VERSION "created by canmatrix"

NS_ :

BS_:

BU_: RR LR ADCU

BO_ 521 LR_Object_16_17: 64 LR
 SG_ AabsX_Obj_16 : 16|9@0+ (0.125,-31.875) [-31.875|32] "m/s^2"  ADCU
 SG_ AabsX_Obj_17 : 248|9@0+ (0.125,-31.875) [-31.875|32] "m/s^2"  ADCU
 SG_ AabsXStd_Obj_16 : 89|7@0+ (0.25,0) [0|31.75] "m/s^2"  ADCU
 SG_ AabsXStd_Obj_17 : 321|7@0+ (0.25,0) [0|31.75] "m/s^2"  ADCU
 SG_ AabsY_Obj_16 : 48|9@0+ (0.125,-31.875) [-31.875|32] "m/s^2"  ADCU
 SG_ AabsY_Obj_17 : 280|9@0+ (0.125,-31.875) [-31.875|32] "m/s^2"  ADCU
 SG_ AabsYStd_Obj_16 : 111|8@0+ (0.25,0) [0|63.75] "m/s^2"  ADCU
 SG_ AabsYStd_Obj_17 : 343|8@0+ (0.25,0) [0|63.75] "m/s^2"  ADCU
 SG_ ClassConf_Obj_16 : 119|7@0+ (1,0) [0|127] "%"  ADCU
 SG_ ClassConf_Obj_17 : 351|7@0+ (1,0) [0|127] "%"  ADCU
 SG_ Classification_Obj_16 : 98|3@0+ (1,0) [0|7] ""  ADCU
 SG_ Classification_Obj_17 : 330|3@0+ (1,0) [0|7] ""  ADCU
 SG_ CRC16_Checksum_Obj_16_17 : 503|16@0+ (1,0) [0|65535] ""  ADCU
 SG_ DistX_Obj_16 : 7|12@0+ (0.1,-200) [-200|209.5] "m"  ADCU
 SG_ DistX_Obj_17 : 239|12@0+ (0.1,-200) [-200|209.5] "m"  ADCU
 SG_ DistXStd_Obj_16 : 71|8@0+ (0.05,0) [0|12.75] "m"  ADCU
 SG_ DistXStd_Obj_17 : 303|8@0+ (0.05,0) [0|12.75] "m"  ADCU
 SG_ DistY_Obj_16 : 39|12@0+ (0.1,-200) [-200|209.5] "m"  ADCU
 SG_ DistY_Obj_17 : 271|12@0+ (0.1,-200) [-200|209.5] "m"  ADCU
 SG_ DistYStd_Obj_16 : 79|8@0+ (0.1,0) [0|25.5] "m"  ADCU
 SG_ DistYStd_Obj_17 : 311|8@0+ (0.1,0) [0|25.5] "m"  ADCU
 SG_ DynConf_Obj_16 : 121|7@0+ (1,0) [0|127] "%"  ADCU
 SG_ DynConf_Obj_17 : 353|7@0+ (1,0) [0|127] "%"  ADCU
 SG_ DynProp_Obj_16 : 130|3@0+ (1,0) [0|7] ""  ADCU
 SG_ DynProp_Obj_17 : 362|3@0+ (1,0) [0|7] ""  ADCU
 SG_ ID_Obj_16 : 209|8@0+ (1,0) [0|255] ""  ADCU
 SG_ ID_Obj_17 : 441|8@0+ (1,0) [0|255] ""  ADCU
 SG_ Length_Obj_16 : 136|7@0+ (0.2,0) [0|25.4] "m"  ADCU
 SG_ Length_Obj_17 : 368|7@0+ (0.2,0) [0|25.4] "m"  ADCU
 SG_ LifeCycle_Obj_16 : 193|16@0+ (1,0) [0|65535] ""  ADCU
 SG_ LifeCycle_Obj_17 : 425|16@0+ (1,0) [0|65535] ""  ADCU
 SG_ MaintenanceState_Obj_16 : 145|2@0+ (1,0) [0|3] ""  ADCU
 SG_ MaintenanceState_Obj_17 : 377|2@0+ (1,0) [0|3] ""  ADCU
 SG_ MicroDopplerFlag_16 : 472|1@0+ (1,0) [0|1] ""  ADCU
 SG_ MicroDopplerFlag_17 : 480|1@0+ (1,0) [0|1] ""  ADCU
 SG_ MirrorProb_Obj_16 : 143|7@0+ (1,0) [0|127] "%"  ADCU
 SG_ MirrorProb_Obj_17 : 375|7@0+ (1,0) [0|127] "%"  ADCU
 SG_ MsgCounter_Obj_16_17 : 495|8@0+ (1,0) [0|255] ""  ADCU
 SG_ ObstacleProb_Obj_16 : 479|7@0+ (1,0) [0|127] "%"  ADCU
 SG_ ObstacleProb_Obj_17 : 487|7@0+ (1,0) [0|127] "%"  ADCU
 SG_ Orientation_Obj_16 : 175|10@0+ (0.01,-5.11) [-5.11|5.12] "rad"  ADCU
 SG_ Orientation_Obj_17 : 407|10@0+ (0.01,-5.11) [-5.11|5.12] "rad"  ADCU
 SG_ OrientationStd_Obj_16 : 471|4@0+ (0.002,0) [0|0.03] "rad"  ADCU
 SG_ OrientationStd_Obj_17 : 467|4@0+ (0.002,0) [0|0.03] "rad"  ADCU
 SG_ ProbOfExist_Obj_16 : 112|7@0+ (1,0) [0|127] "%"  ADCU
 SG_ ProbOfExist_Obj_17 : 344|7@0+ (1,0) [0|127] "%"  ADCU
 SG_ RCS_Obj_16 : 152|9@0+ (0.2,-51.1) [-51.1|51.1] "dBsm"  ADCU
 SG_ RCS_Obj_17 : 384|9@0+ (0.2,-51.1) [-51.1|51.1] "dBsm"  ADCU
 SG_ RefPoint_Obj_16 : 217|4@0+ (1,0) [0|15] ""  ADCU
 SG_ RefPoint_Obj_17 : 449|4@0+ (1,0) [0|15] ""  ADCU
 SG_ VabsX_Obj_16 : 11|11@0+ (0.125,-128) [-128|127.875] "m/s"  ADCU
 SG_ VabsX_Obj_17 : 243|11@0+ (0.125,-128) [-128|127.875] "m/s"  ADCU
 SG_ VabsXStd_Obj_16 : 87|7@0+ (0.1,0) [0|12.7] "m/s"  ADCU
 SG_ VabsXStd_Obj_17 : 319|7@0+ (0.1,0) [0|12.7] "m/s"  ADCU
 SG_ VabsY_Obj_16 : 43|11@0+ (0.125,-128) [-128|127.875] "m/s"  ADCU
 SG_ VabsY_Obj_17 : 275|11@0+ (0.125,-128) [-128|127.875] "m/s"  ADCU
 SG_ VabsYStd_Obj_16 : 80|7@0+ (0.2,0) [0|25.4] "m/s"  ADCU
 SG_ VabsYStd_Obj_17 : 312|7@0+ (0.2,0) [0|25.4] "m/s"  ADCU
 SG_ Valid_Obj_16 : 229|1@0+ (1,0) [0|1] ""  ADCU
 SG_ Valid_Obj_17 : 461|1@0+ (1,0) [0|1] ""  ADCU
 SG_ Width_Obj_16 : 159|7@0+ (0.2,0) [0|25.4] "m"  ADCU
 SG_ Width_Obj_17 : 391|7@0+ (0.2,0) [0|25.4] "m"  ADCU
 SG_ YawRateAbs_Obj_16 : 181|10@0+ (0.001,-0.511) [-0.511|0.512] "rad/s"  ADCU
 SG_ YawRateAbs_Obj_17 : 413|10@0+ (0.001,-0.511) [-0.511|0.512] "rad/s"  ADCU
 SG_ YawRateAbsStd_Obj_16 : 187|10@0+ (0.0001,0) [0|0.1023] "rad/s"  ADCU
 SG_ YawRateAbsStd_Obj_17 : 419|10@0+ (0.0001,0) [0|0.1023] "rad/s"  ADCU

BO_ 522 LR_Object_18_19: 64 LR
 SG_ AabsX_Obj_18 : 16|9@0+ (0.125,-31.875) [-31.875|32] "m/s^2"  ADCU
 SG_ AabsX_Obj_19 : 248|9@0+ (0.125,-31.875) [-31.875|32] "m/s^2"  ADCU
 SG_ AabsXStd_Obj_18 : 89|7@0+ (0.25,0) [0|31.75] "m/s^2"  ADCU
 SG_ AabsXStd_Obj_19 : 321|7@0+ (0.25,0) [0|31.75] "m/s^2"  ADCU
 SG_ AabsY_Obj_18 : 48|9@0+ (0.125,-31.875) [-31.875|32] "m/s^2"  ADCU
 SG_ AabsY_Obj_19 : 280|9@0+ (0.125,-31.875) [-31.875|32] "m/s^2"  ADCU
 SG_ AabsYStd_Obj_18 : 111|8@0+ (0.25,0) [0|63.75] "m/s^2"  ADCU
 SG_ AabsYStd_Obj_19 : 343|8@0+ (0.25,0) [0|63.75] "m/s^2"  ADCU
 SG_ ClassConf_Obj_18 : 119|7@0+ (1,0) [0|127] "%"  ADCU
 SG_ ClassConf_Obj_19 : 351|7@0+ (1,0) [0|127] "%"  ADCU
 SG_ Classification_Obj_18 : 98|3@0+ (1,0) [0|7] ""  ADCU
 SG_ Classification_Obj_19 : 330|3@0+ (1,0) [0|7] ""  ADCU
 SG_ CRC16_Checksum_Obj_18_19 : 503|16@0+ (1,0) [0|65535] ""  ADCU
 SG_ DistX_Obj_18 : 7|12@0+ (0.1,-200) [-200|209.5] "m"  ADCU
 SG_ DistX_Obj_19 : 239|12@0+ (0.1,-200) [-200|209.5] "m"  ADCU
 SG_ DistXStd_Obj_18 : 71|8@0+ (0.05,0) [0|12.75] "m"  ADCU
 SG_ DistXStd_Obj_19 : 303|8@0+ (0.05,0) [0|12.75] "m"  ADCU
 SG_ DistY_Obj_18 : 39|12@0+ (0.1,-200) [-200|209.5] "m"  ADCU
 SG_ DistY_Obj_19 : 271|12@0+ (0.1,-200) [-200|209.5] "m"  ADCU
 SG_ DistYStd_Obj_18 : 79|8@0+ (0.1,0) [0|25.5] "m"  ADCU
 SG_ DistYStd_Obj_19 : 311|8@0+ (0.1,0) [0|25.5] "m"  ADCU
 SG_ DynConf_Obj_18 : 121|7@0+ (1,0) [0|127] "%"  ADCU
 SG_ DynConf_Obj_19 : 353|7@0+ (1,0) [0|127] "%"  ADCU
 SG_ DynProp_Obj_18 : 130|3@0+ (1,0) [0|7] ""  ADCU
 SG_ DynProp_Obj_19 : 362|3@0+ (1,0) [0|7] ""  ADCU
 SG_ ID_Obj_18 : 209|8@0+ (1,0) [0|255] ""  ADCU
 SG_ ID_Obj_19 : 441|8@0+ (1,0) [0|255] ""  ADCU
 SG_ Length_Obj_18 : 136|7@0+ (0.2,0) [0|25.4] "m"  ADCU
 SG_ Length_Obj_19 : 368|7@0+ (0.2,0) [0|25.4] "m"  ADCU
 SG_ LifeCycle_Obj_18 : 193|16@0+ (1,0) [0|65535] ""  ADCU
 SG_ LifeCycle_Obj_19 : 425|16@0+ (1,0) [0|65535] ""  ADCU
 SG_ MaintenanceState_Obj_18 : 145|2@0+ (1,0) [0|3] ""  ADCU
 SG_ MaintenanceState_Obj_19 : 377|2@0+ (1,0) [0|3] ""  ADCU
 SG_ MicroDopplerFlag_18 : 472|1@0+ (1,0) [0|1] ""  ADCU
 SG_ MicroDopplerFlag_19 : 480|1@0+ (1,0) [0|1] ""  ADCU
 SG_ MirrorProb_Obj_18 : 143|7@0+ (1,0) [0|127] "%"  ADCU
 SG_ MirrorProb_Obj_19 : 375|7@0+ (1,0) [0|127] "%"  ADCU
 SG_ MsgCounter_Obj_18_19 : 495|8@0+ (1,0) [0|255] ""  ADCU
 SG_ ObstacleProb_Obj_18 : 479|7@0+ (1,0) [0|127] "%"  ADCU
 SG_ ObstacleProb_Obj_19 : 487|7@0+ (1,0) [0|127] "%"  ADCU
 SG_ Orientation_Obj_18 : 175|10@0+ (0.01,-5.11) [-5.11|5.12] "rad"  ADCU
 SG_ Orientation_Obj_19 : 407|10@0+ (0.01,-5.11) [-5.11|5.12] "rad"  ADCU
 SG_ OrientationStd_Obj_18 : 471|4@0+ (0.002,0) [0|0.03] "rad"  ADCU
 SG_ OrientationStd_Obj_19 : 467|4@0+ (0.002,0) [0|0.03] "rad"  ADCU
 SG_ ProbOfExist_Obj_18 : 112|7@0+ (1,0) [0|127] "%"  ADCU
 SG_ ProbOfExist_Obj_19 : 344|7@0+ (1,0) [0|127] "%"  ADCU
 SG_ RCS_Obj_18 : 152|9@0+ (0.2,-51.1) [-51.1|51.1] "dBsm"  ADCU
 SG_ RCS_Obj_19 : 384|9@0+ (0.2,-51.1) [-51.1|51.1] "dBsm"  ADCU
 SG_ RefPoint_Obj_18 : 217|4@0+ (1,0) [0|15] ""  ADCU
 SG_ RefPoint_Obj_19 : 449|4@0+ (1,0) [0|15] ""  ADCU
 SG_ VabsX_Obj_18 : 11|11@0+ (0.125,-128) [-128|127.875] "m/s"  ADCU
 SG_ VabsX_Obj_19 : 243|11@0+ (0.125,-128) [-128|127.875] "m/s"  ADCU
 SG_ VabsXStd_Obj_18 : 87|7@0+ (0.1,0) [0|12.7] "m/s"  ADCU
 SG_ VabsXStd_Obj_19 : 319|7@0+ (0.1,0) [0|12.7] "m/s"  ADCU
 SG_ VabsY_Obj_18 : 43|11@0+ (0.125,-128) [-128|127.875] "m/s"  ADCU
 SG_ VabsY_Obj_19 : 275|11@0+ (0.125,-128) [-128|127.875] "m/s"  ADCU
 SG_ VabsYStd_Obj_18 : 80|7@0+ (0.2,0) [0|25.4] "m/s"  ADCU
 SG_ VabsYStd_Obj_19 : 312|7@0+ (0.2,0) [0|25.4] "m/s"  ADCU
 SG_ Valid_Obj_18 : 229|1@0+ (1,0) [0|1] ""  ADCU
 SG_ Valid_Obj_19 : 461|1@0+ (1,0) [0|1] ""  ADCU
 SG_ Width_Obj_18 : 159|7@0+ (0.2,0) [0|25.4] "m"  ADCU
 SG_ Width_Obj_19 : 391|7@0+ (0.2,0) [0|25.4] "m"  ADCU
 SG_ YawRateAbs_Obj_18 : 181|10@0+ (0.001,-0.511) [-0.511|0.512] "rad/s"  ADCU
 SG_ YawRateAbs_Obj_19 : 413|10@0+ (0.001,-0.511) [-0.511|0.512] "rad/s"  ADCU
 SG_ YawRateAbsStd_Obj_18 : 187|10@0+ (0.0001,0) [0|0.1023] "rad/s"  ADCU
 SG_ YawRateAbsStd_Obj_19 : 419|10@0+ (0.0001,0) [0|0.1023] "rad/s"  ADCU

BO_ 523 LR_Object_20_21: 64 LR
 SG_ AabsX_Obj_20 : 16|9@0+ (0.125,-31.875) [-31.875|32] "m/s^2"  ADCU
 SG_ AabsX_Obj_21 : 248|9@0+ (0.125,-31.875) [-31.875|32] "m/s^2"  ADCU
 SG_ AabsXStd_Obj_20 : 89|7@0+ (0.25,0) [0|31.75] "m/s^2"  ADCU
 SG_ AabsXStd_Obj_21 : 321|7@0+ (0.25,0) [0|31.75] "m/s^2"  ADCU
 SG_ AabsY_Obj_20 : 48|9@0+ (0.125,-31.875) [-31.875|32] "m/s^2"  ADCU
 SG_ AabsY_Obj_21 : 280|9@0+ (0.125,-31.875) [-31.875|32] "m/s^2"  ADCU
 SG_ AabsYStd_Obj_20 : 111|8@0+ (0.25,0) [0|63.75] "m/s^2"  ADCU
 SG_ AabsYStd_Obj_21 : 343|8@0+ (0.25,0) [0|63.75] "m/s^2"  ADCU
 SG_ ClassConf_Obj_20 : 119|7@0+ (1,0) [0|127] "%"  ADCU
 SG_ ClassConf_Obj_21 : 351|7@0+ (1,0) [0|127] "%"  ADCU
 SG_ Classification_Obj_20 : 98|3@0+ (1,0) [0|7] ""  ADCU
 SG_ Classification_Obj_21 : 330|3@0+ (1,0) [0|7] ""  ADCU
 SG_ CRC16_Checksum_Obj_20_21 : 503|16@0+ (1,0) [0|65535] ""  ADCU
 SG_ DistX_Obj_20 : 7|12@0+ (0.1,-200) [-200|209.5] "m"  ADCU
 SG_ DistX_Obj_21 : 239|12@0+ (0.1,-200) [-200|209.5] "m"  ADCU
 SG_ DistXStd_Obj_20 : 71|8@0+ (0.05,0) [0|12.75] "m"  ADCU
 SG_ DistXStd_Obj_21 : 303|8@0+ (0.05,0) [0|12.75] "m"  ADCU
 SG_ DistY_Obj_20 : 39|12@0+ (0.1,-200) [-200|209.5] "m"  ADCU
 SG_ DistY_Obj_21 : 271|12@0+ (0.1,-200) [-200|209.5] "m"  ADCU
 SG_ DistYStd_Obj_20 : 79|8@0+ (0.1,0) [0|25.5] "m"  ADCU
 SG_ DistYStd_Obj_21 : 311|8@0+ (0.1,0) [0|25.5] "m"  ADCU
 SG_ DynConf_Obj_20 : 121|7@0+ (1,0) [0|127] "%"  ADCU
 SG_ DynConf_Obj_21 : 353|7@0+ (1,0) [0|127] "%"  ADCU
 SG_ DynProp_Obj_20 : 130|3@0+ (1,0) [0|7] ""  ADCU
 SG_ DynProp_Obj_21 : 362|3@0+ (1,0) [0|7] ""  ADCU
 SG_ ID_Obj_20 : 209|8@0+ (1,0) [0|255] ""  ADCU
 SG_ ID_Obj_21 : 441|8@0+ (1,0) [0|255] ""  ADCU
 SG_ Length_Obj_20 : 136|7@0+ (0.2,0) [0|25.4] "m"  ADCU
 SG_ Length_Obj_21 : 368|7@0+ (0.2,0) [0|25.4] "m"  ADCU
 SG_ LifeCycle_Obj_20 : 193|16@0+ (1,0) [0|65535] ""  ADCU
 SG_ LifeCycle_Obj_21 : 425|16@0+ (1,0) [0|65535] ""  ADCU
 SG_ MaintenanceState_Obj_20 : 145|2@0+ (1,0) [0|3] ""  ADCU
 SG_ MaintenanceState_Obj_21 : 377|2@0+ (1,0) [0|3] ""  ADCU
 SG_ MicroDopplerFlag_20 : 472|1@0+ (1,0) [0|1] ""  ADCU
 SG_ MicroDopplerFlag_21 : 480|1@0+ (1,0) [0|1] ""  ADCU
 SG_ MirrorProb_Obj_20 : 143|7@0+ (1,0) [0|127] "%"  ADCU
 SG_ MirrorProb_Obj_21 : 375|7@0+ (1,0) [0|127] "%"  ADCU
 SG_ MsgCounter_Obj_20_21 : 495|8@0+ (1,0) [0|255] ""  ADCU
 SG_ ObstacleProb_Obj_20 : 479|7@0+ (1,0) [0|127] "%"  ADCU
 SG_ ObstacleProb_Obj_21 : 487|7@0+ (1,0) [0|127] "%"  ADCU
 SG_ Orientation_Obj_20 : 175|10@0+ (0.01,-5.11) [-5.11|5.12] "rad"  ADCU
 SG_ Orientation_Obj_21 : 407|10@0+ (0.01,-5.11) [-5.11|5.12] "rad"  ADCU
 SG_ OrientationStd_Obj_20 : 471|4@0+ (0.002,0) [0|0.03] "rad"  ADCU
 SG_ OrientationStd_Obj_21 : 467|4@0+ (0.002,0) [0|0.03] "rad"  ADCU
 SG_ ProbOfExist_Obj_20 : 112|7@0+ (1,0) [0|127] "%"  ADCU
 SG_ ProbOfExist_Obj_21 : 344|7@0+ (1,0) [0|127] "%"  ADCU
 SG_ RCS_Obj_20 : 152|9@0+ (0.2,-51.1) [-51.1|51.1] "dBsm"  ADCU
 SG_ RCS_Obj_21 : 384|9@0+ (0.2,-51.1) [-51.1|51.1] "dBsm"  ADCU
 SG_ RefPoint_Obj_20 : 217|4@0+ (1,0) [0|15] ""  ADCU
 SG_ RefPoint_Obj_21 : 449|4@0+ (1,0) [0|15] ""  ADCU
 SG_ VabsX_Obj_20 : 11|11@0+ (0.125,-128) [-128|127.875] "m/s"  ADCU
 SG_ VabsX_Obj_21 : 243|11@0+ (0.125,-128) [-128|127.875] "m/s"  ADCU
 SG_ VabsXStd_Obj_20 : 87|7@0+ (0.1,0) [0|12.7] "m/s"  ADCU
 SG_ VabsXStd_Obj_21 : 319|7@0+ (0.1,0) [0|12.7] "m/s"  ADCU
 SG_ VabsY_Obj_20 : 43|11@0+ (0.125,-128) [-128|127.875] "m/s"  ADCU
 SG_ VabsY_Obj_21 : 275|11@0+ (0.125,-128) [-128|127.875] "m/s"  ADCU
 SG_ VabsYStd_Obj_20 : 80|7@0+ (0.2,0) [0|25.4] "m/s"  ADCU
 SG_ VabsYStd_Obj_21 : 312|7@0+ (0.2,0) [0|25.4] "m/s"  ADCU
 SG_ Valid_Obj_20 : 229|1@0+ (1,0) [0|1] ""  ADCU
 SG_ Valid_Obj_21 : 461|1@0+ (1,0) [0|1] ""  ADCU
 SG_ Width_Obj_20 : 159|7@0+ (0.2,0) [0|25.4] "m"  ADCU
 SG_ Width_Obj_21 : 391|7@0+ (0.2,0) [0|25.4] "m"  ADCU
 SG_ YawRateAbs_Obj_20 : 181|10@0+ (0.001,-0.511) [-0.511|0.512] "rad/s"  ADCU
 SG_ YawRateAbs_Obj_21 : 413|10@0+ (0.001,-0.511) [-0.511|0.512] "rad/s"  ADCU
 SG_ YawRateAbsStd_Obj_20 : 187|10@0+ (0.0001,0) [0|0.1023] "rad/s"  ADCU
 SG_ YawRateAbsStd_Obj_21 : 419|10@0+ (0.0001,0) [0|0.1023] "rad/s"  ADCU

BO_ 524 LR_Object_22_23: 64 LR
 SG_ AabsX_Obj_22 : 16|9@0+ (0.125,-31.875) [-31.875|32] "m/s^2"  ADCU
 SG_ AabsX_Obj_23 : 248|9@0+ (0.125,-31.875) [-31.875|32] "m/s^2"  ADCU
 SG_ AabsXStd_Obj_22 : 89|7@0+ (0.25,0) [0|31.75] "m/s^2"  ADCU
 SG_ AabsXStd_Obj_23 : 321|7@0+ (0.25,0) [0|31.75] "m/s^2"  ADCU
 SG_ AabsY_Obj_22 : 48|9@0+ (0.125,-31.875) [-31.875|32] "m/s^2"  ADCU
 SG_ AabsY_Obj_23 : 280|9@0+ (0.125,-31.875) [-31.875|32] "m/s^2"  ADCU
 SG_ AabsYStd_Obj_22 : 111|8@0+ (0.25,0) [0|63.75] "m/s^2"  ADCU
 SG_ AabsYStd_Obj_23 : 343|8@0+ (0.25,0) [0|63.75] "m/s^2"  ADCU
 SG_ ClassConf_Obj_22 : 119|7@0+ (1,0) [0|127] "%"  ADCU
 SG_ ClassConf_Obj_23 : 351|7@0+ (1,0) [0|127] "%"  ADCU
 SG_ Classification_Obj_22 : 98|3@0+ (1,0) [0|7] ""  ADCU
 SG_ Classification_Obj_23 : 330|3@0+ (1,0) [0|7] ""  ADCU
 SG_ CRC16_Checksum_Obj_22_23 : 503|16@0+ (1,0) [0|65535] ""  ADCU
 SG_ DistX_Obj_22 : 7|12@0+ (0.1,-200) [-200|209.5] "m"  ADCU
 SG_ DistX_Obj_23 : 239|12@0+ (0.1,-200) [-200|209.5] "m"  ADCU
 SG_ DistXStd_Obj_22 : 71|8@0+ (0.05,0) [0|12.75] "m"  ADCU
 SG_ DistXStd_Obj_23 : 303|8@0+ (0.05,0) [0|12.75] "m"  ADCU
 SG_ DistY_Obj_22 : 39|12@0+ (0.1,-200) [-200|209.5] "m"  ADCU
 SG_ DistY_Obj_23 : 271|12@0+ (0.1,-200) [-200|209.5] "m"  ADCU
 SG_ DistYStd_Obj_22 : 79|8@0+ (0.1,0) [0|25.5] "m"  ADCU
 SG_ DistYStd_Obj_23 : 311|8@0+ (0.1,0) [0|25.5] "m"  ADCU
 SG_ DynConf_Obj_22 : 121|7@0+ (1,0) [0|127] "%"  ADCU
 SG_ DynConf_Obj_23 : 353|7@0+ (1,0) [0|127] "%"  ADCU
 SG_ DynProp_Obj_22 : 130|3@0+ (1,0) [0|7] ""  ADCU
 SG_ DynProp_Obj_23 : 362|3@0+ (1,0) [0|7] ""  ADCU
 SG_ ID_Obj_22 : 209|8@0+ (1,0) [0|255] ""  ADCU
 SG_ ID_Obj_23 : 441|8@0+ (1,0) [0|255] ""  ADCU
 SG_ Length_Obj_22 : 136|7@0+ (0.2,0) [0|25.4] "m"  ADCU
 SG_ Length_Obj_23 : 368|7@0+ (0.2,0) [0|25.4] "m"  ADCU
 SG_ LifeCycle_Obj_22 : 193|16@0+ (1,0) [0|65535] ""  ADCU
 SG_ LifeCycle_Obj_23 : 425|16@0+ (1,0) [0|65535] ""  ADCU
 SG_ MaintenanceState_Obj_22 : 145|2@0+ (1,0) [0|3] ""  ADCU
 SG_ MaintenanceState_Obj_23 : 377|2@0+ (1,0) [0|3] ""  ADCU
 SG_ MicroDopplerFlag_22 : 472|1@0+ (1,0) [0|1] ""  ADCU
 SG_ MicroDopplerFlag_23 : 480|1@0+ (1,0) [0|1] ""  ADCU
 SG_ MirrorProb_Obj_22 : 143|7@0+ (1,0) [0|127] "%"  ADCU
 SG_ MirrorProb_Obj_23 : 375|7@0+ (1,0) [0|127] "%"  ADCU
 SG_ MsgCounter_Obj_00_23 : 495|8@0+ (1,0) [0|255] ""  ADCU
 SG_ ObstacleProb_Obj_22 : 479|7@0+ (1,0) [0|127] "%"  ADCU
 SG_ ObstacleProb_Obj_23 : 487|7@0+ (1,0) [0|127] "%"  ADCU
 SG_ Orientation_Obj_22 : 175|10@0+ (0.01,-5.11) [-5.11|5.12] "rad"  ADCU
 SG_ Orientation_Obj_23 : 407|10@0+ (0.01,-5.11) [-5.11|5.12] "rad"  ADCU
 SG_ OrientationStd_Obj_22 : 471|4@0+ (0.002,0) [0|0.03] "rad"  ADCU
 SG_ OrientationStd_Obj_23 : 467|4@0+ (0.002,0) [0|0.03] "rad"  ADCU
 SG_ ProbOfExist_Obj_22 : 112|7@0+ (1,0) [0|127] "%"  ADCU
 SG_ ProbOfExist_Obj_23 : 344|7@0+ (1,0) [0|127] "%"  ADCU
 SG_ RCS_Obj_22 : 152|9@0+ (0.2,-51.1) [-51.1|51.1] "dBsm"  ADCU
 SG_ RCS_Obj_23 : 384|9@0+ (0.2,-51.1) [-51.1|51.1] "dBsm"  ADCU
 SG_ RefPoint_Obj_22 : 217|4@0+ (1,0) [0|15] ""  ADCU
 SG_ RefPoint_Obj_23 : 449|4@0+ (1,0) [0|15] ""  ADCU
 SG_ VabsX_Obj_22 : 11|11@0+ (0.125,-128) [-128|127.875] "m/s"  ADCU
 SG_ VabsX_Obj_23 : 243|11@0+ (0.125,-128) [-128|127.875] "m/s"  ADCU
 SG_ VabsXStd_Obj_22 : 87|7@0+ (0.1,0) [0|12.7] "m/s"  ADCU
 SG_ VabsXStd_Obj_23 : 319|7@0+ (0.1,0) [0|12.7] "m/s"  ADCU
 SG_ VabsY_Obj_22 : 43|11@0+ (0.125,-128) [-128|127.875] "m/s"  ADCU
 SG_ VabsY_Obj_23 : 275|11@0+ (0.125,-128) [-128|127.875] "m/s"  ADCU
 SG_ VabsYStd_Obj_22 : 80|7@0+ (0.2,0) [0|25.4] "m/s"  ADCU
 SG_ VabsYStd_Obj_23 : 312|7@0+ (0.2,0) [0|25.4] "m/s"  ADCU
 SG_ Valid_Obj_22 : 229|1@0+ (1,0) [0|1] ""  ADCU
 SG_ Valid_Obj_23 : 461|1@0+ (1,0) [0|1] ""  ADCU
 SG_ Width_Obj_22 : 159|7@0+ (0.2,0) [0|25.4] "m"  ADCU
 SG_ Width_Obj_23 : 391|7@0+ (0.2,0) [0|25.4] "m"  ADCU
 SG_ YawRateAbs_Obj_22 : 181|10@0+ (0.001,-0.511) [-0.511|0.512] "rad/s"  ADCU
 SG_ YawRateAbs_Obj_23 : 413|10@0+ (0.001,-0.511) [-0.511|0.512] "rad/s"  ADCU
 SG_ YawRateAbsStd_Obj_22 : 187|10@0+ (0.0001,0) [0|0.1023] "rad/s"  ADCU
 SG_ YawRateAbsStd_Obj_23 : 419|10@0+ (0.0001,0) [0|0.1023] "rad/s"  ADCU

BO_ 525 LR_Object_24_25: 64 LR
 SG_ AabsX_Obj_24 : 16|9@0+ (0.125,-31.875) [-31.875|32] "m/s^2"  ADCU
 SG_ AabsX_Obj_25 : 248|9@0+ (0.125,-31.875) [-31.875|32] "m/s^2"  ADCU
 SG_ AabsXStd_Obj_24 : 89|7@0+ (0.25,0) [0|31.75] "m/s^2"  ADCU
 SG_ AabsXStd_Obj_25 : 321|7@0+ (0.25,0) [0|31.75] "m/s^2"  ADCU
 SG_ AabsY_Obj_24 : 48|9@0+ (0.125,-31.875) [-31.875|32] "m/s^2"  ADCU
 SG_ AabsY_Obj_25 : 280|9@0+ (0.125,-31.875) [-31.875|32] "m/s^2"  ADCU
 SG_ AabsYStd_Obj_24 : 111|8@0+ (0.25,0) [0|63.75] "m/s^2"  ADCU
 SG_ AabsYStd_Obj_25 : 343|8@0+ (0.25,0) [0|63.75] "m/s^2"  ADCU
 SG_ ClassConf_Obj_24 : 119|7@0+ (1,0) [0|127] "%"  ADCU
 SG_ ClassConf_Obj_25 : 351|7@0+ (1,0) [0|127] "%"  ADCU
 SG_ Classification_Obj_24 : 98|3@0+ (1,0) [0|7] ""  ADCU
 SG_ Classification_Obj_25 : 330|3@0+ (1,0) [0|7] ""  ADCU
 SG_ CRC16_Checksum_Obj_24_25 : 503|16@0+ (1,0) [0|65535] ""  ADCU
 SG_ DistX_Obj_24 : 7|12@0+ (0.1,-200) [-200|209.5] "m"  ADCU
 SG_ DistX_Obj_25 : 239|12@0+ (0.1,-200) [-200|209.5] "m"  ADCU
 SG_ DistXStd_Obj_24 : 71|8@0+ (0.05,0) [0|12.75] "m"  ADCU
 SG_ DistXStd_Obj_25 : 303|8@0+ (0.05,0) [0|12.75] "m"  ADCU
 SG_ DistY_Obj_24 : 39|12@0+ (0.1,-200) [-200|209.5] "m"  ADCU
 SG_ DistY_Obj_25 : 271|12@0+ (0.1,-200) [-200|209.5] "m"  ADCU
 SG_ DistYStd_Obj_24 : 79|8@0+ (0.1,0) [0|25.5] "m"  ADCU
 SG_ DistYStd_Obj_25 : 311|8@0+ (0.1,0) [0|25.5] "m"  ADCU
 SG_ DynConf_Obj_24 : 121|7@0+ (1,0) [0|127] "%"  ADCU
 SG_ DynConf_Obj_25 : 353|7@0+ (1,0) [0|127] "%"  ADCU
 SG_ DynProp_Obj_24 : 130|3@0+ (1,0) [0|7] ""  ADCU
 SG_ DynProp_Obj_25 : 362|3@0+ (1,0) [0|7] ""  ADCU
 SG_ ID_Obj_24 : 209|8@0+ (1,0) [0|255] ""  ADCU
 SG_ ID_Obj_25 : 441|8@0+ (1,0) [0|255] ""  ADCU
 SG_ Length_Obj_24 : 136|7@0+ (0.2,0) [0|25.4] "m"  ADCU
 SG_ Length_Obj_25 : 368|7@0+ (0.2,0) [0|25.4] "m"  ADCU
 SG_ LifeCycle_Obj_24 : 193|16@0+ (1,0) [0|65535] ""  ADCU
 SG_ LifeCycle_Obj_25 : 425|16@0+ (1,0) [0|65535] ""  ADCU
 SG_ MaintenanceState_Obj_24 : 145|2@0+ (1,0) [0|3] ""  ADCU
 SG_ MaintenanceState_Obj_25 : 377|2@0+ (1,0) [0|3] ""  ADCU
 SG_ MicroDopplerFlag_24 : 472|1@0+ (1,0) [0|1] ""  ADCU
 SG_ MicroDopplerFlag_25 : 480|1@0+ (1,0) [0|1] ""  ADCU
 SG_ MirrorProb_Obj_24 : 143|7@0+ (1,0) [0|127] "%"  ADCU
 SG_ MirrorProb_Obj_25 : 375|7@0+ (1,0) [0|127] "%"  ADCU
 SG_ MsgCounter_Obj_24_25 : 495|8@0+ (1,0) [0|255] ""  ADCU
 SG_ ObstacleProb_Obj_24 : 479|7@0+ (1,0) [0|127] "%"  ADCU
 SG_ ObstacleProb_Obj_25 : 487|7@0+ (1,0) [0|127] "%"  ADCU
 SG_ Orientation_Obj_24 : 175|10@0+ (0.01,-5.11) [-5.11|5.12] "rad"  ADCU
 SG_ Orientation_Obj_25 : 407|10@0+ (0.01,-5.11) [-5.11|5.12] "rad"  ADCU
 SG_ OrientationStd_Obj_24 : 471|4@0+ (0.002,0) [0|0.03] "rad"  ADCU
 SG_ OrientationStd_Obj_25 : 467|4@0+ (0.002,0) [0|0.03] "rad"  ADCU
 SG_ ProbOfExist_Obj_24 : 112|7@0+ (1,0) [0|127] "%"  ADCU
 SG_ ProbOfExist_Obj_25 : 344|7@0+ (1,0) [0|127] "%"  ADCU
 SG_ RCS_Obj_24 : 152|9@0+ (0.2,-51.1) [-51.1|51.1] "dBsm"  ADCU
 SG_ RCS_Obj_25 : 384|9@0+ (0.2,-51.1) [-51.1|51.1] "dBsm"  ADCU
 SG_ RefPoint_Obj_24 : 217|4@0+ (1,0) [0|15] ""  ADCU
 SG_ RefPoint_Obj_25 : 449|4@0+ (1,0) [0|15] ""  ADCU
 SG_ VabsX_Obj_24 : 11|11@0+ (0.125,-128) [-128|127.875] "m/s"  ADCU
 SG_ VabsX_Obj_25 : 243|11@0+ (0.125,-128) [-128|127.875] "m/s"  ADCU
 SG_ VabsXStd_Obj_24 : 87|7@0+ (0.1,0) [0|12.7] "m/s"  ADCU
 SG_ VabsXStd_Obj_25 : 319|7@0+ (0.1,0) [0|12.7] "m/s"  ADCU
 SG_ VabsY_Obj_24 : 43|11@0+ (0.125,-128) [-128|127.875] "m/s"  ADCU
 SG_ VabsY_Obj_25 : 275|11@0+ (0.125,-128) [-128|127.875] "m/s"  ADCU
 SG_ VabsYStd_Obj_24 : 80|7@0+ (0.2,0) [0|25.4] "m/s"  ADCU
 SG_ VabsYStd_Obj_25 : 312|7@0+ (0.2,0) [0|25.4] "m/s"  ADCU
 SG_ Valid_Obj_24 : 229|1@0+ (1,0) [0|1] ""  ADCU
 SG_ Valid_Obj_25 : 461|1@0+ (1,0) [0|1] ""  ADCU
 SG_ Width_Obj_24 : 159|7@0+ (0.2,0) [0|25.4] "m"  ADCU
 SG_ Width_Obj_25 : 391|7@0+ (0.2,0) [0|25.4] "m"  ADCU
 SG_ YawRateAbs_Obj_24 : 181|10@0+ (0.001,-0.511) [-0.511|0.512] "rad/s"  ADCU
 SG_ YawRateAbs_Obj_25 : 413|10@0+ (0.001,-0.511) [-0.511|0.512] "rad/s"  ADCU
 SG_ YawRateAbsStd_Obj_24 : 187|10@0+ (0.0001,0) [0|0.1023] "rad/s"  ADCU
 SG_ YawRateAbsStd_Obj_25 : 419|10@0+ (0.0001,0) [0|0.1023] "rad/s"  ADCU

BO_ 526 LR_Object_26_27: 64 LR
 SG_ AabsX_Obj_26 : 16|9@0+ (0.125,-31.875) [-31.875|32] "m/s^2"  ADCU
 SG_ AabsX_Obj_27 : 248|9@0+ (0.125,-31.875) [-31.875|32] "m/s^2"  ADCU
 SG_ AabsXStd_Obj_26 : 89|7@0+ (0.25,0) [0|31.75] "m/s^2"  ADCU
 SG_ AabsXStd_Obj_27 : 321|7@0+ (0.25,0) [0|31.75] "m/s^2"  ADCU
 SG_ AabsY_Obj_26 : 48|9@0+ (0.125,-31.875) [-31.875|32] "m/s^2"  ADCU
 SG_ AabsY_Obj_27 : 280|9@0+ (0.125,-31.875) [-31.875|32] "m/s^2"  ADCU
 SG_ AabsYStd_Obj_26 : 111|8@0+ (0.25,0) [0|63.75] "m/s^2"  ADCU
 SG_ AabsYStd_Obj_27 : 343|8@0+ (0.25,0) [0|63.75] "m/s^2"  ADCU
 SG_ ClassConf_Obj_26 : 119|7@0+ (1,0) [0|127] "%"  ADCU
 SG_ ClassConf_Obj_27 : 351|7@0+ (1,0) [0|127] "%"  ADCU
 SG_ Classification_Obj_26 : 98|3@0+ (1,0) [0|7] ""  ADCU
 SG_ Classification_Obj_27 : 330|3@0+ (1,0) [0|7] ""  ADCU
 SG_ CRC16_Checksum_Obj_26_27 : 503|16@0+ (1,0) [0|65535] ""  ADCU
 SG_ DistX_Obj_26 : 7|12@0+ (0.1,-200) [-200|209.5] "m"  ADCU
 SG_ DistX_Obj_27 : 239|12@0+ (0.1,-200) [-200|209.5] "m"  ADCU
 SG_ DistXStd_Obj_26 : 71|8@0+ (0.05,0) [0|12.75] "m"  ADCU
 SG_ DistXStd_Obj_27 : 303|8@0+ (0.05,0) [0|12.75] "m"  ADCU
 SG_ DistY_Obj_26 : 39|12@0+ (0.1,-200) [-200|209.5] "m"  ADCU
 SG_ DistY_Obj_27 : 271|12@0+ (0.1,-200) [-200|209.5] "m"  ADCU
 SG_ DistYStd_Obj_26 : 79|8@0+ (0.1,0) [0|25.5] "m"  ADCU
 SG_ DistYStd_Obj_27 : 311|8@0+ (0.1,0) [0|25.5] "m"  ADCU
 SG_ DynConf_Obj_26 : 121|7@0+ (1,0) [0|127] "%"  ADCU
 SG_ DynConf_Obj_27 : 353|7@0+ (1,0) [0|127] "%"  ADCU
 SG_ DynProp_Obj_26 : 130|3@0+ (1,0) [0|7] ""  ADCU
 SG_ DynProp_Obj_27 : 362|3@0+ (1,0) [0|7] ""  ADCU
 SG_ ID_Obj_26 : 209|8@0+ (1,0) [0|255] ""  ADCU
 SG_ ID_Obj_27 : 441|8@0+ (1,0) [0|255] ""  ADCU
 SG_ Length_Obj_26 : 136|7@0+ (0.2,0) [0|25.4] "m"  ADCU
 SG_ Length_Obj_27 : 368|7@0+ (0.2,0) [0|25.4] "m"  ADCU
 SG_ LifeCycle_Obj_26 : 193|16@0+ (1,0) [0|65535] ""  ADCU
 SG_ LifeCycle_Obj_27 : 425|16@0+ (1,0) [0|65535] ""  ADCU
 SG_ MaintenanceState_Obj_26 : 145|2@0+ (1,0) [0|3] ""  ADCU
 SG_ MaintenanceState_Obj_27 : 377|2@0+ (1,0) [0|3] ""  ADCU
 SG_ MicroDopplerFlag_26 : 472|1@0+ (1,0) [0|1] ""  ADCU
 SG_ MicroDopplerFlag_27 : 480|1@0+ (1,0) [0|1] ""  ADCU
 SG_ MirrorProb_Obj_26 : 143|7@0+ (1,0) [0|127] "%"  ADCU
 SG_ MirrorProb_Obj_27 : 375|7@0+ (1,0) [0|127] "%"  ADCU
 SG_ MsgCounter_Obj_26_27 : 495|8@0+ (1,0) [0|255] ""  ADCU
 SG_ ObstacleProb_Obj_26 : 479|7@0+ (1,0) [0|127] "%"  ADCU
 SG_ ObstacleProb_Obj_27 : 487|7@0+ (1,0) [0|127] "%"  ADCU
 SG_ Orientation_Obj_26 : 175|10@0+ (0.01,-5.11) [-5.11|5.12] "rad"  ADCU
 SG_ Orientation_Obj_27 : 407|10@0+ (0.01,-5.11) [-5.11|5.12] "rad"  ADCU
 SG_ OrientationStd_Obj_26 : 471|4@0+ (0.002,0) [0|0.03] "rad"  ADCU
 SG_ OrientationStd_Obj_27 : 467|4@0+ (0.002,0) [0|0.03] "rad"  ADCU
 SG_ ProbOfExist_Obj_26 : 112|7@0+ (1,0) [0|127] "%"  ADCU
 SG_ ProbOfExist_Obj_27 : 344|7@0+ (1,0) [0|127] "%"  ADCU
 SG_ RCS_Obj_26 : 152|9@0+ (0.2,-51.1) [-51.1|51.1] "dBsm"  ADCU
 SG_ RCS_Obj_27 : 384|9@0+ (0.2,-51.1) [-51.1|51.1] "dBsm"  ADCU
 SG_ RefPoint_Obj_26 : 217|4@0+ (1,0) [0|15] ""  ADCU
 SG_ RefPoint_Obj_27 : 449|4@0+ (1,0) [0|15] ""  ADCU
 SG_ VabsX_Obj_26 : 11|11@0+ (0.125,-128) [-128|127.875] "m/s"  ADCU
 SG_ VabsX_Obj_27 : 243|11@0+ (0.125,-128) [-128|127.875] "m/s"  ADCU
 SG_ VabsXStd_Obj_26 : 87|7@0+ (0.1,0) [0|12.7] "m/s"  ADCU
 SG_ VabsXStd_Obj_27 : 319|7@0+ (0.1,0) [0|12.7] "m/s"  ADCU
 SG_ VabsY_Obj_26 : 43|11@0+ (0.125,-128) [-128|127.875] "m/s"  ADCU
 SG_ VabsY_Obj_27 : 275|11@0+ (0.125,-128) [-128|127.875] "m/s"  ADCU
 SG_ VabsYStd_Obj_26 : 80|7@0+ (0.2,0) [0|25.4] "m/s"  ADCU
 SG_ VabsYStd_Obj_27 : 312|7@0+ (0.2,0) [0|25.4] "m/s"  ADCU
 SG_ Valid_Obj_26 : 229|1@0+ (1,0) [0|1] ""  ADCU
 SG_ Valid_Obj_27 : 461|1@0+ (1,0) [0|1] ""  ADCU
 SG_ Width_Obj_26 : 159|7@0+ (0.2,0) [0|25.4] "m"  ADCU
 SG_ Width_Obj_27 : 391|7@0+ (0.2,0) [0|25.4] "m"  ADCU
 SG_ YawRateAbs_Obj_26 : 181|10@0+ (0.001,-0.511) [-0.511|0.512] "rad/s"  ADCU
 SG_ YawRateAbs_Obj_27 : 413|10@0+ (0.001,-0.511) [-0.511|0.512] "rad/s"  ADCU
 SG_ YawRateAbsStd_Obj_26 : 187|10@0+ (0.0001,0) [0|0.1023] "rad/s"  ADCU
 SG_ YawRateAbsStd_Obj_27 : 419|10@0+ (0.0001,0) [0|0.1023] "rad/s"  ADCU

BO_ 527 LR_Object_28_29: 64 LR
 SG_ AabsX_Obj_28 : 16|9@0+ (0.125,-31.875) [-31.875|32] "m/s^2"  ADCU
 SG_ AabsX_Obj_29 : 248|9@0+ (0.125,-31.875) [-31.875|32] "m/s^2"  ADCU
 SG_ AabsXStd_Obj_28 : 89|7@0+ (0.25,0) [0|31.75] "m/s^2"  ADCU
 SG_ AabsXStd_Obj_29 : 321|7@0+ (0.25,0) [0|31.75] "m/s^2"  ADCU
 SG_ AabsY_Obj_28 : 48|9@0+ (0.125,-31.875) [-31.875|32] "m/s^2"  ADCU
 SG_ AabsY_Obj_29 : 280|9@0+ (0.125,-31.875) [-31.875|32] "m/s^2"  ADCU
 SG_ AabsYStd_Obj_28 : 111|8@0+ (0.25,0) [0|63.75] "m/s^2"  ADCU
 SG_ AabsYStd_Obj_29 : 343|8@0+ (0.25,0) [0|63.75] "m/s^2"  ADCU
 SG_ ClassConf_Obj_28 : 119|7@0+ (1,0) [0|127] "%"  ADCU
 SG_ ClassConf_Obj_29 : 351|7@0+ (1,0) [0|127] "%"  ADCU
 SG_ Classification_Obj_28 : 98|3@0+ (1,0) [0|7] ""  ADCU
 SG_ Classification_Obj_29 : 330|3@0+ (1,0) [0|7] ""  ADCU
 SG_ CRC16_Checksum_Obj_28_29 : 503|16@0+ (1,0) [0|65535] ""  ADCU
 SG_ DistX_Obj_28 : 7|12@0+ (0.1,-200) [-200|209.5] "m"  ADCU
 SG_ DistX_Obj_29 : 239|12@0+ (0.1,-200) [-200|209.5] "m"  ADCU
 SG_ DistXStd_Obj_28 : 71|8@0+ (0.05,0) [0|12.75] "m"  ADCU
 SG_ DistXStd_Obj_29 : 303|8@0+ (0.05,0) [0|12.75] "m"  ADCU
 SG_ DistY_Obj_28 : 39|12@0+ (0.1,-200) [-200|209.5] "m"  ADCU
 SG_ DistY_Obj_29 : 271|12@0+ (0.1,-200) [-200|209.5] "m"  ADCU
 SG_ DistYStd_Obj_28 : 79|8@0+ (0.1,0) [0|25.5] "m"  ADCU
 SG_ DistYStd_Obj_29 : 311|8@0+ (0.1,0) [0|25.5] "m"  ADCU
 SG_ DynConf_Obj_28 : 121|7@0+ (1,0) [0|127] "%"  ADCU
 SG_ DynConf_Obj_29 : 353|7@0+ (1,0) [0|127] "%"  ADCU
 SG_ DynProp_Obj_28 : 130|3@0+ (1,0) [0|7] ""  ADCU
 SG_ DynProp_Obj_29 : 362|3@0+ (1,0) [0|7] ""  ADCU
 SG_ ID_Obj_28 : 209|8@0+ (1,0) [0|255] ""  ADCU
 SG_ ID_Obj_29 : 441|8@0+ (1,0) [0|255] ""  ADCU
 SG_ Length_Obj_28 : 136|7@0+ (0.2,0) [0|25.4] "m"  ADCU
 SG_ Length_Obj_29 : 368|7@0+ (0.2,0) [0|25.4] "m"  ADCU
 SG_ LifeCycle_Obj_28 : 193|16@0+ (1,0) [0|65535] ""  ADCU
 SG_ LifeCycle_Obj_29 : 425|16@0+ (1,0) [0|65535] ""  ADCU
 SG_ MaintenanceState_Obj_28 : 145|2@0+ (1,0) [0|3] ""  ADCU
 SG_ MaintenanceState_Obj_29 : 377|2@0+ (1,0) [0|3] ""  ADCU
 SG_ MicroDopplerFlag_28 : 472|1@0+ (1,0) [0|1] ""  ADCU
 SG_ MicroDopplerFlag_29 : 480|1@0+ (1,0) [0|1] ""  ADCU
 SG_ MirrorProb_Obj_28 : 143|7@0+ (1,0) [0|127] "%"  ADCU
 SG_ MirrorProb_Obj_29 : 375|7@0+ (1,0) [0|127] "%"  ADCU
 SG_ MsgCounter_Obj_28_29 : 495|8@0+ (1,0) [0|255] ""  ADCU
 SG_ ObstacleProb_Obj_28 : 479|7@0+ (1,0) [0|127] "%"  ADCU
 SG_ ObstacleProb_Obj_29 : 487|7@0+ (1,0) [0|127] "%"  ADCU
 SG_ Orientation_Obj_28 : 175|10@0+ (0.01,-5.11) [-5.11|5.12] "rad"  ADCU
 SG_ Orientation_Obj_29 : 407|10@0+ (0.01,-5.11) [-5.11|5.12] "rad"  ADCU
 SG_ OrientationStd_Obj_28 : 471|4@0+ (0.002,0) [0|0.03] "rad"  ADCU
 SG_ OrientationStd_Obj_29 : 467|4@0+ (0.002,0) [0|0.03] "rad"  ADCU
 SG_ ProbOfExist_Obj_28 : 112|7@0+ (1,0) [0|127] "%"  ADCU
 SG_ ProbOfExist_Obj_29 : 344|7@0+ (1,0) [0|127] "%"  ADCU
 SG_ RCS_Obj_28 : 152|9@0+ (0.2,-51.1) [-51.1|51.1] "dBsm"  ADCU
 SG_ RCS_Obj_29 : 384|9@0+ (0.2,-51.1) [-51.1|51.1] "dBsm"  ADCU
 SG_ RefPoint_Obj_28 : 217|4@0+ (1,0) [0|15] ""  ADCU
 SG_ RefPoint_Obj_29 : 449|4@0+ (1,0) [0|15] ""  ADCU
 SG_ VabsX_Obj_28 : 11|11@0+ (0.125,-128) [-128|127.875] "m/s"  ADCU
 SG_ VabsX_Obj_29 : 243|11@0+ (0.125,-128) [-128|127.875] "m/s"  ADCU
 SG_ VabsXStd_Obj_28 : 87|7@0+ (0.1,0) [0|12.7] "m/s"  ADCU
 SG_ VabsXStd_Obj_29 : 319|7@0+ (0.1,0) [0|12.7] "m/s"  ADCU
 SG_ VabsY_Obj_28 : 43|11@0+ (0.125,-128) [-128|127.875] "m/s"  ADCU
 SG_ VabsY_Obj_29 : 275|11@0+ (0.125,-128) [-128|127.875] "m/s"  ADCU
 SG_ VabsYStd_Obj_28 : 80|7@0+ (0.2,0) [0|25.4] "m/s"  ADCU
 SG_ VabsYStd_Obj_29 : 312|7@0+ (0.2,0) [0|25.4] "m/s"  ADCU
 SG_ Valid_Obj_28 : 229|1@0+ (1,0) [0|1] ""  ADCU
 SG_ Valid_Obj_29 : 461|1@0+ (1,0) [0|1] ""  ADCU
 SG_ Width_Obj_28 : 159|7@0+ (0.2,0) [0|25.4] "m"  ADCU
 SG_ Width_Obj_29 : 391|7@0+ (0.2,0) [0|25.4] "m"  ADCU
 SG_ YawRateAbs_Obj_28 : 181|10@0+ (0.001,-0.511) [-0.511|0.512] "rad/s"  ADCU
 SG_ YawRateAbs_Obj_29 : 413|10@0+ (0.001,-0.511) [-0.511|0.512] "rad/s"  ADCU
 SG_ YawRateAbsStd_Obj_28 : 187|10@0+ (0.0001,0) [0|0.1023] "rad/s"  ADCU
 SG_ YawRateAbsStd_Obj_29 : 419|10@0+ (0.0001,0) [0|0.1023] "rad/s"  ADCU

BO_ 528 LR_Object_30_31: 64 LR
 SG_ AabsX_Obj_30 : 16|9@0+ (0.125,-31.875) [-31.875|32] "m/s^2"  ADCU
 SG_ AabsX_Obj_31 : 248|9@0+ (0.125,-31.875) [-31.875|32] "m/s^2"  ADCU
 SG_ AabsXStd_Obj_30 : 89|7@0+ (0.25,0) [0|31.75] "m/s^2"  ADCU
 SG_ AabsXStd_Obj_31 : 321|7@0+ (0.25,0) [0|31.75] "m/s^2"  ADCU
 SG_ AabsY_Obj_30 : 48|9@0+ (0.125,-31.875) [-31.875|32] "m/s^2"  ADCU
 SG_ AabsY_Obj_31 : 280|9@0+ (0.125,-31.875) [-31.875|32] "m/s^2"  ADCU
 SG_ AabsYStd_Obj_30 : 111|8@0+ (0.25,0) [0|63.75] "m/s^2"  ADCU
 SG_ AabsYStd_Obj_31 : 343|8@0+ (0.25,0) [0|63.75] "m/s^2"  ADCU
 SG_ ClassConf_Obj_30 : 119|7@0+ (1,0) [0|127] "%"  ADCU
 SG_ ClassConf_Obj_31 : 351|7@0+ (1,0) [0|127] "%"  ADCU
 SG_ Classification_Obj_30 : 98|3@0+ (1,0) [0|7] ""  ADCU
 SG_ Classification_Obj_31 : 330|3@0+ (1,0) [0|7] ""  ADCU
 SG_ CRC16_Checksum_Obj_30_31 : 503|16@0+ (1,0) [0|65535] ""  ADCU
 SG_ DistX_Obj_30 : 7|12@0+ (0.1,-200) [-200|209.5] "m"  ADCU
 SG_ DistX_Obj_31 : 239|12@0+ (0.1,-200) [-200|209.5] "m"  ADCU
 SG_ DistXStd_Obj_30 : 71|8@0+ (0.05,0) [0|12.75] "m"  ADCU
 SG_ DistXStd_Obj_31 : 303|8@0+ (0.05,0) [0|12.75] "m"  ADCU
 SG_ DistY_Obj_30 : 39|12@0+ (0.1,-200) [-200|209.5] "m"  ADCU
 SG_ DistY_Obj_31 : 271|12@0+ (0.1,-200) [-200|209.5] "m"  ADCU
 SG_ DistYStd_Obj_30 : 79|8@0+ (0.1,0) [0|25.5] "m"  ADCU
 SG_ DistYStd_Obj_31 : 311|8@0+ (0.1,0) [0|25.5] "m"  ADCU
 SG_ DynConf_Obj_30 : 121|7@0+ (1,0) [0|127] "%"  ADCU
 SG_ DynConf_Obj_31 : 353|7@0+ (1,0) [0|127] "%"  ADCU
 SG_ DynProp_Obj_30 : 130|3@0+ (1,0) [0|7] ""  ADCU
 SG_ DynProp_Obj_31 : 362|3@0+ (1,0) [0|7] ""  ADCU
 SG_ ID_Obj_30 : 209|8@0+ (1,0) [0|255] ""  ADCU
 SG_ ID_Obj_31 : 441|8@0+ (1,0) [0|255] ""  ADCU
 SG_ Length_Obj_30 : 136|7@0+ (0.2,0) [0|25.4] "m"  ADCU
 SG_ Length_Obj_31 : 368|7@0+ (0.2,0) [0|25.4] "m"  ADCU
 SG_ LifeCycle_Obj_30 : 193|16@0+ (1,0) [0|65535] ""  ADCU
 SG_ LifeCycle_Obj_31 : 425|16@0+ (1,0) [0|65535] ""  ADCU
 SG_ MaintenanceState_Obj_30 : 145|2@0+ (1,0) [0|3] ""  ADCU
 SG_ MaintenanceState_Obj_31 : 377|2@0+ (1,0) [0|3] ""  ADCU
 SG_ MicroDopplerFlag_30 : 472|1@0+ (1,0) [0|1] ""  ADCU
 SG_ MicroDopplerFlag_31 : 480|1@0+ (1,0) [0|1] ""  ADCU
 SG_ MirrorProb_Obj_30 : 143|7@0+ (1,0) [0|127] "%"  ADCU
 SG_ MirrorProb_Obj_31 : 375|7@0+ (1,0) [0|127] "%"  ADCU
 SG_ MsgCounter_Obj_30_31 : 495|8@0+ (1,0) [0|255] ""  ADCU
 SG_ ObstacleProb_Obj_30 : 479|7@0+ (1,0) [0|127] "%"  ADCU
 SG_ ObstacleProb_Obj_31 : 487|7@0+ (1,0) [0|127] "%"  ADCU
 SG_ Orientation_Obj_30 : 175|10@0+ (0.01,-5.11) [-5.11|5.12] "rad"  ADCU
 SG_ Orientation_Obj_31 : 407|10@0+ (0.01,-5.11) [-5.11|5.12] "rad"  ADCU
 SG_ OrientationStd_Obj_30 : 471|4@0+ (0.002,0) [0|0.03] "rad"  ADCU
 SG_ OrientationStd_Obj_31 : 467|4@0+ (0.002,0) [0|0.03] "rad"  ADCU
 SG_ ProbOfExist_Obj_30 : 112|7@0+ (1,0) [0|127] "%"  ADCU
 SG_ ProbOfExist_Obj_31 : 344|7@0+ (1,0) [0|127] "%"  ADCU
 SG_ RCS_Obj_30 : 152|9@0+ (0.2,-51.1) [-51.1|51.1] "dBsm"  ADCU
 SG_ RCS_Obj_31 : 384|9@0+ (0.2,-51.1) [-51.1|51.1] "dBsm"  ADCU
 SG_ RefPoint_Obj_30 : 217|4@0+ (1,0) [0|15] ""  ADCU
 SG_ RefPoint_Obj_31 : 449|4@0+ (1,0) [0|15] ""  ADCU
 SG_ VabsX_Obj_30 : 11|11@0+ (0.125,-128) [-128|127.875] "m/s"  ADCU
 SG_ VabsX_Obj_31 : 243|11@0+ (0.125,-128) [-128|127.875] "m/s"  ADCU
 SG_ VabsXStd_Obj_30 : 87|7@0+ (0.1,0) [0|12.7] "m/s"  ADCU
 SG_ VabsXStd_Obj_31 : 319|7@0+ (0.1,0) [0|12.7] "m/s"  ADCU
 SG_ VabsY_Obj_30 : 43|11@0+ (0.125,-128) [-128|127.875] "m/s"  ADCU
 SG_ VabsY_Obj_31 : 275|11@0+ (0.125,-128) [-128|127.875] "m/s"  ADCU
 SG_ VabsYStd_Obj_30 : 80|7@0+ (0.2,0) [0|25.4] "m/s"  ADCU
 SG_ VabsYStd_Obj_31 : 312|7@0+ (0.2,0) [0|25.4] "m/s"  ADCU
 SG_ Valid_Obj_30 : 229|1@0+ (1,0) [0|1] ""  ADCU
 SG_ Valid_Obj_31 : 461|1@0+ (1,0) [0|1] ""  ADCU
 SG_ Width_Obj_30 : 159|7@0+ (0.2,0) [0|25.4] "m"  ADCU
 SG_ Width_Obj_31 : 391|7@0+ (0.2,0) [0|25.4] "m"  ADCU
 SG_ YawRateAbs_Obj_30 : 181|10@0+ (0.001,-0.511) [-0.511|0.512] "rad/s"  ADCU
 SG_ YawRateAbs_Obj_31 : 413|10@0+ (0.001,-0.511) [-0.511|0.512] "rad/s"  ADCU
 SG_ YawRateAbsStd_Obj_30 : 187|10@0+ (0.0001,0) [0|0.1023] "rad/s"  ADCU
 SG_ YawRateAbsStd_Obj_31 : 419|10@0+ (0.0001,0) [0|0.1023] "rad/s"  ADCU

BO_ 544 RR_Object_Header: 32 LR
 SG_ CRC16_Checksum_Header : 247|16@0+ (1,0) [0|65535] ""  ADCU
 SG_ CycleCounter : 119|16@0+ (1,0) [0|65535] ""  ADCU
 SG_ EgoAcceleration : 168|9@0+ (0.125,-31.875) [-31.875|32] "m/s^2"  ADCU
 SG_ EgoCurvature : 191|8@0+ (0.001,0) [0|0.255] "1/m"  ADCU
 SG_ EgoVelocity : 148|11@0+ (0.125,-128) [-128|127.875] "m/s"  ADCU
 SG_ EgoVelocityStd : 175|7@0+ (0.1,0) [0|12.7] "m/s"  ADCU
 SG_ EgoYawRate : 153|10@0+ (0.001,-0.511) [-0.511|0.512] "rad/s"  ADCU
 SG_ ExtendedCycleFlag : 128|1@0+ (1,0) [0|1] ""  ADCU
 SG_ Latency : 143|11@0+ (0.1,80) [0|284.7] "ms"  ADCU
 SG_ MeasCounter : 103|16@0+ (1,0) [0|65535] ""  ADCU
 SG_ MsgCounter_Header : 239|8@0+ (1,0) [0|255] ""  ADCU
 SG_ NumOfObjects : 135|6@0+ (1,0) [0|63] ""  ADCU
 SG_ TaskValidFlag : 129|1@0+ (1,0) [0|1] ""  ADCU
 SG_ TimeStampGlobNanoSec : 39|32@0+ (1,0) [0|4294967295] "ns"  ADCU
 SG_ TimeStampGlobSec : 7|32@0+ (1,0) [0|4294967295] "s"  ADCU
 SG_ TimeStampLocal : 71|32@0+ (1,0) [0|4294967295] "ns"  ADCU

BO_ 545 RR_Object_00_01: 64 LR
 SG_ AabsX_Obj_00 : 16|9@0+ (0.125,-31.875) [-31.875|32] "m/s^2"  ADCU
 SG_ AabsX_Obj_01 : 248|9@0+ (0.125,-31.875) [-31.875|32] "m/s^2"  ADCU
 SG_ AabsXStd_Obj_00 : 89|7@0+ (0.25,0) [0|31.75] "m/s^2"  ADCU
 SG_ AabsXStd_Obj_01 : 321|7@0+ (0.25,0) [0|31.75] "m/s^2"  ADCU
 SG_ AabsY_Obj_00 : 48|9@0+ (0.125,-31.875) [-31.875|32] "m/s^2"  ADCU
 SG_ AabsY_Obj_01 : 280|9@0+ (0.125,-31.875) [-31.875|32] "m/s^2"  ADCU
 SG_ AabsYStd_Obj_00 : 111|8@0+ (0.25,0) [0|63.75] "m/s^2"  ADCU
 SG_ AabsYStd_Obj_01 : 343|8@0+ (0.25,0) [0|63.75] "m/s^2"  ADCU
 SG_ ClassConf_Obj_00 : 119|7@0+ (1,0) [0|127] "%"  ADCU
 SG_ ClassConf_Obj_01 : 351|7@0+ (1,0) [0|127] "%"  ADCU
 SG_ Classification_Obj_00 : 98|3@0+ (1,0) [0|7] ""  ADCU
 SG_ Classification_Obj_01 : 330|3@0+ (1,0) [0|7] ""  ADCU
 SG_ CRC16_Checksum_Obj_00_01 : 503|16@0+ (1,0) [0|65535] ""  ADCU
 SG_ DistX_Obj_00 : 7|12@0+ (0.1,-200) [-200|209.5] "m"  ADCU
 SG_ DistX_Obj_01 : 239|12@0+ (0.1,-200) [-200|209.5] "m"  ADCU
 SG_ DistXStd_Obj_00 : 71|8@0+ (0.05,0) [0|12.75] "m"  ADCU
 SG_ DistXStd_Obj_01 : 303|8@0+ (0.05,0) [0|12.75] "m"  ADCU
 SG_ DistY_Obj_00 : 39|12@0+ (0.1,-200) [-200|209.5] "m"  ADCU
 SG_ DistY_Obj_01 : 271|12@0+ (0.1,-200) [-200|209.5] "m"  ADCU
 SG_ DistYStd_Obj_00 : 79|8@0+ (0.1,0) [0|25.5] "m"  ADCU
 SG_ DistYStd_Obj_01 : 311|8@0+ (0.1,0) [0|25.5] "m"  ADCU
 SG_ DynConf_Obj_00 : 121|7@0+ (1,0) [0|127] "%"  ADCU
 SG_ DynConf_Obj_01 : 353|7@0+ (1,0) [0|127] "%"  ADCU
 SG_ DynProp_Obj_00 : 130|3@0+ (1,0) [0|7] ""  ADCU
 SG_ DynProp_Obj_01 : 362|3@0+ (1,0) [0|7] ""  ADCU
 SG_ ID_Obj_00 : 209|8@0+ (1,0) [0|255] ""  ADCU
 SG_ ID_Obj_01 : 441|8@0+ (1,0) [0|255] ""  ADCU
 SG_ Length_Obj_00 : 136|7@0+ (0.2,0) [0|25.4] "m"  ADCU
 SG_ Length_Obj_01 : 368|7@0+ (0.2,0) [0|25.4] "m"  ADCU
 SG_ LifeCycle_Obj_00 : 193|16@0+ (1,0) [0|65535] ""  ADCU
 SG_ LifeCycle_Obj_01 : 425|16@0+ (1,0) [0|65535] ""  ADCU
 SG_ MaintenanceState_Obj_00 : 145|2@0+ (1,0) [0|3] ""  ADCU
 SG_ MaintenanceState_Obj_01 : 377|2@0+ (1,0) [0|3] ""  ADCU
 SG_ MicroDopplerFlag_00 : 472|1@0+ (1,0) [0|1] ""  ADCU
 SG_ MicroDopplerFlag_01 : 480|1@0+ (1,0) [0|1] ""  ADCU
 SG_ MirrorProb_Obj_00 : 143|7@0+ (1,0) [0|127] "%"  ADCU
 SG_ MirrorProb_Obj_01 : 375|7@0+ (1,0) [0|127] "%"  ADCU
 SG_ MsgCounter_Obj_00_01 : 495|8@0+ (1,0) [0|255] ""  ADCU
 SG_ ObstacleProb_Obj_00 : 479|7@0+ (1,0) [0|127] "%"  ADCU
 SG_ ObstacleProb_Obj_01 : 487|7@0+ (1,0) [0|127] "%"  ADCU
 SG_ Orientation_Obj_00 : 175|10@0+ (0.01,-5.11) [-5.11|5.12] "rad"  ADCU
 SG_ Orientation_Obj_01 : 407|10@0+ (0.01,-5.11) [-5.11|5.12] "rad"  ADCU
 SG_ OrientationStd_Obj_00 : 471|4@0+ (0.002,0) [0|0.03] "rad"  ADCU
 SG_ OrientationStd_Obj_01 : 467|4@0+ (0.002,0) [0|0.03] "rad"  ADCU
 SG_ ProbOfExist_Obj_00 : 112|7@0+ (1,0) [0|127] "%"  ADCU
 SG_ ProbOfExist_Obj_01 : 344|7@0+ (1,0) [0|127] "%"  ADCU
 SG_ RCS_Obj_00 : 152|9@0+ (0.2,-51.1) [-51.1|51.1] "dBsm"  ADCU
 SG_ RCS_Obj_01 : 384|9@0+ (0.2,-51.1) [-51.1|51.1] "dBsm"  ADCU
 SG_ RefPoint_Obj_00 : 217|4@0+ (1,0) [0|15] ""  ADCU
 SG_ RefPoint_Obj_01 : 449|4@0+ (1,0) [0|15] ""  ADCU
 SG_ VabsX_Obj_00 : 11|11@0+ (0.125,-128) [-128|127.875] "m/s"  ADCU
 SG_ VabsX_Obj_01 : 243|11@0+ (0.125,-128) [-128|127.875] "m/s"  ADCU
 SG_ VabsXStd_Obj_00 : 87|7@0+ (0.1,0) [0|12.7] "m/s"  ADCU
 SG_ VabsXStd_Obj_01 : 319|7@0+ (0.1,0) [0|12.7] "m/s"  ADCU
 SG_ VabsY_Obj_00 : 43|11@0+ (0.125,-128) [-128|127.875] "m/s"  ADCU
 SG_ VabsY_Obj_01 : 275|11@0+ (0.125,-128) [-128|127.875] "m/s"  ADCU
 SG_ VabsYStd_Obj_00 : 80|7@0+ (0.2,0) [0|25.4] "m/s"  ADCU
 SG_ VabsYStd_Obj_01 : 312|7@0+ (0.2,0) [0|25.4] "m/s"  ADCU
 SG_ Valid_Obj_00 : 229|1@0+ (1,0) [0|1] ""  ADCU
 SG_ Valid_Obj_01 : 461|1@0+ (1,0) [0|1] ""  ADCU
 SG_ Width_Obj_00 : 159|7@0+ (0.2,0) [0|25.4] "m"  ADCU
 SG_ Width_Obj_01 : 391|7@0+ (0.2,0) [0|25.4] "m"  ADCU
 SG_ YawRateAbs_Obj_00 : 181|10@0+ (0.001,-0.511) [-0.511|0.512] "rad/s"  ADCU
 SG_ YawRateAbs_Obj_01 : 413|10@0+ (0.001,-0.511) [-0.511|0.512] "rad/s"  ADCU
 SG_ YawRateAbsStd_Obj_00 : 187|10@0+ (0.0001,0) [0|0.1023] "rad/s"  ADCU
 SG_ YawRateAbsStd_Obj_01 : 419|10@0+ (0.0001,0) [0|0.1023] "rad/s"  ADCU

BO_ 546 RR_Object_02_03: 64 LR
 SG_ AabsX_Obj_02 : 16|9@0+ (0.125,-31.875) [-31.875|32] "m/s^2"  ADCU
 SG_ AabsX_Obj_03 : 248|9@0+ (0.125,-31.875) [-31.875|32] "m/s^2"  ADCU
 SG_ AabsXStd_Obj_02 : 89|7@0+ (0.25,0) [0|31.75] "m/s^2"  ADCU
 SG_ AabsXStd_Obj_03 : 321|7@0+ (0.25,0) [0|31.75] "m/s^2"  ADCU
 SG_ AabsY_Obj_02 : 48|9@0+ (0.125,-31.875) [-31.875|32] "m/s^2"  ADCU
 SG_ AabsY_Obj_03 : 280|9@0+ (0.125,-31.875) [-31.875|32] "m/s^2"  ADCU
 SG_ AabsYStd_Obj_02 : 111|8@0+ (0.25,0) [0|63.75] "m/s^2"  ADCU
 SG_ AabsYStd_Obj_03 : 343|8@0+ (0.25,0) [0|63.75] "m/s^2"  ADCU
 SG_ ClassConf_Obj_02 : 119|7@0+ (1,0) [0|127] "%"  ADCU
 SG_ ClassConf_Obj_03 : 351|7@0+ (1,0) [0|127] "%"  ADCU
 SG_ Classification_Obj_02 : 98|3@0+ (1,0) [0|7] ""  ADCU
 SG_ Classification_Obj_03 : 330|3@0+ (1,0) [0|7] ""  ADCU
 SG_ CRC16_Checksum_Obj_02_03 : 503|16@0+ (1,0) [0|65535] ""  ADCU
 SG_ DistX_Obj_02 : 7|12@0+ (0.1,-200) [-200|209.5] "m"  ADCU
 SG_ DistX_Obj_03 : 239|12@0+ (0.1,-200) [-200|209.5] "m"  ADCU
 SG_ DistXStd_Obj_02 : 71|8@0+ (0.05,0) [0|12.75] "m"  ADCU
 SG_ DistXStd_Obj_03 : 303|8@0+ (0.05,0) [0|12.75] "m"  ADCU
 SG_ DistY_Obj_02 : 39|12@0+ (0.1,-200) [-200|209.5] "m"  ADCU
 SG_ DistY_Obj_03 : 271|12@0+ (0.1,-200) [-200|209.5] "m"  ADCU
 SG_ DistYStd_Obj_02 : 79|8@0+ (0.1,0) [0|25.5] "m"  ADCU
 SG_ DistYStd_Obj_03 : 311|8@0+ (0.1,0) [0|25.5] "m"  ADCU
 SG_ DynConf_Obj_02 : 121|7@0+ (1,0) [0|127] "%"  ADCU
 SG_ DynConf_Obj_03 : 353|7@0+ (1,0) [0|127] "%"  ADCU
 SG_ DynProp_Obj_02 : 130|3@0+ (1,0) [0|7] ""  ADCU
 SG_ DynProp_Obj_03 : 362|3@0+ (1,0) [0|7] ""  ADCU
 SG_ ID_Obj_02 : 209|8@0+ (1,0) [0|255] ""  ADCU
 SG_ ID_Obj_03 : 441|8@0+ (1,0) [0|255] ""  ADCU
 SG_ Length_Obj_02 : 136|7@0+ (0.2,0) [0|25.4] "m"  ADCU
 SG_ Length_Obj_03 : 368|7@0+ (0.2,0) [0|25.4] "m"  ADCU
 SG_ LifeCycle_Obj_02 : 193|16@0+ (1,0) [0|65535] ""  ADCU
 SG_ LifeCycle_Obj_03 : 425|16@0+ (1,0) [0|65535] ""  ADCU
 SG_ MaintenanceState_Obj_02 : 145|2@0+ (1,0) [0|3] ""  ADCU
 SG_ MaintenanceState_Obj_03 : 377|2@0+ (1,0) [0|3] ""  ADCU
 SG_ MicroDopplerFlag_02 : 472|1@0+ (1,0) [0|1] ""  ADCU
 SG_ MicroDopplerFlag_03 : 480|1@0+ (1,0) [0|1] ""  ADCU
 SG_ MirrorProb_Obj_02 : 143|7@0+ (1,0) [0|127] "%"  ADCU
 SG_ MirrorProb_Obj_03 : 375|7@0+ (1,0) [0|127] "%"  ADCU
 SG_ MsgCounter_Obj_00_03 : 495|8@0+ (1,0) [0|255] ""  ADCU
 SG_ ObstacleProb_Obj_02 : 479|7@0+ (1,0) [0|127] "%"  ADCU
 SG_ ObstacleProb_Obj_03 : 487|7@0+ (1,0) [0|127] "%"  ADCU
 SG_ Orientation_Obj_02 : 175|10@0+ (0.01,-5.11) [-5.11|5.12] "rad"  ADCU
 SG_ Orientation_Obj_03 : 407|10@0+ (0.01,-5.11) [-5.11|5.12] "rad"  ADCU
 SG_ OrientationStd_Obj_02 : 471|4@0+ (0.002,0) [0|0.03] "rad"  ADCU
 SG_ OrientationStd_Obj_03 : 467|4@0+ (0.002,0) [0|0.03] "rad"  ADCU
 SG_ ProbOfExist_Obj_02 : 112|7@0+ (1,0) [0|127] "%"  ADCU
 SG_ ProbOfExist_Obj_03 : 344|7@0+ (1,0) [0|127] "%"  ADCU
 SG_ RCS_Obj_02 : 152|9@0+ (0.2,-51.1) [-51.1|51.1] "dBsm"  ADCU
 SG_ RCS_Obj_03 : 384|9@0+ (0.2,-51.1) [-51.1|51.1] "dBsm"  ADCU
 SG_ RefPoint_Obj_02 : 217|4@0+ (1,0) [0|15] ""  ADCU
 SG_ RefPoint_Obj_03 : 449|4@0+ (1,0) [0|15] ""  ADCU
 SG_ VabsX_Obj_02 : 11|11@0+ (0.125,-128) [-128|127.875] "m/s"  ADCU
 SG_ VabsX_Obj_03 : 243|11@0+ (0.125,-128) [-128|127.875] "m/s"  ADCU
 SG_ VabsXStd_Obj_02 : 87|7@0+ (0.1,0) [0|12.7] "m/s"  ADCU
 SG_ VabsXStd_Obj_03 : 319|7@0+ (0.1,0) [0|12.7] "m/s"  ADCU
 SG_ VabsY_Obj_02 : 43|11@0+ (0.125,-128) [-128|127.875] "m/s"  ADCU
 SG_ VabsY_Obj_03 : 275|11@0+ (0.125,-128) [-128|127.875] "m/s"  ADCU
 SG_ VabsYStd_Obj_02 : 80|7@0+ (0.2,0) [0|25.4] "m/s"  ADCU
 SG_ VabsYStd_Obj_03 : 312|7@0+ (0.2,0) [0|25.4] "m/s"  ADCU
 SG_ Valid_Obj_02 : 229|1@0+ (1,0) [0|1] ""  ADCU
 SG_ Valid_Obj_03 : 461|1@0+ (1,0) [0|1] ""  ADCU
 SG_ Width_Obj_02 : 159|7@0+ (0.2,0) [0|25.4] "m"  ADCU
 SG_ Width_Obj_03 : 391|7@0+ (0.2,0) [0|25.4] "m"  ADCU
 SG_ YawRateAbs_Obj_02 : 181|10@0+ (0.001,-0.511) [-0.511|0.512] "rad/s"  ADCU
 SG_ YawRateAbs_Obj_03 : 413|10@0+ (0.001,-0.511) [-0.511|0.512] "rad/s"  ADCU
 SG_ YawRateAbsStd_Obj_02 : 187|10@0+ (0.0001,0) [0|0.1023] "rad/s"  ADCU
 SG_ YawRateAbsStd_Obj_03 : 419|10@0+ (0.0001,0) [0|0.1023] "rad/s"  ADCU

BO_ 547 RR_Object_04_05: 64 LR
 SG_ AabsX_Obj_04 : 16|9@0+ (0.125,-31.875) [-31.875|32] "m/s^2"  ADCU
 SG_ AabsX_Obj_05 : 248|9@0+ (0.125,-31.875) [-31.875|32] "m/s^2"  ADCU
 SG_ AabsXStd_Obj_04 : 89|7@0+ (0.25,0) [0|31.75] "m/s^2"  ADCU
 SG_ AabsXStd_Obj_05 : 321|7@0+ (0.25,0) [0|31.75] "m/s^2"  ADCU
 SG_ AabsY_Obj_04 : 48|9@0+ (0.125,-31.875) [-31.875|32] "m/s^2"  ADCU
 SG_ AabsY_Obj_05 : 280|9@0+ (0.125,-31.875) [-31.875|32] "m/s^2"  ADCU
 SG_ AabsYStd_Obj_04 : 111|8@0+ (0.25,0) [0|63.75] "m/s^2"  ADCU
 SG_ AabsYStd_Obj_05 : 343|8@0+ (0.25,0) [0|63.75] "m/s^2"  ADCU
 SG_ ClassConf_Obj_04 : 119|7@0+ (1,0) [0|127] "%"  ADCU
 SG_ ClassConf_Obj_05 : 351|7@0+ (1,0) [0|127] "%"  ADCU
 SG_ Classification_Obj_04 : 98|3@0+ (1,0) [0|7] ""  ADCU
 SG_ Classification_Obj_05 : 330|3@0+ (1,0) [0|7] ""  ADCU
 SG_ CRC16_Checksum_Obj_04_05 : 503|16@0+ (1,0) [0|65535] ""  ADCU
 SG_ DistX_Obj_04 : 7|12@0+ (0.1,-200) [-200|209.5] "m"  ADCU
 SG_ DistX_Obj_05 : 239|12@0+ (0.1,-200) [-200|209.5] "m"  ADCU
 SG_ DistXStd_Obj_04 : 71|8@0+ (0.05,0) [0|12.75] "m"  ADCU
 SG_ DistXStd_Obj_05 : 303|8@0+ (0.05,0) [0|12.75] "m"  ADCU
 SG_ DistY_Obj_04 : 39|12@0+ (0.1,-200) [-200|209.5] "m"  ADCU
 SG_ DistY_Obj_05 : 271|12@0+ (0.1,-200) [-200|209.5] "m"  ADCU
 SG_ DistYStd_Obj_04 : 79|8@0+ (0.1,0) [0|25.5] "m"  ADCU
 SG_ DistYStd_Obj_05 : 311|8@0+ (0.1,0) [0|25.5] "m"  ADCU
 SG_ DynConf_Obj_04 : 121|7@0+ (1,0) [0|127] "%"  ADCU
 SG_ DynConf_Obj_05 : 353|7@0+ (1,0) [0|127] "%"  ADCU
 SG_ DynProp_Obj_04 : 130|3@0+ (1,0) [0|7] ""  ADCU
 SG_ DynProp_Obj_05 : 362|3@0+ (1,0) [0|7] ""  ADCU
 SG_ ID_Obj_04 : 209|8@0+ (1,0) [0|255] ""  ADCU
 SG_ ID_Obj_05 : 441|8@0+ (1,0) [0|255] ""  ADCU
 SG_ Length_Obj_04 : 136|7@0+ (0.2,0) [0|25.4] "m"  ADCU
 SG_ Length_Obj_05 : 368|7@0+ (0.2,0) [0|25.4] "m"  ADCU
 SG_ LifeCycle_Obj_04 : 193|16@0+ (1,0) [0|65535] ""  ADCU
 SG_ LifeCycle_Obj_05 : 425|16@0+ (1,0) [0|65535] ""  ADCU
 SG_ MaintenanceState_Obj_04 : 145|2@0+ (1,0) [0|3] ""  ADCU
 SG_ MaintenanceState_Obj_05 : 377|2@0+ (1,0) [0|3] ""  ADCU
 SG_ MicroDopplerFlag_04 : 472|1@0+ (1,0) [0|1] ""  ADCU
 SG_ MicroDopplerFlag_05 : 480|1@0+ (1,0) [0|1] ""  ADCU
 SG_ MirrorProb_Obj_04 : 143|7@0+ (1,0) [0|127] "%"  ADCU
 SG_ MirrorProb_Obj_05 : 375|7@0+ (1,0) [0|127] "%"  ADCU
 SG_ MsgCounter_Obj_04_05 : 495|8@0+ (1,0) [0|255] ""  ADCU
 SG_ ObstacleProb_Obj_04 : 479|7@0+ (1,0) [0|127] "%"  ADCU
 SG_ ObstacleProb_Obj_05 : 487|7@0+ (1,0) [0|127] "%"  ADCU
 SG_ Orientation_Obj_04 : 175|10@0+ (0.01,-5.11) [-5.11|5.12] "rad"  ADCU
 SG_ Orientation_Obj_05 : 407|10@0+ (0.01,-5.11) [-5.11|5.12] "rad"  ADCU
 SG_ OrientationStd_Obj_04 : 471|4@0+ (0.002,0) [0|0.03] "rad"  ADCU
 SG_ OrientationStd_Obj_05 : 467|4@0+ (0.002,0) [0|0.03] "rad"  ADCU
 SG_ ProbOfExist_Obj_04 : 112|7@0+ (1,0) [0|127] "%"  ADCU
 SG_ ProbOfExist_Obj_05 : 344|7@0+ (1,0) [0|127] "%"  ADCU
 SG_ RCS_Obj_04 : 152|9@0+ (0.2,-51.1) [-51.1|51.1] "dBsm"  ADCU
 SG_ RCS_Obj_05 : 384|9@0+ (0.2,-51.1) [-51.1|51.1] "dBsm"  ADCU
 SG_ RefPoint_Obj_04 : 217|4@0+ (1,0) [0|15] ""  ADCU
 SG_ RefPoint_Obj_05 : 449|4@0+ (1,0) [0|15] ""  ADCU
 SG_ VabsX_Obj_04 : 11|11@0+ (0.125,-128) [-128|127.875] "m/s"  ADCU
 SG_ VabsX_Obj_05 : 243|11@0+ (0.125,-128) [-128|127.875] "m/s"  ADCU
 SG_ VabsXStd_Obj_04 : 87|7@0+ (0.1,0) [0|12.7] "m/s"  ADCU
 SG_ VabsXStd_Obj_05 : 319|7@0+ (0.1,0) [0|12.7] "m/s"  ADCU
 SG_ VabsY_Obj_04 : 43|11@0+ (0.125,-128) [-128|127.875] "m/s"  ADCU
 SG_ VabsY_Obj_05 : 275|11@0+ (0.125,-128) [-128|127.875] "m/s"  ADCU
 SG_ VabsYStd_Obj_04 : 80|7@0+ (0.2,0) [0|25.4] "m/s"  ADCU
 SG_ VabsYStd_Obj_05 : 312|7@0+ (0.2,0) [0|25.4] "m/s"  ADCU
 SG_ Valid_Obj_04 : 229|1@0+ (1,0) [0|1] ""  ADCU
 SG_ Valid_Obj_05 : 461|1@0+ (1,0) [0|1] ""  ADCU
 SG_ Width_Obj_04 : 159|7@0+ (0.2,0) [0|25.4] "m"  ADCU
 SG_ Width_Obj_05 : 391|7@0+ (0.2,0) [0|25.4] "m"  ADCU
 SG_ YawRateAbs_Obj_04 : 181|10@0+ (0.001,-0.511) [-0.511|0.512] "rad/s"  ADCU
 SG_ YawRateAbs_Obj_05 : 413|10@0+ (0.001,-0.511) [-0.511|0.512] "rad/s"  ADCU
 SG_ YawRateAbsStd_Obj_04 : 187|10@0+ (0.0001,0) [0|0.1023] "rad/s"  ADCU
 SG_ YawRateAbsStd_Obj_05 : 419|10@0+ (0.0001,0) [0|0.1023] "rad/s"  ADCU

BO_ 548 RR_Object_06_07: 64 LR
 SG_ AabsX_Obj_06 : 16|9@0+ (0.125,-31.875) [-31.875|32] "m/s^2"  ADCU
 SG_ AabsX_Obj_07 : 248|9@0+ (0.125,-31.875) [-31.875|32] "m/s^2"  ADCU
 SG_ AabsXStd_Obj_06 : 89|7@0+ (0.25,0) [0|31.75] "m/s^2"  ADCU
 SG_ AabsXStd_Obj_07 : 321|7@0+ (0.25,0) [0|31.75] "m/s^2"  ADCU
 SG_ AabsY_Obj_06 : 48|9@0+ (0.125,-31.875) [-31.875|32] "m/s^2"  ADCU
 SG_ AabsY_Obj_07 : 280|9@0+ (0.125,-31.875) [-31.875|32] "m/s^2"  ADCU
 SG_ AabsYStd_Obj_06 : 111|8@0+ (0.25,0) [0|63.75] "m/s^2"  ADCU
 SG_ AabsYStd_Obj_07 : 343|8@0+ (0.25,0) [0|63.75] "m/s^2"  ADCU
 SG_ ClassConf_Obj_06 : 119|7@0+ (1,0) [0|127] "%"  ADCU
 SG_ ClassConf_Obj_07 : 351|7@0+ (1,0) [0|127] "%"  ADCU
 SG_ Classification_Obj_06 : 98|3@0+ (1,0) [0|7] ""  ADCU
 SG_ Classification_Obj_07 : 330|3@0+ (1,0) [0|7] ""  ADCU
 SG_ CRC16_Checksum_Obj_06_07 : 503|16@0+ (1,0) [0|65535] ""  ADCU
 SG_ DistX_Obj_06 : 7|12@0+ (0.1,-200) [-200|209.5] "m"  ADCU
 SG_ DistX_Obj_07 : 239|12@0+ (0.1,-200) [-200|209.5] "m"  ADCU
 SG_ DistXStd_Obj_06 : 71|8@0+ (0.05,0) [0|12.75] "m"  ADCU
 SG_ DistXStd_Obj_07 : 303|8@0+ (0.05,0) [0|12.75] "m"  ADCU
 SG_ DistY_Obj_06 : 39|12@0+ (0.1,-200) [-200|209.5] "m"  ADCU
 SG_ DistY_Obj_07 : 271|12@0+ (0.1,-200) [-200|209.5] "m"  ADCU
 SG_ DistYStd_Obj_06 : 79|8@0+ (0.1,0) [0|25.5] "m"  ADCU
 SG_ DistYStd_Obj_07 : 311|8@0+ (0.1,0) [0|25.5] "m"  ADCU
 SG_ DynConf_Obj_06 : 121|7@0+ (1,0) [0|127] "%"  ADCU
 SG_ DynConf_Obj_07 : 353|7@0+ (1,0) [0|127] "%"  ADCU
 SG_ DynProp_Obj_06 : 130|3@0+ (1,0) [0|7] ""  ADCU
 SG_ DynProp_Obj_07 : 362|3@0+ (1,0) [0|7] ""  ADCU
 SG_ ID_Obj_06 : 209|8@0+ (1,0) [0|255] ""  ADCU
 SG_ ID_Obj_07 : 441|8@0+ (1,0) [0|255] ""  ADCU
 SG_ Length_Obj_06 : 136|7@0+ (0.2,0) [0|25.4] "m"  ADCU
 SG_ Length_Obj_07 : 368|7@0+ (0.2,0) [0|25.4] "m"  ADCU
 SG_ LifeCycle_Obj_06 : 193|16@0+ (1,0) [0|65535] ""  ADCU
 SG_ LifeCycle_Obj_07 : 425|16@0+ (1,0) [0|65535] ""  ADCU
 SG_ MaintenanceState_Obj_06 : 145|2@0+ (1,0) [0|3] ""  ADCU
 SG_ MaintenanceState_Obj_07 : 377|2@0+ (1,0) [0|3] ""  ADCU
 SG_ MicroDopplerFlag_06 : 472|1@0+ (1,0) [0|1] ""  ADCU
 SG_ MicroDopplerFlag_07 : 480|1@0+ (1,0) [0|1] ""  ADCU
 SG_ MirrorProb_Obj_06 : 143|7@0+ (1,0) [0|127] "%"  ADCU
 SG_ MirrorProb_Obj_07 : 375|7@0+ (1,0) [0|127] "%"  ADCU
 SG_ MsgCounter_Obj_06_07 : 495|8@0+ (1,0) [0|255] ""  ADCU
 SG_ ObstacleProb_Obj_06 : 479|7@0+ (1,0) [0|127] "%"  ADCU
 SG_ ObstacleProb_Obj_07 : 487|7@0+ (1,0) [0|127] "%"  ADCU
 SG_ Orientation_Obj_06 : 175|10@0+ (0.01,-5.11) [-5.11|5.12] "rad"  ADCU
 SG_ Orientation_Obj_07 : 407|10@0+ (0.01,-5.11) [-5.11|5.12] "rad"  ADCU
 SG_ OrientationStd_Obj_06 : 471|4@0+ (0.002,0) [0|0.03] "rad"  ADCU
 SG_ OrientationStd_Obj_07 : 467|4@0+ (0.002,0) [0|0.03] "rad"  ADCU
 SG_ ProbOfExist_Obj_06 : 112|7@0+ (1,0) [0|127] "%"  ADCU
 SG_ ProbOfExist_Obj_07 : 344|7@0+ (1,0) [0|127] "%"  ADCU
 SG_ RCS_Obj_06 : 152|9@0+ (0.2,-51.1) [-51.1|51.1] "dBsm"  ADCU
 SG_ RCS_Obj_07 : 384|9@0+ (0.2,-51.1) [-51.1|51.1] "dBsm"  ADCU
 SG_ RefPoint_Obj_06 : 217|4@0+ (1,0) [0|15] ""  ADCU
 SG_ RefPoint_Obj_07 : 449|4@0+ (1,0) [0|15] ""  ADCU
 SG_ VabsX_Obj_06 : 11|11@0+ (0.125,-128) [-128|127.875] "m/s"  ADCU
 SG_ VabsX_Obj_07 : 243|11@0+ (0.125,-128) [-128|127.875] "m/s"  ADCU
 SG_ VabsXStd_Obj_06 : 87|7@0+ (0.1,0) [0|12.7] "m/s"  ADCU
 SG_ VabsXStd_Obj_07 : 319|7@0+ (0.1,0) [0|12.7] "m/s"  ADCU
 SG_ VabsY_Obj_06 : 43|11@0+ (0.125,-128) [-128|127.875] "m/s"  ADCU
 SG_ VabsY_Obj_07 : 275|11@0+ (0.125,-128) [-128|127.875] "m/s"  ADCU
 SG_ VabsYStd_Obj_06 : 80|7@0+ (0.2,0) [0|25.4] "m/s"  ADCU
 SG_ VabsYStd_Obj_07 : 312|7@0+ (0.2,0) [0|25.4] "m/s"  ADCU
 SG_ Valid_Obj_06 : 229|1@0+ (1,0) [0|1] ""  ADCU
 SG_ Valid_Obj_07 : 461|1@0+ (1,0) [0|1] ""  ADCU
 SG_ Width_Obj_06 : 159|7@0+ (0.2,0) [0|25.4] "m"  ADCU
 SG_ Width_Obj_07 : 391|7@0+ (0.2,0) [0|25.4] "m"  ADCU
 SG_ YawRateAbs_Obj_06 : 181|10@0+ (0.001,-0.511) [-0.511|0.512] "rad/s"  ADCU
 SG_ YawRateAbs_Obj_07 : 413|10@0+ (0.001,-0.511) [-0.511|0.512] "rad/s"  ADCU
 SG_ YawRateAbsStd_Obj_06 : 187|10@0+ (0.0001,0) [0|0.1023] "rad/s"  ADCU
 SG_ YawRateAbsStd_Obj_07 : 419|10@0+ (0.0001,0) [0|0.1023] "rad/s"  ADCU

BO_ 549 RR_Object_08_09: 64 LR
 SG_ AabsX_Obj_08 : 16|9@0+ (0.125,-31.875) [-31.875|32] "m/s^2"  ADCU
 SG_ AabsX_Obj_09 : 248|9@0+ (0.125,-31.875) [-31.875|32] "m/s^2"  ADCU
 SG_ AabsXStd_Obj_08 : 89|7@0+ (0.25,0) [0|31.75] "m/s^2"  ADCU
 SG_ AabsXStd_Obj_09 : 321|7@0+ (0.25,0) [0|31.75] "m/s^2"  ADCU
 SG_ AabsY_Obj_08 : 48|9@0+ (0.125,-31.875) [-31.875|32] "m/s^2"  ADCU
 SG_ AabsY_Obj_09 : 280|9@0+ (0.125,-31.875) [-31.875|32] "m/s^2"  ADCU
 SG_ AabsYStd_Obj_08 : 111|8@0+ (0.25,0) [0|63.75] "m/s^2"  ADCU
 SG_ AabsYStd_Obj_09 : 343|8@0+ (0.25,0) [0|63.75] "m/s^2"  ADCU
 SG_ ClassConf_Obj_08 : 119|7@0+ (1,0) [0|127] "%"  ADCU
 SG_ ClassConf_Obj_09 : 351|7@0+ (1,0) [0|127] "%"  ADCU
 SG_ Classification_Obj_08 : 98|3@0+ (1,0) [0|7] ""  ADCU
 SG_ Classification_Obj_09 : 330|3@0+ (1,0) [0|7] ""  ADCU
 SG_ CRC16_Checksum_Obj_08_09 : 503|16@0+ (1,0) [0|65535] ""  ADCU
 SG_ DistX_Obj_08 : 7|12@0+ (0.1,-200) [-200|209.5] "m"  ADCU
 SG_ DistX_Obj_09 : 239|12@0+ (0.1,-200) [-200|209.5] "m"  ADCU
 SG_ DistXStd_Obj_08 : 71|8@0+ (0.05,0) [0|12.75] "m"  ADCU
 SG_ DistXStd_Obj_09 : 303|8@0+ (0.05,0) [0|12.75] "m"  ADCU
 SG_ DistY_Obj_08 : 39|12@0+ (0.1,-200) [-200|209.5] "m"  ADCU
 SG_ DistY_Obj_09 : 271|12@0+ (0.1,-200) [-200|209.5] "m"  ADCU
 SG_ DistYStd_Obj_08 : 79|8@0+ (0.1,0) [0|25.5] "m"  ADCU
 SG_ DistYStd_Obj_09 : 311|8@0+ (0.1,0) [0|25.5] "m"  ADCU
 SG_ DynConf_Obj_08 : 121|7@0+ (1,0) [0|127] "%"  ADCU
 SG_ DynConf_Obj_09 : 353|7@0+ (1,0) [0|127] "%"  ADCU
 SG_ DynProp_Obj_08 : 130|3@0+ (1,0) [0|7] ""  ADCU
 SG_ DynProp_Obj_09 : 362|3@0+ (1,0) [0|7] ""  ADCU
 SG_ ID_Obj_08 : 209|8@0+ (1,0) [0|255] ""  ADCU
 SG_ ID_Obj_09 : 441|8@0+ (1,0) [0|255] ""  ADCU
 SG_ Length_Obj_08 : 136|7@0+ (0.2,0) [0|25.4] "m"  ADCU
 SG_ Length_Obj_09 : 368|7@0+ (0.2,0) [0|25.4] "m"  ADCU
 SG_ LifeCycle_Obj_08 : 193|16@0+ (1,0) [0|65535] ""  ADCU
 SG_ LifeCycle_Obj_09 : 425|16@0+ (1,0) [0|65535] ""  ADCU
 SG_ MaintenanceState_Obj_08 : 145|2@0+ (1,0) [0|3] ""  ADCU
 SG_ MaintenanceState_Obj_09 : 377|2@0+ (1,0) [0|3] ""  ADCU
 SG_ MicroDopplerFlag_08 : 472|1@0+ (1,0) [0|1] ""  ADCU
 SG_ MicroDopplerFlag_09 : 480|1@0+ (1,0) [0|1] ""  ADCU
 SG_ MirrorProb_Obj_08 : 143|7@0+ (1,0) [0|127] "%"  ADCU
 SG_ MirrorProb_Obj_09 : 375|7@0+ (1,0) [0|127] "%"  ADCU
 SG_ MsgCounter_Obj_08_09 : 495|8@0+ (1,0) [0|255] ""  ADCU
 SG_ ObstacleProb_Obj_08 : 479|7@0+ (1,0) [0|127] "%"  ADCU
 SG_ ObstacleProb_Obj_09 : 487|7@0+ (1,0) [0|127] "%"  ADCU
 SG_ Orientation_Obj_08 : 175|10@0+ (0.01,-5.11) [-5.11|5.12] "rad"  ADCU
 SG_ Orientation_Obj_09 : 407|10@0+ (0.01,-5.11) [-5.11|5.12] "rad"  ADCU
 SG_ OrientationStd_Obj_08 : 471|4@0+ (0.002,0) [0|0.03] "rad"  ADCU
 SG_ OrientationStd_Obj_09 : 467|4@0+ (0.002,0) [0|0.03] "rad"  ADCU
 SG_ ProbOfExist_Obj_08 : 112|7@0+ (1,0) [0|127] "%"  ADCU
 SG_ ProbOfExist_Obj_09 : 344|7@0+ (1,0) [0|127] "%"  ADCU
 SG_ RCS_Obj_08 : 152|9@0+ (0.2,-51.1) [-51.1|51.1] "dBsm"  ADCU
 SG_ RCS_Obj_09 : 384|9@0+ (0.2,-51.1) [-51.1|51.1] "dBsm"  ADCU
 SG_ RefPoint_Obj_08 : 217|4@0+ (1,0) [0|15] ""  ADCU
 SG_ RefPoint_Obj_09 : 449|4@0+ (1,0) [0|15] ""  ADCU
 SG_ VabsX_Obj_08 : 11|11@0+ (0.125,-128) [-128|127.875] "m/s"  ADCU
 SG_ VabsX_Obj_09 : 243|11@0+ (0.125,-128) [-128|127.875] "m/s"  ADCU
 SG_ VabsXStd_Obj_08 : 87|7@0+ (0.1,0) [0|12.7] "m/s"  ADCU
 SG_ VabsXStd_Obj_09 : 319|7@0+ (0.1,0) [0|12.7] "m/s"  ADCU
 SG_ VabsY_Obj_08 : 43|11@0+ (0.125,-128) [-128|127.875] "m/s"  ADCU
 SG_ VabsY_Obj_09 : 275|11@0+ (0.125,-128) [-128|127.875] "m/s"  ADCU
 SG_ VabsYStd_Obj_08 : 80|7@0+ (0.2,0) [0|25.4] "m/s"  ADCU
 SG_ VabsYStd_Obj_09 : 312|7@0+ (0.2,0) [0|25.4] "m/s"  ADCU
 SG_ Valid_Obj_08 : 229|1@0+ (1,0) [0|1] ""  ADCU
 SG_ Valid_Obj_09 : 461|1@0+ (1,0) [0|1] ""  ADCU
 SG_ Width_Obj_08 : 159|7@0+ (0.2,0) [0|25.4] "m"  ADCU
 SG_ Width_Obj_09 : 391|7@0+ (0.2,0) [0|25.4] "m"  ADCU
 SG_ YawRateAbs_Obj_08 : 181|10@0+ (0.001,-0.511) [-0.511|0.512] "rad/s"  ADCU
 SG_ YawRateAbs_Obj_09 : 413|10@0+ (0.001,-0.511) [-0.511|0.512] "rad/s"  ADCU
 SG_ YawRateAbsStd_Obj_08 : 187|10@0+ (0.0001,0) [0|0.1023] "rad/s"  ADCU
 SG_ YawRateAbsStd_Obj_09 : 419|10@0+ (0.0001,0) [0|0.1023] "rad/s"  ADCU

BO_ 550 RR_Object_10_11: 64 LR
 SG_ AabsX_Obj_10 : 16|9@0+ (0.125,-31.875) [-31.875|32] "m/s^2"  ADCU
 SG_ AabsX_Obj_11 : 248|9@0+ (0.125,-31.875) [-31.875|32] "m/s^2"  ADCU
 SG_ AabsXStd_Obj_10 : 89|7@0+ (0.25,0) [0|31.75] "m/s^2"  ADCU
 SG_ AabsXStd_Obj_11 : 321|7@0+ (0.25,0) [0|31.75] "m/s^2"  ADCU
 SG_ AabsY_Obj_10 : 48|9@0+ (0.125,-31.875) [-31.875|32] "m/s^2"  ADCU
 SG_ AabsY_Obj_11 : 280|9@0+ (0.125,-31.875) [-31.875|32] "m/s^2"  ADCU
 SG_ AabsYStd_Obj_10 : 111|8@0+ (0.25,0) [0|63.75] "m/s^2"  ADCU
 SG_ AabsYStd_Obj_11 : 343|8@0+ (0.25,0) [0|63.75] "m/s^2"  ADCU
 SG_ ClassConf_Obj_10 : 119|7@0+ (1,0) [0|127] "%"  ADCU
 SG_ ClassConf_Obj_11 : 351|7@0+ (1,0) [0|127] "%"  ADCU
 SG_ Classification_Obj_10 : 98|3@0+ (1,0) [0|7] ""  ADCU
 SG_ Classification_Obj_11 : 330|3@0+ (1,0) [0|7] ""  ADCU
 SG_ CRC16_Checksum_Obj_10_11 : 503|16@0+ (1,0) [0|65535] ""  ADCU
 SG_ DistX_Obj_10 : 7|12@0+ (0.1,-200) [-200|209.5] "m"  ADCU
 SG_ DistX_Obj_11 : 239|12@0+ (0.1,-200) [-200|209.5] "m"  ADCU
 SG_ DistXStd_Obj_10 : 71|8@0+ (0.05,0) [0|12.75] "m"  ADCU
 SG_ DistXStd_Obj_11 : 303|8@0+ (0.05,0) [0|12.75] "m"  ADCU
 SG_ DistY_Obj_10 : 39|12@0+ (0.1,-200) [-200|209.5] "m"  ADCU
 SG_ DistY_Obj_11 : 271|12@0+ (0.1,-200) [-200|209.5] "m"  ADCU
 SG_ DistYStd_Obj_10 : 79|8@0+ (0.1,0) [0|25.5] "m"  ADCU
 SG_ DistYStd_Obj_11 : 311|8@0+ (0.1,0) [0|25.5] "m"  ADCU
 SG_ DynConf_Obj_10 : 121|7@0+ (1,0) [0|127] "%"  ADCU
 SG_ DynConf_Obj_11 : 353|7@0+ (1,0) [0|127] "%"  ADCU
 SG_ DynProp_Obj_10 : 130|3@0+ (1,0) [0|7] ""  ADCU
 SG_ DynProp_Obj_11 : 362|3@0+ (1,0) [0|7] ""  ADCU
 SG_ ID_Obj_10 : 209|8@0+ (1,0) [0|255] ""  ADCU
 SG_ ID_Obj_11 : 441|8@0+ (1,0) [0|255] ""  ADCU
 SG_ Length_Obj_10 : 136|7@0+ (0.2,0) [0|25.4] "m"  ADCU
 SG_ Length_Obj_11 : 368|7@0+ (0.2,0) [0|25.4] "m"  ADCU
 SG_ LifeCycle_Obj_10 : 193|16@0+ (1,0) [0|65535] ""  ADCU
 SG_ LifeCycle_Obj_11 : 425|16@0+ (1,0) [0|65535] ""  ADCU
 SG_ MaintenanceState_Obj_10 : 145|2@0+ (1,0) [0|3] ""  ADCU
 SG_ MaintenanceState_Obj_11 : 377|2@0+ (1,0) [0|3] ""  ADCU
 SG_ MicroDopplerFlag_10 : 472|1@0+ (1,0) [0|1] ""  ADCU
 SG_ MicroDopplerFlag_11 : 480|1@0+ (1,0) [0|1] ""  ADCU
 SG_ MirrorProb_Obj_10 : 143|7@0+ (1,0) [0|127] "%"  ADCU
 SG_ MirrorProb_Obj_11 : 375|7@0+ (1,0) [0|127] "%"  ADCU
 SG_ MsgCounter_Obj_10_11 : 495|8@0+ (1,0) [0|255] ""  ADCU
 SG_ ObstacleProb_Obj_10 : 479|7@0+ (1,0) [0|127] "%"  ADCU
 SG_ ObstacleProb_Obj_11 : 487|7@0+ (1,0) [0|127] "%"  ADCU
 SG_ Orientation_Obj_10 : 175|10@0+ (0.01,-5.11) [-5.11|5.12] "rad"  ADCU
 SG_ Orientation_Obj_11 : 407|10@0+ (0.01,-5.11) [-5.11|5.12] "rad"  ADCU
 SG_ OrientationStd_Obj_10 : 471|4@0+ (0.002,0) [0|0.03] "rad"  ADCU
 SG_ OrientationStd_Obj_11 : 467|4@0+ (0.002,0) [0|0.03] "rad"  ADCU
 SG_ ProbOfExist_Obj_10 : 112|7@0+ (1,0) [0|127] "%"  ADCU
 SG_ ProbOfExist_Obj_11 : 344|7@0+ (1,0) [0|127] "%"  ADCU
 SG_ RCS_Obj_10 : 152|9@0+ (0.2,-51.1) [-51.1|51.1] "dBsm"  ADCU
 SG_ RCS_Obj_11 : 384|9@0+ (0.2,-51.1) [-51.1|51.1] "dBsm"  ADCU
 SG_ RefPoint_Obj_10 : 217|4@0+ (1,0) [0|15] ""  ADCU
 SG_ RefPoint_Obj_11 : 449|4@0+ (1,0) [0|15] ""  ADCU
 SG_ VabsX_Obj_10 : 11|11@0+ (0.125,-128) [-128|127.875] "m/s"  ADCU
 SG_ VabsX_Obj_11 : 243|11@0+ (0.125,-128) [-128|127.875] "m/s"  ADCU
 SG_ VabsXStd_Obj_10 : 87|7@0+ (0.1,0) [0|12.7] "m/s"  ADCU
 SG_ VabsXStd_Obj_11 : 319|7@0+ (0.1,0) [0|12.7] "m/s"  ADCU
 SG_ VabsY_Obj_10 : 43|11@0+ (0.125,-128) [-128|127.875] "m/s"  ADCU
 SG_ VabsY_Obj_11 : 275|11@0+ (0.125,-128) [-128|127.875] "m/s"  ADCU
 SG_ VabsYStd_Obj_10 : 80|7@0+ (0.2,0) [0|25.4] "m/s"  ADCU
 SG_ VabsYStd_Obj_11 : 312|7@0+ (0.2,0) [0|25.4] "m/s"  ADCU
 SG_ Valid_Obj_10 : 229|1@0+ (1,0) [0|1] ""  ADCU
 SG_ Valid_Obj_11 : 461|1@0+ (1,0) [0|1] ""  ADCU
 SG_ Width_Obj_10 : 159|7@0+ (0.2,0) [0|25.4] "m"  ADCU
 SG_ Width_Obj_11 : 391|7@0+ (0.2,0) [0|25.4] "m"  ADCU
 SG_ YawRateAbs_Obj_10 : 181|10@0+ (0.001,-0.511) [-0.511|0.512] "rad/s"  ADCU
 SG_ YawRateAbs_Obj_11 : 413|10@0+ (0.001,-0.511) [-0.511|0.512] "rad/s"  ADCU
 SG_ YawRateAbsStd_Obj_10 : 187|10@0+ (0.0001,0) [0|0.1023] "rad/s"  ADCU
 SG_ YawRateAbsStd_Obj_11 : 419|10@0+ (0.0001,0) [0|0.1023] "rad/s"  ADCU

BO_ 551 RR_Object_12_13: 64 LR
 SG_ AabsX_Obj_12 : 16|9@0+ (0.125,-31.875) [-31.875|32] "m/s^2"  ADCU
 SG_ AabsX_Obj_13 : 248|9@0+ (0.125,-31.875) [-31.875|32] "m/s^2"  ADCU
 SG_ AabsXStd_Obj_12 : 89|7@0+ (0.25,0) [0|31.75] "m/s^2"  ADCU
 SG_ AabsXStd_Obj_13 : 321|7@0+ (0.25,0) [0|31.75] "m/s^2"  ADCU
 SG_ AabsY_Obj_12 : 48|9@0+ (0.125,-31.875) [-31.875|32] "m/s^2"  ADCU
 SG_ AabsY_Obj_13 : 280|9@0+ (0.125,-31.875) [-31.875|32] "m/s^2"  ADCU
 SG_ AabsYStd_Obj_12 : 111|8@0+ (0.25,0) [0|63.75] "m/s^2"  ADCU
 SG_ AabsYStd_Obj_13 : 343|8@0+ (0.25,0) [0|63.75] "m/s^2"  ADCU
 SG_ ClassConf_Obj_12 : 119|7@0+ (1,0) [0|127] "%"  ADCU
 SG_ ClassConf_Obj_13 : 351|7@0+ (1,0) [0|127] "%"  ADCU
 SG_ Classification_Obj_12 : 98|3@0+ (1,0) [0|7] ""  ADCU
 SG_ Classification_Obj_13 : 330|3@0+ (1,0) [0|7] ""  ADCU
 SG_ CRC16_Checksum_Obj_12_13 : 503|16@0+ (1,0) [0|65535] ""  ADCU
 SG_ DistX_Obj_12 : 7|12@0+ (0.1,-200) [-200|209.5] "m"  ADCU
 SG_ DistX_Obj_13 : 239|12@0+ (0.1,-200) [-200|209.5] "m"  ADCU
 SG_ DistXStd_Obj_12 : 71|8@0+ (0.05,0) [0|12.75] "m"  ADCU
 SG_ DistXStd_Obj_13 : 303|8@0+ (0.05,0) [0|12.75] "m"  ADCU
 SG_ DistY_Obj_12 : 39|12@0+ (0.1,-200) [-200|209.5] "m"  ADCU
 SG_ DistY_Obj_13 : 271|12@0+ (0.1,-200) [-200|209.5] "m"  ADCU
 SG_ DistYStd_Obj_12 : 79|8@0+ (0.1,0) [0|25.5] "m"  ADCU
 SG_ DistYStd_Obj_13 : 311|8@0+ (0.1,0) [0|25.5] "m"  ADCU
 SG_ DynConf_Obj_12 : 121|7@0+ (1,0) [0|127] "%"  ADCU
 SG_ DynConf_Obj_13 : 353|7@0+ (1,0) [0|127] "%"  ADCU
 SG_ DynProp_Obj_12 : 130|3@0+ (1,0) [0|7] ""  ADCU
 SG_ DynProp_Obj_13 : 362|3@0+ (1,0) [0|7] ""  ADCU
 SG_ ID_Obj_12 : 209|8@0+ (1,0) [0|255] ""  ADCU
 SG_ ID_Obj_13 : 441|8@0+ (1,0) [0|255] ""  ADCU
 SG_ Length_Obj_12 : 136|7@0+ (0.2,0) [0|25.4] "m"  ADCU
 SG_ Length_Obj_13 : 368|7@0+ (0.2,0) [0|25.4] "m"  ADCU
 SG_ LifeCycle_Obj_12 : 193|16@0+ (1,0) [0|65535] ""  ADCU
 SG_ LifeCycle_Obj_13 : 425|16@0+ (1,0) [0|65535] ""  ADCU
 SG_ MaintenanceState_Obj_12 : 145|2@0+ (1,0) [0|3] ""  ADCU
 SG_ MaintenanceState_Obj_13 : 377|2@0+ (1,0) [0|3] ""  ADCU
 SG_ MicroDopplerFlag_12 : 472|1@0+ (1,0) [0|1] ""  ADCU
 SG_ MicroDopplerFlag_13 : 480|1@0+ (1,0) [0|1] ""  ADCU
 SG_ MirrorProb_Obj_12 : 143|7@0+ (1,0) [0|127] "%"  ADCU
 SG_ MirrorProb_Obj_13 : 375|7@0+ (1,0) [0|127] "%"  ADCU
 SG_ MsgCounter_Obj_00_13 : 495|8@0+ (1,0) [0|255] ""  ADCU
 SG_ ObstacleProb_Obj_12 : 479|7@0+ (1,0) [0|127] "%"  ADCU
 SG_ ObstacleProb_Obj_13 : 487|7@0+ (1,0) [0|127] "%"  ADCU
 SG_ Orientation_Obj_12 : 175|10@0+ (0.01,-5.11) [-5.11|5.12] "rad"  ADCU
 SG_ Orientation_Obj_13 : 407|10@0+ (0.01,-5.11) [-5.11|5.12] "rad"  ADCU
 SG_ OrientationStd_Obj_12 : 471|4@0+ (0.002,0) [0|0.03] "rad"  ADCU
 SG_ OrientationStd_Obj_13 : 467|4@0+ (0.002,0) [0|0.03] "rad"  ADCU
 SG_ ProbOfExist_Obj_12 : 112|7@0+ (1,0) [0|127] "%"  ADCU
 SG_ ProbOfExist_Obj_13 : 344|7@0+ (1,0) [0|127] "%"  ADCU
 SG_ RCS_Obj_12 : 152|9@0+ (0.2,-51.1) [-51.1|51.1] "dBsm"  ADCU
 SG_ RCS_Obj_13 : 384|9@0+ (0.2,-51.1) [-51.1|51.1] "dBsm"  ADCU
 SG_ RefPoint_Obj_12 : 217|4@0+ (1,0) [0|15] ""  ADCU
 SG_ RefPoint_Obj_13 : 449|4@0+ (1,0) [0|15] ""  ADCU
 SG_ VabsX_Obj_12 : 11|11@0+ (0.125,-128) [-128|127.875] "m/s"  ADCU
 SG_ VabsX_Obj_13 : 243|11@0+ (0.125,-128) [-128|127.875] "m/s"  ADCU
 SG_ VabsXStd_Obj_12 : 87|7@0+ (0.1,0) [0|12.7] "m/s"  ADCU
 SG_ VabsXStd_Obj_13 : 319|7@0+ (0.1,0) [0|12.7] "m/s"  ADCU
 SG_ VabsY_Obj_12 : 43|11@0+ (0.125,-128) [-128|127.875] "m/s"  ADCU
 SG_ VabsY_Obj_13 : 275|11@0+ (0.125,-128) [-128|127.875] "m/s"  ADCU
 SG_ VabsYStd_Obj_12 : 80|7@0+ (0.2,0) [0|25.4] "m/s"  ADCU
 SG_ VabsYStd_Obj_13 : 312|7@0+ (0.2,0) [0|25.4] "m/s"  ADCU
 SG_ Valid_Obj_12 : 229|1@0+ (1,0) [0|1] ""  ADCU
 SG_ Valid_Obj_13 : 461|1@0+ (1,0) [0|1] ""  ADCU
 SG_ Width_Obj_12 : 159|7@0+ (0.2,0) [0|25.4] "m"  ADCU
 SG_ Width_Obj_13 : 391|7@0+ (0.2,0) [0|25.4] "m"  ADCU
 SG_ YawRateAbs_Obj_12 : 181|10@0+ (0.001,-0.511) [-0.511|0.512] "rad/s"  ADCU
 SG_ YawRateAbs_Obj_13 : 413|10@0+ (0.001,-0.511) [-0.511|0.512] "rad/s"  ADCU
 SG_ YawRateAbsStd_Obj_12 : 187|10@0+ (0.0001,0) [0|0.1023] "rad/s"  ADCU
 SG_ YawRateAbsStd_Obj_13 : 419|10@0+ (0.0001,0) [0|0.1023] "rad/s"  ADCU

BO_ 552 RR_Object_14_15: 64 LR
 SG_ AabsX_Obj_14 : 16|9@0+ (0.125,-31.875) [-31.875|32] "m/s^2"  ADCU
 SG_ AabsX_Obj_15 : 248|9@0+ (0.125,-31.875) [-31.875|32] "m/s^2"  ADCU
 SG_ AabsXStd_Obj_14 : 89|7@0+ (0.25,0) [0|31.75] "m/s^2"  ADCU
 SG_ AabsXStd_Obj_15 : 321|7@0+ (0.25,0) [0|31.75] "m/s^2"  ADCU
 SG_ AabsY_Obj_14 : 48|9@0+ (0.125,-31.875) [-31.875|32] "m/s^2"  ADCU
 SG_ AabsY_Obj_15 : 280|9@0+ (0.125,-31.875) [-31.875|32] "m/s^2"  ADCU
 SG_ AabsYStd_Obj_14 : 111|8@0+ (0.25,0) [0|63.75] "m/s^2"  ADCU
 SG_ AabsYStd_Obj_15 : 343|8@0+ (0.25,0) [0|63.75] "m/s^2"  ADCU
 SG_ ClassConf_Obj_14 : 119|7@0+ (1,0) [0|127] "%"  ADCU
 SG_ ClassConf_Obj_15 : 351|7@0+ (1,0) [0|127] "%"  ADCU
 SG_ Classification_Obj_14 : 98|3@0+ (1,0) [0|7] ""  ADCU
 SG_ Classification_Obj_15 : 330|3@0+ (1,0) [0|7] ""  ADCU
 SG_ CRC16_Checksum_Obj_14_15 : 503|16@0+ (1,0) [0|65535] ""  ADCU
 SG_ DistX_Obj_14 : 7|12@0+ (0.1,-200) [-200|209.5] "m"  ADCU
 SG_ DistX_Obj_15 : 239|12@0+ (0.1,-200) [-200|209.5] "m"  ADCU
 SG_ DistXStd_Obj_14 : 71|8@0+ (0.05,0) [0|12.75] "m"  ADCU
 SG_ DistXStd_Obj_15 : 303|8@0+ (0.05,0) [0|12.75] "m"  ADCU
 SG_ DistY_Obj_14 : 39|12@0+ (0.1,-200) [-200|209.5] "m"  ADCU
 SG_ DistY_Obj_15 : 271|12@0+ (0.1,-200) [-200|209.5] "m"  ADCU
 SG_ DistYStd_Obj_14 : 79|8@0+ (0.1,0) [0|25.5] "m"  ADCU
 SG_ DistYStd_Obj_15 : 311|8@0+ (0.1,0) [0|25.5] "m"  ADCU
 SG_ DynConf_Obj_14 : 121|7@0+ (1,0) [0|127] "%"  ADCU
 SG_ DynConf_Obj_15 : 353|7@0+ (1,0) [0|127] "%"  ADCU
 SG_ DynProp_Obj_14 : 130|3@0+ (1,0) [0|7] ""  ADCU
 SG_ DynProp_Obj_15 : 362|3@0+ (1,0) [0|7] ""  ADCU
 SG_ ID_Obj_14 : 209|8@0+ (1,0) [0|255] ""  ADCU
 SG_ ID_Obj_15 : 441|8@0+ (1,0) [0|255] ""  ADCU
 SG_ Length_Obj_14 : 136|7@0+ (0.2,0) [0|25.4] "m"  ADCU
 SG_ Length_Obj_15 : 368|7@0+ (0.2,0) [0|25.4] "m"  ADCU
 SG_ LifeCycle_Obj_14 : 193|16@0+ (1,0) [0|65535] ""  ADCU
 SG_ LifeCycle_Obj_15 : 425|16@0+ (1,0) [0|65535] ""  ADCU
 SG_ MaintenanceState_Obj_14 : 145|2@0+ (1,0) [0|3] ""  ADCU
 SG_ MaintenanceState_Obj_15 : 377|2@0+ (1,0) [0|3] ""  ADCU
 SG_ MicroDopplerFlag_14 : 472|1@0+ (1,0) [0|1] ""  ADCU
 SG_ MicroDopplerFlag_15 : 480|1@0+ (1,0) [0|1] ""  ADCU
 SG_ MirrorProb_Obj_14 : 143|7@0+ (1,0) [0|127] "%"  ADCU
 SG_ MirrorProb_Obj_15 : 375|7@0+ (1,0) [0|127] "%"  ADCU
 SG_ MsgCounter_Obj_14_15 : 495|8@0+ (1,0) [0|255] ""  ADCU
 SG_ ObstacleProb_Obj_14 : 479|7@0+ (1,0) [0|127] "%"  ADCU
 SG_ ObstacleProb_Obj_15 : 487|7@0+ (1,0) [0|127] "%"  ADCU
 SG_ Orientation_Obj_14 : 175|10@0+ (0.01,-5.11) [-5.11|5.12] "rad"  ADCU
 SG_ Orientation_Obj_15 : 407|10@0+ (0.01,-5.11) [-5.11|5.12] "rad"  ADCU
 SG_ OrientationStd_Obj_14 : 471|4@0+ (0.002,0) [0|0.03] "rad"  ADCU
 SG_ OrientationStd_Obj_15 : 467|4@0+ (0.002,0) [0|0.03] "rad"  ADCU
 SG_ ProbOfExist_Obj_14 : 112|7@0+ (1,0) [0|127] "%"  ADCU
 SG_ ProbOfExist_Obj_15 : 344|7@0+ (1,0) [0|127] "%"  ADCU
 SG_ RCS_Obj_14 : 152|9@0+ (0.2,-51.1) [-51.1|51.1] "dBsm"  ADCU
 SG_ RCS_Obj_15 : 384|9@0+ (0.2,-51.1) [-51.1|51.1] "dBsm"  ADCU
 SG_ RefPoint_Obj_14 : 217|4@0+ (1,0) [0|15] ""  ADCU
 SG_ RefPoint_Obj_15 : 449|4@0+ (1,0) [0|15] ""  ADCU
 SG_ VabsX_Obj_14 : 11|11@0+ (0.125,-128) [-128|127.875] "m/s"  ADCU
 SG_ VabsX_Obj_15 : 243|11@0+ (0.125,-128) [-128|127.875] "m/s"  ADCU
 SG_ VabsXStd_Obj_14 : 87|7@0+ (0.1,0) [0|12.7] "m/s"  ADCU
 SG_ VabsXStd_Obj_15 : 319|7@0+ (0.1,0) [0|12.7] "m/s"  ADCU
 SG_ VabsY_Obj_14 : 43|11@0+ (0.125,-128) [-128|127.875] "m/s"  ADCU
 SG_ VabsY_Obj_15 : 275|11@0+ (0.125,-128) [-128|127.875] "m/s"  ADCU
 SG_ VabsYStd_Obj_14 : 80|7@0+ (0.2,0) [0|25.4] "m/s"  ADCU
 SG_ VabsYStd_Obj_15 : 312|7@0+ (0.2,0) [0|25.4] "m/s"  ADCU
 SG_ Valid_Obj_14 : 229|1@0+ (1,0) [0|1] ""  ADCU
 SG_ Valid_Obj_15 : 461|1@0+ (1,0) [0|1] ""  ADCU
 SG_ Width_Obj_14 : 159|7@0+ (0.2,0) [0|25.4] "m"  ADCU
 SG_ Width_Obj_15 : 391|7@0+ (0.2,0) [0|25.4] "m"  ADCU
 SG_ YawRateAbs_Obj_14 : 181|10@0+ (0.001,-0.511) [-0.511|0.512] "rad/s"  ADCU
 SG_ YawRateAbs_Obj_15 : 413|10@0+ (0.001,-0.511) [-0.511|0.512] "rad/s"  ADCU
 SG_ YawRateAbsStd_Obj_14 : 187|10@0+ (0.0001,0) [0|0.1023] "rad/s"  ADCU
 SG_ YawRateAbsStd_Obj_15 : 419|10@0+ (0.0001,0) [0|0.1023] "rad/s"  ADCU

BO_ 553 RR_Object_16_17: 64 LR
 SG_ AabsX_Obj_16 : 16|9@0+ (0.125,-31.875) [-31.875|32] "m/s^2"  ADCU
 SG_ AabsX_Obj_17 : 248|9@0+ (0.125,-31.875) [-31.875|32] "m/s^2"  ADCU
 SG_ AabsXStd_Obj_16 : 89|7@0+ (0.25,0) [0|31.75] "m/s^2"  ADCU
 SG_ AabsXStd_Obj_17 : 321|7@0+ (0.25,0) [0|31.75] "m/s^2"  ADCU
 SG_ AabsY_Obj_16 : 48|9@0+ (0.125,-31.875) [-31.875|32] "m/s^2"  ADCU
 SG_ AabsY_Obj_17 : 280|9@0+ (0.125,-31.875) [-31.875|32] "m/s^2"  ADCU
 SG_ AabsYStd_Obj_16 : 111|8@0+ (0.25,0) [0|63.75] "m/s^2"  ADCU
 SG_ AabsYStd_Obj_17 : 343|8@0+ (0.25,0) [0|63.75] "m/s^2"  ADCU
 SG_ ClassConf_Obj_16 : 119|7@0+ (1,0) [0|127] "%"  ADCU
 SG_ ClassConf_Obj_17 : 351|7@0+ (1,0) [0|127] "%"  ADCU
 SG_ Classification_Obj_16 : 98|3@0+ (1,0) [0|7] ""  ADCU
 SG_ Classification_Obj_17 : 330|3@0+ (1,0) [0|7] ""  ADCU
 SG_ CRC16_Checksum_Obj_16_17 : 503|16@0+ (1,0) [0|65535] ""  ADCU
 SG_ DistX_Obj_16 : 7|12@0+ (0.1,-200) [-200|209.5] "m"  ADCU
 SG_ DistX_Obj_17 : 239|12@0+ (0.1,-200) [-200|209.5] "m"  ADCU
 SG_ DistXStd_Obj_16 : 71|8@0+ (0.05,0) [0|12.75] "m"  ADCU
 SG_ DistXStd_Obj_17 : 303|8@0+ (0.05,0) [0|12.75] "m"  ADCU
 SG_ DistY_Obj_16 : 39|12@0+ (0.1,-200) [-200|209.5] "m"  ADCU
 SG_ DistY_Obj_17 : 271|12@0+ (0.1,-200) [-200|209.5] "m"  ADCU
 SG_ DistYStd_Obj_16 : 79|8@0+ (0.1,0) [0|25.5] "m"  ADCU
 SG_ DistYStd_Obj_17 : 311|8@0+ (0.1,0) [0|25.5] "m"  ADCU
 SG_ DynConf_Obj_16 : 121|7@0+ (1,0) [0|127] "%"  ADCU
 SG_ DynConf_Obj_17 : 353|7@0+ (1,0) [0|127] "%"  ADCU
 SG_ DynProp_Obj_16 : 130|3@0+ (1,0) [0|7] ""  ADCU
 SG_ DynProp_Obj_17 : 362|3@0+ (1,0) [0|7] ""  ADCU
 SG_ ID_Obj_16 : 209|8@0+ (1,0) [0|255] ""  ADCU
 SG_ ID_Obj_17 : 441|8@0+ (1,0) [0|255] ""  ADCU
 SG_ Length_Obj_16 : 136|7@0+ (0.2,0) [0|25.4] "m"  ADCU
 SG_ Length_Obj_17 : 368|7@0+ (0.2,0) [0|25.4] "m"  ADCU
 SG_ LifeCycle_Obj_16 : 193|16@0+ (1,0) [0|65535] ""  ADCU
 SG_ LifeCycle_Obj_17 : 425|16@0+ (1,0) [0|65535] ""  ADCU
 SG_ MaintenanceState_Obj_16 : 145|2@0+ (1,0) [0|3] ""  ADCU
 SG_ MaintenanceState_Obj_17 : 377|2@0+ (1,0) [0|3] ""  ADCU
 SG_ MicroDopplerFlag_16 : 472|1@0+ (1,0) [0|1] ""  ADCU
 SG_ MicroDopplerFlag_17 : 480|1@0+ (1,0) [0|1] ""  ADCU
 SG_ MirrorProb_Obj_16 : 143|7@0+ (1,0) [0|127] "%"  ADCU
 SG_ MirrorProb_Obj_17 : 375|7@0+ (1,0) [0|127] "%"  ADCU
 SG_ MsgCounter_Obj_16_17 : 495|8@0+ (1,0) [0|255] ""  ADCU
 SG_ ObstacleProb_Obj_16 : 479|7@0+ (1,0) [0|127] "%"  ADCU
 SG_ ObstacleProb_Obj_17 : 487|7@0+ (1,0) [0|127] "%"  ADCU
 SG_ Orientation_Obj_16 : 175|10@0+ (0.01,-5.11) [-5.11|5.12] "rad"  ADCU
 SG_ Orientation_Obj_17 : 407|10@0+ (0.01,-5.11) [-5.11|5.12] "rad"  ADCU
 SG_ OrientationStd_Obj_16 : 471|4@0+ (0.002,0) [0|0.03] "rad"  ADCU
 SG_ OrientationStd_Obj_17 : 467|4@0+ (0.002,0) [0|0.03] "rad"  ADCU
 SG_ ProbOfExist_Obj_16 : 112|7@0+ (1,0) [0|127] "%"  ADCU
 SG_ ProbOfExist_Obj_17 : 344|7@0+ (1,0) [0|127] "%"  ADCU
 SG_ RCS_Obj_16 : 152|9@0+ (0.2,-51.1) [-51.1|51.1] "dBsm"  ADCU
 SG_ RCS_Obj_17 : 384|9@0+ (0.2,-51.1) [-51.1|51.1] "dBsm"  ADCU
 SG_ RefPoint_Obj_16 : 217|4@0+ (1,0) [0|15] ""  ADCU
 SG_ RefPoint_Obj_17 : 449|4@0+ (1,0) [0|15] ""  ADCU
 SG_ VabsX_Obj_16 : 11|11@0+ (0.125,-128) [-128|127.875] "m/s"  ADCU
 SG_ VabsX_Obj_17 : 243|11@0+ (0.125,-128) [-128|127.875] "m/s"  ADCU
 SG_ VabsXStd_Obj_16 : 87|7@0+ (0.1,0) [0|12.7] "m/s"  ADCU
 SG_ VabsXStd_Obj_17 : 319|7@0+ (0.1,0) [0|12.7] "m/s"  ADCU
 SG_ VabsY_Obj_16 : 43|11@0+ (0.125,-128) [-128|127.875] "m/s"  ADCU
 SG_ VabsY_Obj_17 : 275|11@0+ (0.125,-128) [-128|127.875] "m/s"  ADCU
 SG_ VabsYStd_Obj_16 : 80|7@0+ (0.2,0) [0|25.4] "m/s"  ADCU
 SG_ VabsYStd_Obj_17 : 312|7@0+ (0.2,0) [0|25.4] "m/s"  ADCU
 SG_ Valid_Obj_16 : 229|1@0+ (1,0) [0|1] ""  ADCU
 SG_ Valid_Obj_17 : 461|1@0+ (1,0) [0|1] ""  ADCU
 SG_ Width_Obj_16 : 159|7@0+ (0.2,0) [0|25.4] "m"  ADCU
 SG_ Width_Obj_17 : 391|7@0+ (0.2,0) [0|25.4] "m"  ADCU
 SG_ YawRateAbs_Obj_16 : 181|10@0+ (0.001,-0.511) [-0.511|0.512] "rad/s"  ADCU
 SG_ YawRateAbs_Obj_17 : 413|10@0+ (0.001,-0.511) [-0.511|0.512] "rad/s"  ADCU
 SG_ YawRateAbsStd_Obj_16 : 187|10@0+ (0.0001,0) [0|0.1023] "rad/s"  ADCU
 SG_ YawRateAbsStd_Obj_17 : 419|10@0+ (0.0001,0) [0|0.1023] "rad/s"  ADCU

BO_ 554 RR_Object_18_19: 64 LR
 SG_ AabsX_Obj_18 : 16|9@0+ (0.125,-31.875) [-31.875|32] "m/s^2"  ADCU
 SG_ AabsX_Obj_19 : 248|9@0+ (0.125,-31.875) [-31.875|32] "m/s^2"  ADCU
 SG_ AabsXStd_Obj_18 : 89|7@0+ (0.25,0) [0|31.75] "m/s^2"  ADCU
 SG_ AabsXStd_Obj_19 : 321|7@0+ (0.25,0) [0|31.75] "m/s^2"  ADCU
 SG_ AabsY_Obj_18 : 48|9@0+ (0.125,-31.875) [-31.875|32] "m/s^2"  ADCU
 SG_ AabsY_Obj_19 : 280|9@0+ (0.125,-31.875) [-31.875|32] "m/s^2"  ADCU
 SG_ AabsYStd_Obj_18 : 111|8@0+ (0.25,0) [0|63.75] "m/s^2"  ADCU
 SG_ AabsYStd_Obj_19 : 343|8@0+ (0.25,0) [0|63.75] "m/s^2"  ADCU
 SG_ ClassConf_Obj_18 : 119|7@0+ (1,0) [0|127] "%"  ADCU
 SG_ ClassConf_Obj_19 : 351|7@0+ (1,0) [0|127] "%"  ADCU
 SG_ Classification_Obj_18 : 98|3@0+ (1,0) [0|7] ""  ADCU
 SG_ Classification_Obj_19 : 330|3@0+ (1,0) [0|7] ""  ADCU
 SG_ CRC16_Checksum_Obj_18_19 : 503|16@0+ (1,0) [0|65535] ""  ADCU
 SG_ DistX_Obj_18 : 7|12@0+ (0.1,-200) [-200|209.5] "m"  ADCU
 SG_ DistX_Obj_19 : 239|12@0+ (0.1,-200) [-200|209.5] "m"  ADCU
 SG_ DistXStd_Obj_18 : 71|8@0+ (0.05,0) [0|12.75] "m"  ADCU
 SG_ DistXStd_Obj_19 : 303|8@0+ (0.05,0) [0|12.75] "m"  ADCU
 SG_ DistY_Obj_18 : 39|12@0+ (0.1,-200) [-200|209.5] "m"  ADCU
 SG_ DistY_Obj_19 : 271|12@0+ (0.1,-200) [-200|209.5] "m"  ADCU
 SG_ DistYStd_Obj_18 : 79|8@0+ (0.1,0) [0|25.5] "m"  ADCU
 SG_ DistYStd_Obj_19 : 311|8@0+ (0.1,0) [0|25.5] "m"  ADCU
 SG_ DynConf_Obj_18 : 121|7@0+ (1,0) [0|127] "%"  ADCU
 SG_ DynConf_Obj_19 : 353|7@0+ (1,0) [0|127] "%"  ADCU
 SG_ DynProp_Obj_18 : 130|3@0+ (1,0) [0|7] ""  ADCU
 SG_ DynProp_Obj_19 : 362|3@0+ (1,0) [0|7] ""  ADCU
 SG_ ID_Obj_18 : 209|8@0+ (1,0) [0|255] ""  ADCU
 SG_ ID_Obj_19 : 441|8@0+ (1,0) [0|255] ""  ADCU
 SG_ Length_Obj_18 : 136|7@0+ (0.2,0) [0|25.4] "m"  ADCU
 SG_ Length_Obj_19 : 368|7@0+ (0.2,0) [0|25.4] "m"  ADCU
 SG_ LifeCycle_Obj_18 : 193|16@0+ (1,0) [0|65535] ""  ADCU
 SG_ LifeCycle_Obj_19 : 425|16@0+ (1,0) [0|65535] ""  ADCU
 SG_ MaintenanceState_Obj_18 : 145|2@0+ (1,0) [0|3] ""  ADCU
 SG_ MaintenanceState_Obj_19 : 377|2@0+ (1,0) [0|3] ""  ADCU
 SG_ MicroDopplerFlag_18 : 472|1@0+ (1,0) [0|1] ""  ADCU
 SG_ MicroDopplerFlag_19 : 480|1@0+ (1,0) [0|1] ""  ADCU
 SG_ MirrorProb_Obj_18 : 143|7@0+ (1,0) [0|127] "%"  ADCU
 SG_ MirrorProb_Obj_19 : 375|7@0+ (1,0) [0|127] "%"  ADCU
 SG_ MsgCounter_Obj_18_19 : 495|8@0+ (1,0) [0|255] ""  ADCU
 SG_ ObstacleProb_Obj_18 : 479|7@0+ (1,0) [0|127] "%"  ADCU
 SG_ ObstacleProb_Obj_19 : 487|7@0+ (1,0) [0|127] "%"  ADCU
 SG_ Orientation_Obj_18 : 175|10@0+ (0.01,-5.11) [-5.11|5.12] "rad"  ADCU
 SG_ Orientation_Obj_19 : 407|10@0+ (0.01,-5.11) [-5.11|5.12] "rad"  ADCU
 SG_ OrientationStd_Obj_18 : 471|4@0+ (0.002,0) [0|0.03] "rad"  ADCU
 SG_ OrientationStd_Obj_19 : 467|4@0+ (0.002,0) [0|0.03] "rad"  ADCU
 SG_ ProbOfExist_Obj_18 : 112|7@0+ (1,0) [0|127] "%"  ADCU
 SG_ ProbOfExist_Obj_19 : 344|7@0+ (1,0) [0|127] "%"  ADCU
 SG_ RCS_Obj_18 : 152|9@0+ (0.2,-51.1) [-51.1|51.1] "dBsm"  ADCU
 SG_ RCS_Obj_19 : 384|9@0+ (0.2,-51.1) [-51.1|51.1] "dBsm"  ADCU
 SG_ RefPoint_Obj_18 : 217|4@0+ (1,0) [0|15] ""  ADCU
 SG_ RefPoint_Obj_19 : 449|4@0+ (1,0) [0|15] ""  ADCU
 SG_ VabsX_Obj_18 : 11|11@0+ (0.125,-128) [-128|127.875] "m/s"  ADCU
 SG_ VabsX_Obj_19 : 243|11@0+ (0.125,-128) [-128|127.875] "m/s"  ADCU
 SG_ VabsXStd_Obj_18 : 87|7@0+ (0.1,0) [0|12.7] "m/s"  ADCU
 SG_ VabsXStd_Obj_19 : 319|7@0+ (0.1,0) [0|12.7] "m/s"  ADCU
 SG_ VabsY_Obj_18 : 43|11@0+ (0.125,-128) [-128|127.875] "m/s"  ADCU
 SG_ VabsY_Obj_19 : 275|11@0+ (0.125,-128) [-128|127.875] "m/s"  ADCU
 SG_ VabsYStd_Obj_18 : 80|7@0+ (0.2,0) [0|25.4] "m/s"  ADCU
 SG_ VabsYStd_Obj_19 : 312|7@0+ (0.2,0) [0|25.4] "m/s"  ADCU
 SG_ Valid_Obj_18 : 229|1@0+ (1,0) [0|1] ""  ADCU
 SG_ Valid_Obj_19 : 461|1@0+ (1,0) [0|1] ""  ADCU
 SG_ Width_Obj_18 : 159|7@0+ (0.2,0) [0|25.4] "m"  ADCU
 SG_ Width_Obj_19 : 391|7@0+ (0.2,0) [0|25.4] "m"  ADCU
 SG_ YawRateAbs_Obj_18 : 181|10@0+ (0.001,-0.511) [-0.511|0.512] "rad/s"  ADCU
 SG_ YawRateAbs_Obj_19 : 413|10@0+ (0.001,-0.511) [-0.511|0.512] "rad/s"  ADCU
 SG_ YawRateAbsStd_Obj_18 : 187|10@0+ (0.0001,0) [0|0.1023] "rad/s"  ADCU
 SG_ YawRateAbsStd_Obj_19 : 419|10@0+ (0.0001,0) [0|0.1023] "rad/s"  ADCU

BO_ 555 RR_Object_20_21: 64 LR
 SG_ AabsX_Obj_20 : 16|9@0+ (0.125,-31.875) [-31.875|32] "m/s^2"  ADCU
 SG_ AabsX_Obj_21 : 248|9@0+ (0.125,-31.875) [-31.875|32] "m/s^2"  ADCU
 SG_ AabsXStd_Obj_20 : 89|7@0+ (0.25,0) [0|31.75] "m/s^2"  ADCU
 SG_ AabsXStd_Obj_21 : 321|7@0+ (0.25,0) [0|31.75] "m/s^2"  ADCU
 SG_ AabsY_Obj_20 : 48|9@0+ (0.125,-31.875) [-31.875|32] "m/s^2"  ADCU
 SG_ AabsY_Obj_21 : 280|9@0+ (0.125,-31.875) [-31.875|32] "m/s^2"  ADCU
 SG_ AabsYStd_Obj_20 : 111|8@0+ (0.25,0) [0|63.75] "m/s^2"  ADCU
 SG_ AabsYStd_Obj_21 : 343|8@0+ (0.25,0) [0|63.75] "m/s^2"  ADCU
 SG_ ClassConf_Obj_20 : 119|7@0+ (1,0) [0|127] "%"  ADCU
 SG_ ClassConf_Obj_21 : 351|7@0+ (1,0) [0|127] "%"  ADCU
 SG_ Classification_Obj_20 : 98|3@0+ (1,0) [0|7] ""  ADCU
 SG_ Classification_Obj_21 : 330|3@0+ (1,0) [0|7] ""  ADCU
 SG_ CRC16_Checksum_Obj_20_21 : 503|16@0+ (1,0) [0|65535] ""  ADCU
 SG_ DistX_Obj_20 : 7|12@0+ (0.1,-200) [-200|209.5] "m"  ADCU
 SG_ DistX_Obj_21 : 239|12@0+ (0.1,-200) [-200|209.5] "m"  ADCU
 SG_ DistXStd_Obj_20 : 71|8@0+ (0.05,0) [0|12.75] "m"  ADCU
 SG_ DistXStd_Obj_21 : 303|8@0+ (0.05,0) [0|12.75] "m"  ADCU
 SG_ DistY_Obj_20 : 39|12@0+ (0.1,-200) [-200|209.5] "m"  ADCU
 SG_ DistY_Obj_21 : 271|12@0+ (0.1,-200) [-200|209.5] "m"  ADCU
 SG_ DistYStd_Obj_20 : 79|8@0+ (0.1,0) [0|25.5] "m"  ADCU
 SG_ DistYStd_Obj_21 : 311|8@0+ (0.1,0) [0|25.5] "m"  ADCU
 SG_ DynConf_Obj_20 : 121|7@0+ (1,0) [0|127] "%"  ADCU
 SG_ DynConf_Obj_21 : 353|7@0+ (1,0) [0|127] "%"  ADCU
 SG_ DynProp_Obj_20 : 130|3@0+ (1,0) [0|7] ""  ADCU
 SG_ DynProp_Obj_21 : 362|3@0+ (1,0) [0|7] ""  ADCU
 SG_ ID_Obj_20 : 209|8@0+ (1,0) [0|255] ""  ADCU
 SG_ ID_Obj_21 : 441|8@0+ (1,0) [0|255] ""  ADCU
 SG_ Length_Obj_20 : 136|7@0+ (0.2,0) [0|25.4] "m"  ADCU
 SG_ Length_Obj_21 : 368|7@0+ (0.2,0) [0|25.4] "m"  ADCU
 SG_ LifeCycle_Obj_20 : 193|16@0+ (1,0) [0|65535] ""  ADCU
 SG_ LifeCycle_Obj_21 : 425|16@0+ (1,0) [0|65535] ""  ADCU
 SG_ MaintenanceState_Obj_20 : 145|2@0+ (1,0) [0|3] ""  ADCU
 SG_ MaintenanceState_Obj_21 : 377|2@0+ (1,0) [0|3] ""  ADCU
 SG_ MicroDopplerFlag_20 : 472|1@0+ (1,0) [0|1] ""  ADCU
 SG_ MicroDopplerFlag_21 : 480|1@0+ (1,0) [0|1] ""  ADCU
 SG_ MirrorProb_Obj_20 : 143|7@0+ (1,0) [0|127] "%"  ADCU
 SG_ MirrorProb_Obj_21 : 375|7@0+ (1,0) [0|127] "%"  ADCU
 SG_ MsgCounter_Obj_20_21 : 495|8@0+ (1,0) [0|255] ""  ADCU
 SG_ ObstacleProb_Obj_20 : 479|7@0+ (1,0) [0|127] "%"  ADCU
 SG_ ObstacleProb_Obj_21 : 487|7@0+ (1,0) [0|127] "%"  ADCU
 SG_ Orientation_Obj_20 : 175|10@0+ (0.01,-5.11) [-5.11|5.12] "rad"  ADCU
 SG_ Orientation_Obj_21 : 407|10@0+ (0.01,-5.11) [-5.11|5.12] "rad"  ADCU
 SG_ OrientationStd_Obj_20 : 471|4@0+ (0.002,0) [0|0.03] "rad"  ADCU
 SG_ OrientationStd_Obj_21 : 467|4@0+ (0.002,0) [0|0.03] "rad"  ADCU
 SG_ ProbOfExist_Obj_20 : 112|7@0+ (1,0) [0|127] "%"  ADCU
 SG_ ProbOfExist_Obj_21 : 344|7@0+ (1,0) [0|127] "%"  ADCU
 SG_ RCS_Obj_20 : 152|9@0+ (0.2,-51.1) [-51.1|51.1] "dBsm"  ADCU
 SG_ RCS_Obj_21 : 384|9@0+ (0.2,-51.1) [-51.1|51.1] "dBsm"  ADCU
 SG_ RefPoint_Obj_20 : 217|4@0+ (1,0) [0|15] ""  ADCU
 SG_ RefPoint_Obj_21 : 449|4@0+ (1,0) [0|15] ""  ADCU
 SG_ VabsX_Obj_20 : 11|11@0+ (0.125,-128) [-128|127.875] "m/s"  ADCU
 SG_ VabsX_Obj_21 : 243|11@0+ (0.125,-128) [-128|127.875] "m/s"  ADCU
 SG_ VabsXStd_Obj_20 : 87|7@0+ (0.1,0) [0|12.7] "m/s"  ADCU
 SG_ VabsXStd_Obj_21 : 319|7@0+ (0.1,0) [0|12.7] "m/s"  ADCU
 SG_ VabsY_Obj_20 : 43|11@0+ (0.125,-128) [-128|127.875] "m/s"  ADCU
 SG_ VabsY_Obj_21 : 275|11@0+ (0.125,-128) [-128|127.875] "m/s"  ADCU
 SG_ VabsYStd_Obj_20 : 80|7@0+ (0.2,0) [0|25.4] "m/s"  ADCU
 SG_ VabsYStd_Obj_21 : 312|7@0+ (0.2,0) [0|25.4] "m/s"  ADCU
 SG_ Valid_Obj_20 : 229|1@0+ (1,0) [0|1] ""  ADCU
 SG_ Valid_Obj_21 : 461|1@0+ (1,0) [0|1] ""  ADCU
 SG_ Width_Obj_20 : 159|7@0+ (0.2,0) [0|25.4] "m"  ADCU
 SG_ Width_Obj_21 : 391|7@0+ (0.2,0) [0|25.4] "m"  ADCU
 SG_ YawRateAbs_Obj_20 : 181|10@0+ (0.001,-0.511) [-0.511|0.512] "rad/s"  ADCU
 SG_ YawRateAbs_Obj_21 : 413|10@0+ (0.001,-0.511) [-0.511|0.512] "rad/s"  ADCU
 SG_ YawRateAbsStd_Obj_20 : 187|10@0+ (0.0001,0) [0|0.1023] "rad/s"  ADCU
 SG_ YawRateAbsStd_Obj_21 : 419|10@0+ (0.0001,0) [0|0.1023] "rad/s"  ADCU

BO_ 556 RR_Object_22_23: 64 LR
 SG_ AabsX_Obj_22 : 16|9@0+ (0.125,-31.875) [-31.875|32] "m/s^2"  ADCU
 SG_ AabsX_Obj_23 : 248|9@0+ (0.125,-31.875) [-31.875|32] "m/s^2"  ADCU
 SG_ AabsXStd_Obj_22 : 89|7@0+ (0.25,0) [0|31.75] "m/s^2"  ADCU
 SG_ AabsXStd_Obj_23 : 321|7@0+ (0.25,0) [0|31.75] "m/s^2"  ADCU
 SG_ AabsY_Obj_22 : 48|9@0+ (0.125,-31.875) [-31.875|32] "m/s^2"  ADCU
 SG_ AabsY_Obj_23 : 280|9@0+ (0.125,-31.875) [-31.875|32] "m/s^2"  ADCU
 SG_ AabsYStd_Obj_22 : 111|8@0+ (0.25,0) [0|63.75] "m/s^2"  ADCU
 SG_ AabsYStd_Obj_23 : 343|8@0+ (0.25,0) [0|63.75] "m/s^2"  ADCU
 SG_ ClassConf_Obj_22 : 119|7@0+ (1,0) [0|127] "%"  ADCU
 SG_ ClassConf_Obj_23 : 351|7@0+ (1,0) [0|127] "%"  ADCU
 SG_ Classification_Obj_22 : 98|3@0+ (1,0) [0|7] ""  ADCU
 SG_ Classification_Obj_23 : 330|3@0+ (1,0) [0|7] ""  ADCU
 SG_ CRC16_Checksum_Obj_22_23 : 503|16@0+ (1,0) [0|65535] ""  ADCU
 SG_ DistX_Obj_22 : 7|12@0+ (0.1,-200) [-200|209.5] "m"  ADCU
 SG_ DistX_Obj_23 : 239|12@0+ (0.1,-200) [-200|209.5] "m"  ADCU
 SG_ DistXStd_Obj_22 : 71|8@0+ (0.05,0) [0|12.75] "m"  ADCU
 SG_ DistXStd_Obj_23 : 303|8@0+ (0.05,0) [0|12.75] "m"  ADCU
 SG_ DistY_Obj_22 : 39|12@0+ (0.1,-200) [-200|209.5] "m"  ADCU
 SG_ DistY_Obj_23 : 271|12@0+ (0.1,-200) [-200|209.5] "m"  ADCU
 SG_ DistYStd_Obj_22 : 79|8@0+ (0.1,0) [0|25.5] "m"  ADCU
 SG_ DistYStd_Obj_23 : 311|8@0+ (0.1,0) [0|25.5] "m"  ADCU
 SG_ DynConf_Obj_22 : 121|7@0+ (1,0) [0|127] "%"  ADCU
 SG_ DynConf_Obj_23 : 353|7@0+ (1,0) [0|127] "%"  ADCU
 SG_ DynProp_Obj_22 : 130|3@0+ (1,0) [0|7] ""  ADCU
 SG_ DynProp_Obj_23 : 362|3@0+ (1,0) [0|7] ""  ADCU
 SG_ ID_Obj_22 : 209|8@0+ (1,0) [0|255] ""  ADCU
 SG_ ID_Obj_23 : 441|8@0+ (1,0) [0|255] ""  ADCU
 SG_ Length_Obj_22 : 136|7@0+ (0.2,0) [0|25.4] "m"  ADCU
 SG_ Length_Obj_23 : 368|7@0+ (0.2,0) [0|25.4] "m"  ADCU
 SG_ LifeCycle_Obj_22 : 193|16@0+ (1,0) [0|65535] ""  ADCU
 SG_ LifeCycle_Obj_23 : 425|16@0+ (1,0) [0|65535] ""  ADCU
 SG_ MaintenanceState_Obj_22 : 145|2@0+ (1,0) [0|3] ""  ADCU
 SG_ MaintenanceState_Obj_23 : 377|2@0+ (1,0) [0|3] ""  ADCU
 SG_ MicroDopplerFlag_22 : 472|1@0+ (1,0) [0|1] ""  ADCU
 SG_ MicroDopplerFlag_23 : 480|1@0+ (1,0) [0|1] ""  ADCU
 SG_ MirrorProb_Obj_22 : 143|7@0+ (1,0) [0|127] "%"  ADCU
 SG_ MirrorProb_Obj_23 : 375|7@0+ (1,0) [0|127] "%"  ADCU
 SG_ MsgCounter_Obj_00_23 : 495|8@0+ (1,0) [0|255] ""  ADCU
 SG_ ObstacleProb_Obj_22 : 479|7@0+ (1,0) [0|127] "%"  ADCU
 SG_ ObstacleProb_Obj_23 : 487|7@0+ (1,0) [0|127] "%"  ADCU
 SG_ Orientation_Obj_22 : 175|10@0+ (0.01,-5.11) [-5.11|5.12] "rad"  ADCU
 SG_ Orientation_Obj_23 : 407|10@0+ (0.01,-5.11) [-5.11|5.12] "rad"  ADCU
 SG_ OrientationStd_Obj_22 : 471|4@0+ (0.002,0) [0|0.03] "rad"  ADCU
 SG_ OrientationStd_Obj_23 : 467|4@0+ (0.002,0) [0|0.03] "rad"  ADCU
 SG_ ProbOfExist_Obj_22 : 112|7@0+ (1,0) [0|127] "%"  ADCU
 SG_ ProbOfExist_Obj_23 : 344|7@0+ (1,0) [0|127] "%"  ADCU
 SG_ RCS_Obj_22 : 152|9@0+ (0.2,-51.1) [-51.1|51.1] "dBsm"  ADCU
 SG_ RCS_Obj_23 : 384|9@0+ (0.2,-51.1) [-51.1|51.1] "dBsm"  ADCU
 SG_ RefPoint_Obj_22 : 217|4@0+ (1,0) [0|15] ""  ADCU
 SG_ RefPoint_Obj_23 : 449|4@0+ (1,0) [0|15] ""  ADCU
 SG_ VabsX_Obj_22 : 11|11@0+ (0.125,-128) [-128|127.875] "m/s"  ADCU
 SG_ VabsX_Obj_23 : 243|11@0+ (0.125,-128) [-128|127.875] "m/s"  ADCU
 SG_ VabsXStd_Obj_22 : 87|7@0+ (0.1,0) [0|12.7] "m/s"  ADCU
 SG_ VabsXStd_Obj_23 : 319|7@0+ (0.1,0) [0|12.7] "m/s"  ADCU
 SG_ VabsY_Obj_22 : 43|11@0+ (0.125,-128) [-128|127.875] "m/s"  ADCU
 SG_ VabsY_Obj_23 : 275|11@0+ (0.125,-128) [-128|127.875] "m/s"  ADCU
 SG_ VabsYStd_Obj_22 : 80|7@0+ (0.2,0) [0|25.4] "m/s"  ADCU
 SG_ VabsYStd_Obj_23 : 312|7@0+ (0.2,0) [0|25.4] "m/s"  ADCU
 SG_ Valid_Obj_22 : 229|1@0+ (1,0) [0|1] ""  ADCU
 SG_ Valid_Obj_23 : 461|1@0+ (1,0) [0|1] ""  ADCU
 SG_ Width_Obj_22 : 159|7@0+ (0.2,0) [0|25.4] "m"  ADCU
 SG_ Width_Obj_23 : 391|7@0+ (0.2,0) [0|25.4] "m"  ADCU
 SG_ YawRateAbs_Obj_22 : 181|10@0+ (0.001,-0.511) [-0.511|0.512] "rad/s"  ADCU
 SG_ YawRateAbs_Obj_23 : 413|10@0+ (0.001,-0.511) [-0.511|0.512] "rad/s"  ADCU
 SG_ YawRateAbsStd_Obj_22 : 187|10@0+ (0.0001,0) [0|0.1023] "rad/s"  ADCU
 SG_ YawRateAbsStd_Obj_23 : 419|10@0+ (0.0001,0) [0|0.1023] "rad/s"  ADCU

BO_ 557 RR_Object_24_25: 64 LR
 SG_ AabsX_Obj_24 : 16|9@0+ (0.125,-31.875) [-31.875|32] "m/s^2"  ADCU
 SG_ AabsX_Obj_25 : 248|9@0+ (0.125,-31.875) [-31.875|32] "m/s^2"  ADCU
 SG_ AabsXStd_Obj_24 : 89|7@0+ (0.25,0) [0|31.75] "m/s^2"  ADCU
 SG_ AabsXStd_Obj_25 : 321|7@0+ (0.25,0) [0|31.75] "m/s^2"  ADCU
 SG_ AabsY_Obj_24 : 48|9@0+ (0.125,-31.875) [-31.875|32] "m/s^2"  ADCU
 SG_ AabsY_Obj_25 : 280|9@0+ (0.125,-31.875) [-31.875|32] "m/s^2"  ADCU
 SG_ AabsYStd_Obj_24 : 111|8@0+ (0.25,0) [0|63.75] "m/s^2"  ADCU
 SG_ AabsYStd_Obj_25 : 343|8@0+ (0.25,0) [0|63.75] "m/s^2"  ADCU
 SG_ ClassConf_Obj_24 : 119|7@0+ (1,0) [0|127] "%"  ADCU
 SG_ ClassConf_Obj_25 : 351|7@0+ (1,0) [0|127] "%"  ADCU
 SG_ Classification_Obj_24 : 98|3@0+ (1,0) [0|7] ""  ADCU
 SG_ Classification_Obj_25 : 330|3@0+ (1,0) [0|7] ""  ADCU
 SG_ CRC16_Checksum_Obj_24_25 : 503|16@0+ (1,0) [0|65535] ""  ADCU
 SG_ DistX_Obj_24 : 7|12@0+ (0.1,-200) [-200|209.5] "m"  ADCU
 SG_ DistX_Obj_25 : 239|12@0+ (0.1,-200) [-200|209.5] "m"  ADCU
 SG_ DistXStd_Obj_24 : 71|8@0+ (0.05,0) [0|12.75] "m"  ADCU
 SG_ DistXStd_Obj_25 : 303|8@0+ (0.05,0) [0|12.75] "m"  ADCU
 SG_ DistY_Obj_24 : 39|12@0+ (0.1,-200) [-200|209.5] "m"  ADCU
 SG_ DistY_Obj_25 : 271|12@0+ (0.1,-200) [-200|209.5] "m"  ADCU
 SG_ DistYStd_Obj_24 : 79|8@0+ (0.1,0) [0|25.5] "m"  ADCU
 SG_ DistYStd_Obj_25 : 311|8@0+ (0.1,0) [0|25.5] "m"  ADCU
 SG_ DynConf_Obj_24 : 121|7@0+ (1,0) [0|127] "%"  ADCU
 SG_ DynConf_Obj_25 : 353|7@0+ (1,0) [0|127] "%"  ADCU
 SG_ DynProp_Obj_24 : 130|3@0+ (1,0) [0|7] ""  ADCU
 SG_ DynProp_Obj_25 : 362|3@0+ (1,0) [0|7] ""  ADCU
 SG_ ID_Obj_24 : 209|8@0+ (1,0) [0|255] ""  ADCU
 SG_ ID_Obj_25 : 441|8@0+ (1,0) [0|255] ""  ADCU
 SG_ Length_Obj_24 : 136|7@0+ (0.2,0) [0|25.4] "m"  ADCU
 SG_ Length_Obj_25 : 368|7@0+ (0.2,0) [0|25.4] "m"  ADCU
 SG_ LifeCycle_Obj_24 : 193|16@0+ (1,0) [0|65535] ""  ADCU
 SG_ LifeCycle_Obj_25 : 425|16@0+ (1,0) [0|65535] ""  ADCU
 SG_ MaintenanceState_Obj_24 : 145|2@0+ (1,0) [0|3] ""  ADCU
 SG_ MaintenanceState_Obj_25 : 377|2@0+ (1,0) [0|3] ""  ADCU
 SG_ MicroDopplerFlag_24 : 472|1@0+ (1,0) [0|1] ""  ADCU
 SG_ MicroDopplerFlag_25 : 480|1@0+ (1,0) [0|1] ""  ADCU
 SG_ MirrorProb_Obj_24 : 143|7@0+ (1,0) [0|127] "%"  ADCU
 SG_ MirrorProb_Obj_25 : 375|7@0+ (1,0) [0|127] "%"  ADCU
 SG_ MsgCounter_Obj_24_25 : 495|8@0+ (1,0) [0|255] ""  ADCU
 SG_ ObstacleProb_Obj_24 : 479|7@0+ (1,0) [0|127] "%"  ADCU
 SG_ ObstacleProb_Obj_25 : 487|7@0+ (1,0) [0|127] "%"  ADCU
 SG_ Orientation_Obj_24 : 175|10@0+ (0.01,-5.11) [-5.11|5.12] "rad"  ADCU
 SG_ Orientation_Obj_25 : 407|10@0+ (0.01,-5.11) [-5.11|5.12] "rad"  ADCU
 SG_ OrientationStd_Obj_24 : 471|4@0+ (0.002,0) [0|0.03] "rad"  ADCU
 SG_ OrientationStd_Obj_25 : 467|4@0+ (0.002,0) [0|0.03] "rad"  ADCU
 SG_ ProbOfExist_Obj_24 : 112|7@0+ (1,0) [0|127] "%"  ADCU
 SG_ ProbOfExist_Obj_25 : 344|7@0+ (1,0) [0|127] "%"  ADCU
 SG_ RCS_Obj_24 : 152|9@0+ (0.2,-51.1) [-51.1|51.1] "dBsm"  ADCU
 SG_ RCS_Obj_25 : 384|9@0+ (0.2,-51.1) [-51.1|51.1] "dBsm"  ADCU
 SG_ RefPoint_Obj_24 : 217|4@0+ (1,0) [0|15] ""  ADCU
 SG_ RefPoint_Obj_25 : 449|4@0+ (1,0) [0|15] ""  ADCU
 SG_ VabsX_Obj_24 : 11|11@0+ (0.125,-128) [-128|127.875] "m/s"  ADCU
 SG_ VabsX_Obj_25 : 243|11@0+ (0.125,-128) [-128|127.875] "m/s"  ADCU
 SG_ VabsXStd_Obj_24 : 87|7@0+ (0.1,0) [0|12.7] "m/s"  ADCU
 SG_ VabsXStd_Obj_25 : 319|7@0+ (0.1,0) [0|12.7] "m/s"  ADCU
 SG_ VabsY_Obj_24 : 43|11@0+ (0.125,-128) [-128|127.875] "m/s"  ADCU
 SG_ VabsY_Obj_25 : 275|11@0+ (0.125,-128) [-128|127.875] "m/s"  ADCU
 SG_ VabsYStd_Obj_24 : 80|7@0+ (0.2,0) [0|25.4] "m/s"  ADCU
 SG_ VabsYStd_Obj_25 : 312|7@0+ (0.2,0) [0|25.4] "m/s"  ADCU
 SG_ Valid_Obj_24 : 229|1@0+ (1,0) [0|1] ""  ADCU
 SG_ Valid_Obj_25 : 461|1@0+ (1,0) [0|1] ""  ADCU
 SG_ Width_Obj_24 : 159|7@0+ (0.2,0) [0|25.4] "m"  ADCU
 SG_ Width_Obj_25 : 391|7@0+ (0.2,0) [0|25.4] "m"  ADCU
 SG_ YawRateAbs_Obj_24 : 181|10@0+ (0.001,-0.511) [-0.511|0.512] "rad/s"  ADCU
 SG_ YawRateAbs_Obj_25 : 413|10@0+ (0.001,-0.511) [-0.511|0.512] "rad/s"  ADCU
 SG_ YawRateAbsStd_Obj_24 : 187|10@0+ (0.0001,0) [0|0.1023] "rad/s"  ADCU
 SG_ YawRateAbsStd_Obj_25 : 419|10@0+ (0.0001,0) [0|0.1023] "rad/s"  ADCU

BO_ 558 RR_Object_26_27: 64 LR
 SG_ AabsX_Obj_26 : 16|9@0+ (0.125,-31.875) [-31.875|32] "m/s^2"  ADCU
 SG_ AabsX_Obj_27 : 248|9@0+ (0.125,-31.875) [-31.875|32] "m/s^2"  ADCU
 SG_ AabsXStd_Obj_26 : 89|7@0+ (0.25,0) [0|31.75] "m/s^2"  ADCU
 SG_ AabsXStd_Obj_27 : 321|7@0+ (0.25,0) [0|31.75] "m/s^2"  ADCU
 SG_ AabsY_Obj_26 : 48|9@0+ (0.125,-31.875) [-31.875|32] "m/s^2"  ADCU
 SG_ AabsY_Obj_27 : 280|9@0+ (0.125,-31.875) [-31.875|32] "m/s^2"  ADCU
 SG_ AabsYStd_Obj_26 : 111|8@0+ (0.25,0) [0|63.75] "m/s^2"  ADCU
 SG_ AabsYStd_Obj_27 : 343|8@0+ (0.25,0) [0|63.75] "m/s^2"  ADCU
 SG_ ClassConf_Obj_26 : 119|7@0+ (1,0) [0|127] "%"  ADCU
 SG_ ClassConf_Obj_27 : 351|7@0+ (1,0) [0|127] "%"  ADCU
 SG_ Classification_Obj_26 : 98|3@0+ (1,0) [0|7] ""  ADCU
 SG_ Classification_Obj_27 : 330|3@0+ (1,0) [0|7] ""  ADCU
 SG_ CRC16_Checksum_Obj_26_27 : 503|16@0+ (1,0) [0|65535] ""  ADCU
 SG_ DistX_Obj_26 : 7|12@0+ (0.1,-200) [-200|209.5] "m"  ADCU
 SG_ DistX_Obj_27 : 239|12@0+ (0.1,-200) [-200|209.5] "m"  ADCU
 SG_ DistXStd_Obj_26 : 71|8@0+ (0.05,0) [0|12.75] "m"  ADCU
 SG_ DistXStd_Obj_27 : 303|8@0+ (0.05,0) [0|12.75] "m"  ADCU
 SG_ DistY_Obj_26 : 39|12@0+ (0.1,-200) [-200|209.5] "m"  ADCU
 SG_ DistY_Obj_27 : 271|12@0+ (0.1,-200) [-200|209.5] "m"  ADCU
 SG_ DistYStd_Obj_26 : 79|8@0+ (0.1,0) [0|25.5] "m"  ADCU
 SG_ DistYStd_Obj_27 : 311|8@0+ (0.1,0) [0|25.5] "m"  ADCU
 SG_ DynConf_Obj_26 : 121|7@0+ (1,0) [0|127] "%"  ADCU
 SG_ DynConf_Obj_27 : 353|7@0+ (1,0) [0|127] "%"  ADCU
 SG_ DynProp_Obj_26 : 130|3@0+ (1,0) [0|7] ""  ADCU
 SG_ DynProp_Obj_27 : 362|3@0+ (1,0) [0|7] ""  ADCU
 SG_ ID_Obj_26 : 209|8@0+ (1,0) [0|255] ""  ADCU
 SG_ ID_Obj_27 : 441|8@0+ (1,0) [0|255] ""  ADCU
 SG_ Length_Obj_26 : 136|7@0+ (0.2,0) [0|25.4] "m"  ADCU
 SG_ Length_Obj_27 : 368|7@0+ (0.2,0) [0|25.4] "m"  ADCU
 SG_ LifeCycle_Obj_26 : 193|16@0+ (1,0) [0|65535] ""  ADCU
 SG_ LifeCycle_Obj_27 : 425|16@0+ (1,0) [0|65535] ""  ADCU
 SG_ MaintenanceState_Obj_26 : 145|2@0+ (1,0) [0|3] ""  ADCU
 SG_ MaintenanceState_Obj_27 : 377|2@0+ (1,0) [0|3] ""  ADCU
 SG_ MicroDopplerFlag_26 : 472|1@0+ (1,0) [0|1] ""  ADCU
 SG_ MicroDopplerFlag_27 : 480|1@0+ (1,0) [0|1] ""  ADCU
 SG_ MirrorProb_Obj_26 : 143|7@0+ (1,0) [0|127] "%"  ADCU
 SG_ MirrorProb_Obj_27 : 375|7@0+ (1,0) [0|127] "%"  ADCU
 SG_ MsgCounter_Obj_26_27 : 495|8@0+ (1,0) [0|255] ""  ADCU
 SG_ ObstacleProb_Obj_26 : 479|7@0+ (1,0) [0|127] "%"  ADCU
 SG_ ObstacleProb_Obj_27 : 487|7@0+ (1,0) [0|127] "%"  ADCU
 SG_ Orientation_Obj_26 : 175|10@0+ (0.01,-5.11) [-5.11|5.12] "rad"  ADCU
 SG_ Orientation_Obj_27 : 407|10@0+ (0.01,-5.11) [-5.11|5.12] "rad"  ADCU
 SG_ OrientationStd_Obj_26 : 471|4@0+ (0.002,0) [0|0.03] "rad"  ADCU
 SG_ OrientationStd_Obj_27 : 467|4@0+ (0.002,0) [0|0.03] "rad"  ADCU
 SG_ ProbOfExist_Obj_26 : 112|7@0+ (1,0) [0|127] "%"  ADCU
 SG_ ProbOfExist_Obj_27 : 344|7@0+ (1,0) [0|127] "%"  ADCU
 SG_ RCS_Obj_26 : 152|9@0+ (0.2,-51.1) [-51.1|51.1] "dBsm"  ADCU
 SG_ RCS_Obj_27 : 384|9@0+ (0.2,-51.1) [-51.1|51.1] "dBsm"  ADCU
 SG_ RefPoint_Obj_26 : 217|4@0+ (1,0) [0|15] ""  ADCU
 SG_ RefPoint_Obj_27 : 449|4@0+ (1,0) [0|15] ""  ADCU
 SG_ VabsX_Obj_26 : 11|11@0+ (0.125,-128) [-128|127.875] "m/s"  ADCU
 SG_ VabsX_Obj_27 : 243|11@0+ (0.125,-128) [-128|127.875] "m/s"  ADCU
 SG_ VabsXStd_Obj_26 : 87|7@0+ (0.1,0) [0|12.7] "m/s"  ADCU
 SG_ VabsXStd_Obj_27 : 319|7@0+ (0.1,0) [0|12.7] "m/s"  ADCU
 SG_ VabsY_Obj_26 : 43|11@0+ (0.125,-128) [-128|127.875] "m/s"  ADCU
 SG_ VabsY_Obj_27 : 275|11@0+ (0.125,-128) [-128|127.875] "m/s"  ADCU
 SG_ VabsYStd_Obj_26 : 80|7@0+ (0.2,0) [0|25.4] "m/s"  ADCU
 SG_ VabsYStd_Obj_27 : 312|7@0+ (0.2,0) [0|25.4] "m/s"  ADCU
 SG_ Valid_Obj_26 : 229|1@0+ (1,0) [0|1] ""  ADCU
 SG_ Valid_Obj_27 : 461|1@0+ (1,0) [0|1] ""  ADCU
 SG_ Width_Obj_26 : 159|7@0+ (0.2,0) [0|25.4] "m"  ADCU
 SG_ Width_Obj_27 : 391|7@0+ (0.2,0) [0|25.4] "m"  ADCU
 SG_ YawRateAbs_Obj_26 : 181|10@0+ (0.001,-0.511) [-0.511|0.512] "rad/s"  ADCU
 SG_ YawRateAbs_Obj_27 : 413|10@0+ (0.001,-0.511) [-0.511|0.512] "rad/s"  ADCU
 SG_ YawRateAbsStd_Obj_26 : 187|10@0+ (0.0001,0) [0|0.1023] "rad/s"  ADCU
 SG_ YawRateAbsStd_Obj_27 : 419|10@0+ (0.0001,0) [0|0.1023] "rad/s"  ADCU

BO_ 559 RR_Object_28_29: 64 LR
 SG_ AabsX_Obj_28 : 16|9@0+ (0.125,-31.875) [-31.875|32] "m/s^2"  ADCU
 SG_ AabsX_Obj_29 : 248|9@0+ (0.125,-31.875) [-31.875|32] "m/s^2"  ADCU
 SG_ AabsXStd_Obj_28 : 89|7@0+ (0.25,0) [0|31.75] "m/s^2"  ADCU
 SG_ AabsXStd_Obj_29 : 321|7@0+ (0.25,0) [0|31.75] "m/s^2"  ADCU
 SG_ AabsY_Obj_28 : 48|9@0+ (0.125,-31.875) [-31.875|32] "m/s^2"  ADCU
 SG_ AabsY_Obj_29 : 280|9@0+ (0.125,-31.875) [-31.875|32] "m/s^2"  ADCU
 SG_ AabsYStd_Obj_28 : 111|8@0+ (0.25,0) [0|63.75] "m/s^2"  ADCU
 SG_ AabsYStd_Obj_29 : 343|8@0+ (0.25,0) [0|63.75] "m/s^2"  ADCU
 SG_ ClassConf_Obj_28 : 119|7@0+ (1,0) [0|127] "%"  ADCU
 SG_ ClassConf_Obj_29 : 351|7@0+ (1,0) [0|127] "%"  ADCU
 SG_ Classification_Obj_28 : 98|3@0+ (1,0) [0|7] ""  ADCU
 SG_ Classification_Obj_29 : 330|3@0+ (1,0) [0|7] ""  ADCU
 SG_ CRC16_Checksum_Obj_28_29 : 503|16@0+ (1,0) [0|65535] ""  ADCU
 SG_ DistX_Obj_28 : 7|12@0+ (0.1,-200) [-200|209.5] "m"  ADCU
 SG_ DistX_Obj_29 : 239|12@0+ (0.1,-200) [-200|209.5] "m"  ADCU
 SG_ DistXStd_Obj_28 : 71|8@0+ (0.05,0) [0|12.75] "m"  ADCU
 SG_ DistXStd_Obj_29 : 303|8@0+ (0.05,0) [0|12.75] "m"  ADCU
 SG_ DistY_Obj_28 : 39|12@0+ (0.1,-200) [-200|209.5] "m"  ADCU
 SG_ DistY_Obj_29 : 271|12@0+ (0.1,-200) [-200|209.5] "m"  ADCU
 SG_ DistYStd_Obj_28 : 79|8@0+ (0.1,0) [0|25.5] "m"  ADCU
 SG_ DistYStd_Obj_29 : 311|8@0+ (0.1,0) [0|25.5] "m"  ADCU
 SG_ DynConf_Obj_28 : 121|7@0+ (1,0) [0|127] "%"  ADCU
 SG_ DynConf_Obj_29 : 353|7@0+ (1,0) [0|127] "%"  ADCU
 SG_ DynProp_Obj_28 : 130|3@0+ (1,0) [0|7] ""  ADCU
 SG_ DynProp_Obj_29 : 362|3@0+ (1,0) [0|7] ""  ADCU
 SG_ ID_Obj_28 : 209|8@0+ (1,0) [0|255] ""  ADCU
 SG_ ID_Obj_29 : 441|8@0+ (1,0) [0|255] ""  ADCU
 SG_ Length_Obj_28 : 136|7@0+ (0.2,0) [0|25.4] "m"  ADCU
 SG_ Length_Obj_29 : 368|7@0+ (0.2,0) [0|25.4] "m"  ADCU
 SG_ LifeCycle_Obj_28 : 193|16@0+ (1,0) [0|65535] ""  ADCU
 SG_ LifeCycle_Obj_29 : 425|16@0+ (1,0) [0|65535] ""  ADCU
 SG_ MaintenanceState_Obj_28 : 145|2@0+ (1,0) [0|3] ""  ADCU
 SG_ MaintenanceState_Obj_29 : 377|2@0+ (1,0) [0|3] ""  ADCU
 SG_ MicroDopplerFlag_28 : 472|1@0+ (1,0) [0|1] ""  ADCU
 SG_ MicroDopplerFlag_29 : 480|1@0+ (1,0) [0|1] ""  ADCU
 SG_ MirrorProb_Obj_28 : 143|7@0+ (1,0) [0|127] "%"  ADCU
 SG_ MirrorProb_Obj_29 : 375|7@0+ (1,0) [0|127] "%"  ADCU
 SG_ MsgCounter_Obj_28_29 : 495|8@0+ (1,0) [0|255] ""  ADCU
 SG_ ObstacleProb_Obj_28 : 479|7@0+ (1,0) [0|127] "%"  ADCU
 SG_ ObstacleProb_Obj_29 : 487|7@0+ (1,0) [0|127] "%"  ADCU
 SG_ Orientation_Obj_28 : 175|10@0+ (0.01,-5.11) [-5.11|5.12] "rad"  ADCU
 SG_ Orientation_Obj_29 : 407|10@0+ (0.01,-5.11) [-5.11|5.12] "rad"  ADCU
 SG_ OrientationStd_Obj_28 : 471|4@0+ (0.002,0) [0|0.03] "rad"  ADCU
 SG_ OrientationStd_Obj_29 : 467|4@0+ (0.002,0) [0|0.03] "rad"  ADCU
 SG_ ProbOfExist_Obj_28 : 112|7@0+ (1,0) [0|127] "%"  ADCU
 SG_ ProbOfExist_Obj_29 : 344|7@0+ (1,0) [0|127] "%"  ADCU
 SG_ RCS_Obj_28 : 152|9@0+ (0.2,-51.1) [-51.1|51.1] "dBsm"  ADCU
 SG_ RCS_Obj_29 : 384|9@0+ (0.2,-51.1) [-51.1|51.1] "dBsm"  ADCU
 SG_ RefPoint_Obj_28 : 217|4@0+ (1,0) [0|15] ""  ADCU
 SG_ RefPoint_Obj_29 : 449|4@0+ (1,0) [0|15] ""  ADCU
 SG_ VabsX_Obj_28 : 11|11@0+ (0.125,-128) [-128|127.875] "m/s"  ADCU
 SG_ VabsX_Obj_29 : 243|11@0+ (0.125,-128) [-128|127.875] "m/s"  ADCU
 SG_ VabsXStd_Obj_28 : 87|7@0+ (0.1,0) [0|12.7] "m/s"  ADCU
 SG_ VabsXStd_Obj_29 : 319|7@0+ (0.1,0) [0|12.7] "m/s"  ADCU
 SG_ VabsY_Obj_28 : 43|11@0+ (0.125,-128) [-128|127.875] "m/s"  ADCU
 SG_ VabsY_Obj_29 : 275|11@0+ (0.125,-128) [-128|127.875] "m/s"  ADCU
 SG_ VabsYStd_Obj_28 : 80|7@0+ (0.2,0) [0|25.4] "m/s"  ADCU
 SG_ VabsYStd_Obj_29 : 312|7@0+ (0.2,0) [0|25.4] "m/s"  ADCU
 SG_ Valid_Obj_28 : 229|1@0+ (1,0) [0|1] ""  ADCU
 SG_ Valid_Obj_29 : 461|1@0+ (1,0) [0|1] ""  ADCU
 SG_ Width_Obj_28 : 159|7@0+ (0.2,0) [0|25.4] "m"  ADCU
 SG_ Width_Obj_29 : 391|7@0+ (0.2,0) [0|25.4] "m"  ADCU
 SG_ YawRateAbs_Obj_28 : 181|10@0+ (0.001,-0.511) [-0.511|0.512] "rad/s"  ADCU
 SG_ YawRateAbs_Obj_29 : 413|10@0+ (0.001,-0.511) [-0.511|0.512] "rad/s"  ADCU
 SG_ YawRateAbsStd_Obj_28 : 187|10@0+ (0.0001,0) [0|0.1023] "rad/s"  ADCU
 SG_ YawRateAbsStd_Obj_29 : 419|10@0+ (0.0001,0) [0|0.1023] "rad/s"  ADCU

BO_ 560 RR_Object_30_31: 64 LR
 SG_ AabsX_Obj_30 : 16|9@0+ (0.125,-31.875) [-31.875|32] "m/s^2"  ADCU
 SG_ AabsX_Obj_31 : 248|9@0+ (0.125,-31.875) [-31.875|32] "m/s^2"  ADCU
 SG_ AabsXStd_Obj_30 : 89|7@0+ (0.25,0) [0|31.75] "m/s^2"  ADCU
 SG_ AabsXStd_Obj_31 : 321|7@0+ (0.25,0) [0|31.75] "m/s^2"  ADCU
 SG_ AabsY_Obj_30 : 48|9@0+ (0.125,-31.875) [-31.875|32] "m/s^2"  ADCU
 SG_ AabsY_Obj_31 : 280|9@0+ (0.125,-31.875) [-31.875|32] "m/s^2"  ADCU
 SG_ AabsYStd_Obj_30 : 111|8@0+ (0.25,0) [0|63.75] "m/s^2"  ADCU
 SG_ AabsYStd_Obj_31 : 343|8@0+ (0.25,0) [0|63.75] "m/s^2"  ADCU
 SG_ ClassConf_Obj_30 : 119|7@0+ (1,0) [0|127] "%"  ADCU
 SG_ ClassConf_Obj_31 : 351|7@0+ (1,0) [0|127] "%"  ADCU
 SG_ Classification_Obj_30 : 98|3@0+ (1,0) [0|7] ""  ADCU
 SG_ Classification_Obj_31 : 330|3@0+ (1,0) [0|7] ""  ADCU
 SG_ CRC16_Checksum_Obj_30_31 : 503|16@0+ (1,0) [0|65535] ""  ADCU
 SG_ DistX_Obj_30 : 7|12@0+ (0.1,-200) [-200|209.5] "m"  ADCU
 SG_ DistX_Obj_31 : 239|12@0+ (0.1,-200) [-200|209.5] "m"  ADCU
 SG_ DistXStd_Obj_30 : 71|8@0+ (0.05,0) [0|12.75] "m"  ADCU
 SG_ DistXStd_Obj_31 : 303|8@0+ (0.05,0) [0|12.75] "m"  ADCU
 SG_ DistY_Obj_30 : 39|12@0+ (0.1,-200) [-200|209.5] "m"  ADCU
 SG_ DistY_Obj_31 : 271|12@0+ (0.1,-200) [-200|209.5] "m"  ADCU
 SG_ DistYStd_Obj_30 : 79|8@0+ (0.1,0) [0|25.5] "m"  ADCU
 SG_ DistYStd_Obj_31 : 311|8@0+ (0.1,0) [0|25.5] "m"  ADCU
 SG_ DynConf_Obj_30 : 121|7@0+ (1,0) [0|127] "%"  ADCU
 SG_ DynConf_Obj_31 : 353|7@0+ (1,0) [0|127] "%"  ADCU
 SG_ DynProp_Obj_30 : 130|3@0+ (1,0) [0|7] ""  ADCU
 SG_ DynProp_Obj_31 : 362|3@0+ (1,0) [0|7] ""  ADCU
 SG_ ID_Obj_30 : 209|8@0+ (1,0) [0|255] ""  ADCU
 SG_ ID_Obj_31 : 441|8@0+ (1,0) [0|255] ""  ADCU
 SG_ Length_Obj_30 : 136|7@0+ (0.2,0) [0|25.4] "m"  ADCU
 SG_ Length_Obj_31 : 368|7@0+ (0.2,0) [0|25.4] "m"  ADCU
 SG_ LifeCycle_Obj_30 : 193|16@0+ (1,0) [0|65535] ""  ADCU
 SG_ LifeCycle_Obj_31 : 425|16@0+ (1,0) [0|65535] ""  ADCU
 SG_ MaintenanceState_Obj_30 : 145|2@0+ (1,0) [0|3] ""  ADCU
 SG_ MaintenanceState_Obj_31 : 377|2@0+ (1,0) [0|3] ""  ADCU
 SG_ MicroDopplerFlag_30 : 472|1@0+ (1,0) [0|1] ""  ADCU
 SG_ MicroDopplerFlag_31 : 480|1@0+ (1,0) [0|1] ""  ADCU
 SG_ MirrorProb_Obj_30 : 143|7@0+ (1,0) [0|127] "%"  ADCU
 SG_ MirrorProb_Obj_31 : 375|7@0+ (1,0) [0|127] "%"  ADCU
 SG_ MsgCounter_Obj_30_31 : 495|8@0+ (1,0) [0|255] ""  ADCU
 SG_ ObstacleProb_Obj_30 : 479|7@0+ (1,0) [0|127] "%"  ADCU
 SG_ ObstacleProb_Obj_31 : 487|7@0+ (1,0) [0|127] "%"  ADCU
 SG_ Orientation_Obj_30 : 175|10@0+ (0.01,-5.11) [-5.11|5.12] "rad"  ADCU
 SG_ Orientation_Obj_31 : 407|10@0+ (0.01,-5.11) [-5.11|5.12] "rad"  ADCU
 SG_ OrientationStd_Obj_30 : 471|4@0+ (0.002,0) [0|0.03] "rad"  ADCU
 SG_ OrientationStd_Obj_31 : 467|4@0+ (0.002,0) [0|0.03] "rad"  ADCU
 SG_ ProbOfExist_Obj_30 : 112|7@0+ (1,0) [0|127] "%"  ADCU
 SG_ ProbOfExist_Obj_31 : 344|7@0+ (1,0) [0|127] "%"  ADCU
 SG_ RCS_Obj_30 : 152|9@0+ (0.2,-51.1) [-51.1|51.1] "dBsm"  ADCU
 SG_ RCS_Obj_31 : 384|9@0+ (0.2,-51.1) [-51.1|51.1] "dBsm"  ADCU
 SG_ RefPoint_Obj_30 : 217|4@0+ (1,0) [0|15] ""  ADCU
 SG_ RefPoint_Obj_31 : 449|4@0+ (1,0) [0|15] ""  ADCU
 SG_ VabsX_Obj_30 : 11|11@0+ (0.125,-128) [-128|127.875] "m/s"  ADCU
 SG_ VabsX_Obj_31 : 243|11@0+ (0.125,-128) [-128|127.875] "m/s"  ADCU
 SG_ VabsXStd_Obj_30 : 87|7@0+ (0.1,0) [0|12.7] "m/s"  ADCU
 SG_ VabsXStd_Obj_31 : 319|7@0+ (0.1,0) [0|12.7] "m/s"  ADCU
 SG_ VabsY_Obj_30 : 43|11@0+ (0.125,-128) [-128|127.875] "m/s"  ADCU
 SG_ VabsY_Obj_31 : 275|11@0+ (0.125,-128) [-128|127.875] "m/s"  ADCU
 SG_ VabsYStd_Obj_30 : 80|7@0+ (0.2,0) [0|25.4] "m/s"  ADCU
 SG_ VabsYStd_Obj_31 : 312|7@0+ (0.2,0) [0|25.4] "m/s"  ADCU
 SG_ Valid_Obj_30 : 229|1@0+ (1,0) [0|1] ""  ADCU
 SG_ Valid_Obj_31 : 461|1@0+ (1,0) [0|1] ""  ADCU
 SG_ Width_Obj_30 : 159|7@0+ (0.2,0) [0|25.4] "m"  ADCU
 SG_ Width_Obj_31 : 391|7@0+ (0.2,0) [0|25.4] "m"  ADCU
 SG_ YawRateAbs_Obj_30 : 181|10@0+ (0.001,-0.511) [-0.511|0.512] "rad/s"  ADCU
 SG_ YawRateAbs_Obj_31 : 413|10@0+ (0.001,-0.511) [-0.511|0.512] "rad/s"  ADCU
 SG_ YawRateAbsStd_Obj_30 : 187|10@0+ (0.0001,0) [0|0.1023] "rad/s"  ADCU
 SG_ YawRateAbsStd_Obj_31 : 419|10@0+ (0.0001,0) [0|0.1023] "rad/s"  ADCU

BO_ 573 System_Control_Cmd: 1 ADCU
 SG_ DPMode_Cmd : 1|2@0+ (1,0) [0|3] ""  LR,RR

BO_ 574 LR_Tester: 64 LR
 SG_ GW_EgoBrakePedal : 70|7@0+ (1,0) [0|127] ""  ADCU
 SG_ GW_EgoCurvature : 46|8@0+ (0.001,0) [0|0.255] "1/m"  ADCU
 SG_ GW_EgoDoorStateLF : 52|1@0+ (1,0) [0|1] ""  ADCU
 SG_ GW_EgoDoorStateLR : 50|1@0+ (1,0) [0|1] ""  ADCU
 SG_ GW_EgoDoorStateRF : 51|1@0+ (1,0) [0|1] ""  ADCU
 SG_ GW_EgoDoorStateRR : 49|1@0+ (1,0) [0|1] ""  ADCU
 SG_ GW_EgoDoorStateTrunk : 48|1@0+ (1,0) [0|1] ""  ADCU
 SG_ GW_EgoGasPedal : 61|7@0+ (1,0) [0|127] ""  ADCU
 SG_ GW_EgoGear : 63|2@0+ (1,0) [0|3] ""  ADCU
 SG_ GW_EgoLatAcceleration : 39|9@0+ (0.125,-31.875) [-31.875|32] "m/s^2"  ADCU
 SG_ GW_EgoLongAcceleration : 16|9@0+ (0.125,-31.875) [-31.875|32] "m/s^2"  ADCU
 SG_ GW_EgoSteeringDirection : 79|1@0+ (1,0) [0|1] ""  ADCU
 SG_ GW_EgoSteeringLamp : 54|2@0+ (1,0) [0|3] ""  ADCU
 SG_ GW_EgoVelocity : 7|11@0+ (0.125,-128) [-128|127.875] "m/s"  ADCU
 SG_ GW_EgoYawRate : 12|12@0+ (0.0625,-128) [-128|127.9375] "deg/s"  ADCU

BO_ 575 LR_ROAD: 32 LR
 SG_ ClothoidParam_1_Left : 7|12@0+ (0.001,-2.047) [-2.047|2.048] "rad"  ADCU
 SG_ ClothoidParam_1_Right : 135|12@0+ (0.001,-2.047) [-2.047|2.048] "rad"  ADCU
 SG_ ClothoidParam_2_Left : 11|10@0+ (0.0001,-0.0511) [-0.0511|0.0512] "1/m"  ADCU
 SG_ ClothoidParam_2_Right : 139|10@0+ (0.0001,-0.0511) [-0.0511|0.0512] "1/m"  ADCU
 SG_ ClothoidParam_3_Left : 31|11@0+ (1E-006,-0.001023) [-0.001023|0.001024] "1/m^2"  ADCU
 SG_ ClothoidParam_3_Right : 159|11@0+ (1E-006,-0.001023) [-0.001023|0.001024] "1/m^2"  ADCU
 SG_ Confidence_Left : 103|7@0+ (1,0) [0|127] "%"  ADCU
 SG_ Confidence_Right : 119|7@0+ (1,0) [0|127] "%"  ADCU
 SG_ CRC16_Checksum : 247|16@0+ (1,0) [0|65535] ""  ADCU
 SG_ LatOffset_Left : 87|8@0+ (0.1,0) [0|25.5] "m"  ADCU
 SG_ LatOffset_Right : 95|8@0+ (0.1,-25.5) [-25.5|0] "m"  ADCU
 SG_ MsgCounter : 239|8@0+ (1,0) [0|255] ""  ADCU
 SG_ NofLane_Left : 96|2@0+ (1,0) [0|3] ""  ADCU
 SG_ NofLane_Right : 112|2@0+ (1,0) [0|3] ""  ADCU
 SG_ NofLaneProb_Left : 110|7@0+ (1,0) [0|127] "%"  ADCU
 SG_ NofLaneProb_Right : 126|7@0+ (1,0) [0|127] "%"  ADCU
 SG_ RoadType : 17|2@0+ (1,0) [0|3] ""  ADCU
 SG_ RoadTypeConf : 36|7@0+ (1,0) [0|127] "%"  ADCU
 SG_ Xend_Left : 59|9@0+ (0.5,0) [0|255.5] "m"  ADCU
 SG_ Xend_Right : 66|9@0+ (0.5,0) [0|255.5] "m"  ADCU
 SG_ Xstart_Left : 45|9@0+ (0.5,0) [0|255.5] "m"  ADCU
 SG_ Xstart_Right : 52|9@0+ (0.5,0) [0|255.5] "m"  ADCU

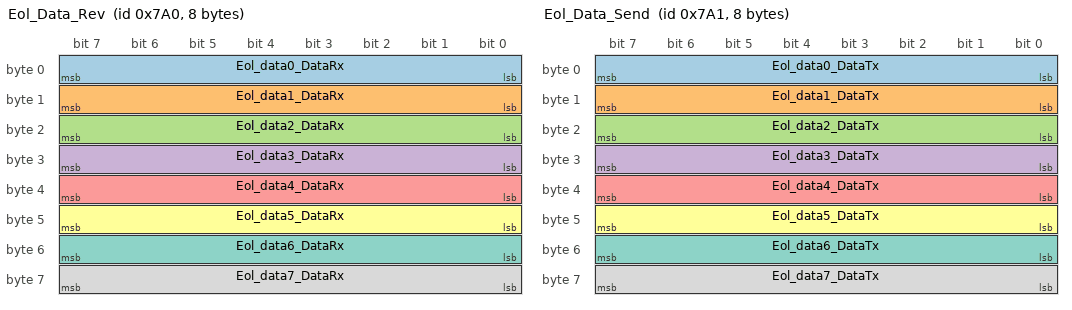
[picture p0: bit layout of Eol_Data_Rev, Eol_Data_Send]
BO_ 1952 Eol_Data_Rev: 8 ADCU
 SG_ Eol_data0_DataRx : 7|8@0- (1,0) [0|0] ""  LR
 SG_ Eol_data1_DataRx : 15|8@0- (1,0) [0|0] ""  LR
 SG_ Eol_data2_DataRx : 23|8@0- (1,0) [0|0] ""  LR
 SG_ Eol_data3_DataRx : 31|8@0- (1,0) [0|0] ""  LR
 SG_ Eol_data4_DataRx : 39|8@0- (1,0) [0|0] ""  LR
 SG_ Eol_data5_DataRx : 47|8@0- (1,0) [0|0] ""  LR
 SG_ Eol_data6_DataRx : 55|8@0- (1,0) [0|0] ""  LR
 SG_ Eol_data7_DataRx : 63|8@0- (1,0) [0|0] ""  LR

BO_ 1953 Eol_Data_Send: 8 LR
 SG_ Eol_data0_DataTx : 7|8@0- (1,0) [0|0] ""  ADCU
 SG_ Eol_data1_DataTx : 15|8@0- (1,0) [0|0] ""  ADCU
 SG_ Eol_data2_DataTx : 23|8@0- (1,0) [0|0] ""  ADCU
 SG_ Eol_data3_DataTx : 31|8@0- (1,0) [0|0] ""  ADCU
 SG_ Eol_data4_DataTx : 39|8@0- (1,0) [0|0] ""  ADCU
 SG_ Eol_data5_DataTx : 47|8@0- (1,0) [0|0] ""  ADCU
 SG_ Eol_data6_DataTx : 55|8@0- (1,0) [0|0] ""  ADCU
 SG_ Eol_data7_DataTx : 63|8@0- (1,0) [0|0] ""  ADCU

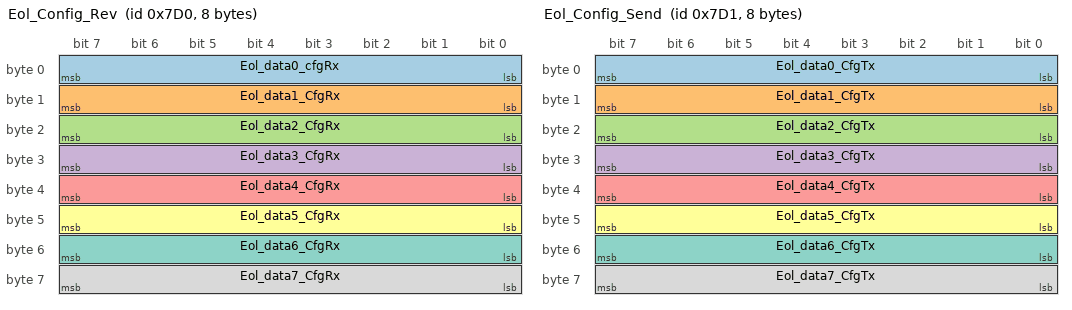
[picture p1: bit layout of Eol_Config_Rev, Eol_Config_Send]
BO_ 2000 Eol_Config_Rev: 8 ADCU
 SG_ Eol_data0_cfgRx : 7|8@0- (1,0) [0|0] ""  LR
 SG_ Eol_data1_CfgRx : 15|8@0- (1,0) [0|0] ""  LR
 SG_ Eol_data2_CfgRx : 23|8@0- (1,0) [0|0] ""  LR
 SG_ Eol_data3_CfgRx : 31|8@0- (1,0) [0|0] ""  LR
 SG_ Eol_data4_CfgRx : 39|8@0- (1,0) [0|0] ""  LR
 SG_ Eol_data5_CfgRx : 47|8@0- (1,0) [0|0] ""  LR
 SG_ Eol_data6_CfgRx : 55|8@0- (1,0) [0|0] ""  LR
 SG_ Eol_data7_CfgRx : 63|8@0- (1,0) [0|0] ""  LR

BO_ 2001 Eol_Config_Send: 8 LR
 SG_ Eol_data0_CfgTx : 7|8@0- (1,0) [0|0] ""  ADCU
 SG_ Eol_data1_CfgTx : 15|8@0- (1,0) [0|0] ""  ADCU
 SG_ Eol_data2_CfgTx : 23|8@0- (1,0) [0|0] ""  ADCU
 SG_ Eol_data3_CfgTx : 31|8@0- (1,0) [0|0] ""  ADCU
 SG_ Eol_data4_CfgTx : 39|8@0- (1,0) [0|0] ""  ADCU
 SG_ Eol_data5_CfgTx : 47|8@0- (1,0) [0|0] ""  ADCU
 SG_ Eol_data6_CfgTx : 55|8@0- (1,0) [0|0] ""  ADCU
 SG_ Eol_data7_CfgTx : 63|8@0- (1,0) [0|0] ""  ADCU

BO_TX_BU_ 544 : RR,LR;
BO_TX_BU_ 545 : RR,LR;
BO_TX_BU_ 546 : RR,LR;
BO_TX_BU_ 547 : RR,LR;
BO_TX_BU_ 548 : RR,LR;
BO_TX_BU_ 549 : RR,LR;
BO_TX_BU_ 550 : RR,LR;
BO_TX_BU_ 551 : RR,LR;
BO_TX_BU_ 552 : RR,LR;
BO_TX_BU_ 553 : RR,LR;
BO_TX_BU_ 554 : RR,LR;
BO_TX_BU_ 555 : RR,LR;
BO_TX_BU_ 556 : RR,LR;
BO_TX_BU_ 557 : RR,LR;
BO_TX_BU_ 558 : RR,LR;
BO_TX_BU_ 559 : RR,LR;
BO_TX_BU_ 560 : RR,LR;
CM_ SG_ 521 AabsX_Obj_16 "Longitudinal absolution acceleration over ground of object_16";
CM_ SG_ 521 AabsX_Obj_17 "Longitudinal absolution acceleration over ground of object_17";
CM_ SG_ 521 AabsXStd_Obj_16 "Longitudinal absolution acceleration standard deviation of object_16";
CM_ SG_ 521 AabsXStd_Obj_17 "Longitudinal absolution acceleration standard deviation of object_17";
CM_ SG_ 521 AabsY_Obj_16 "Lateral absolution acceleration over ground of object_16";
CM_ SG_ 521 AabsY_Obj_17 "Lateral absolution acceleration over ground of object_17";
CM_ SG_ 521 AabsYStd_Obj_16 "Lateral absolution acceleration standard deviation of object_16";
CM_ SG_ 521 AabsYStd_Obj_17 "Lateral absolution acceleration standard deviation of object_17";
CM_ SG_ 521 ClassConf_Obj_16 "Classification confidence of object_16";
CM_ SG_ 521 ClassConf_Obj_17 "Classification confidence of object_17";
CM_ SG_ 521 Classification_Obj_16 "Classification of object_16";
CM_ SG_ 521 Classification_Obj_17 "Classification of object_17";
CM_ SG_ 521 DistX_Obj_16 "Longitudinal distance of object_16";
CM_ SG_ 521 DistX_Obj_17 "Longitudinal distance of object_17";
CM_ SG_ 521 DistXStd_Obj_16 "Longitudinal distance standard deviation of object_16";
CM_ SG_ 521 DistXStd_Obj_17 "Longitudinal distance standard deviation of object_17";
CM_ SG_ 521 DistY_Obj_16 "Lateral distance of object_16";
CM_ SG_ 521 DistY_Obj_17 "Lateral distance of object_17";
CM_ SG_ 521 DistYStd_Obj_16 "Lateral distance standard deviation of object_16";
CM_ SG_ 521 DistYStd_Obj_17 "Lateral distance standard deviation of object_17";
CM_ SG_ 521 DynConf_Obj_16 "Dynamic property confidence of object_16";
CM_ SG_ 521 DynConf_Obj_17 "Dynamic property confidence of object_17";
CM_ SG_ 521 DynProp_Obj_16 "Dynamic property of object_16";
CM_ SG_ 521 DynProp_Obj_17 "Dynamic property of object_17";
CM_ SG_ 521 ID_Obj_16 "ID of object_16";
CM_ SG_ 521 ID_Obj_17 "ID of object_17";
CM_ SG_ 521 Length_Obj_16 "Length of object_16";
CM_ SG_ 521 Length_Obj_17 "Length of object_17";
CM_ SG_ 521 LifeCycle_Obj_16 "Life cycle of object_16";
CM_ SG_ 521 LifeCycle_Obj_17 "Life cycle of object_17";
CM_ SG_ 521 MaintenanceState_Obj_16 "Maintenance state of object_16";
CM_ SG_ 521 MaintenanceState_Obj_17 "Maintenance state of object_17";
CM_ SG_ 521 MicroDopplerFlag_16 "Micro-Doppler flag of object_16";
CM_ SG_ 521 MicroDopplerFlag_17 "Micro-Doppler flag of object_17";
CM_ SG_ 521 MirrorProb_Obj_16 "Mirror probability of object_16";
CM_ SG_ 521 MirrorProb_Obj_17 "Mirror probability of object_17";
CM_ SG_ 521 ObstacleProb_Obj_16 "Obstacle probability of object_16";
CM_ SG_ 521 ObstacleProb_Obj_17 "Obstacle probability of object_17";
CM_ SG_ 521 Orientation_Obj_16 "Orientation of object_16";
CM_ SG_ 521 Orientation_Obj_17 "Orientation of object_17";
CM_ SG_ 521 OrientationStd_Obj_16 "Orientation standard deviation of object_16";
CM_ SG_ 521 OrientationStd_Obj_17 "Orientation standard deviation of object_17";
CM_ SG_ 521 ProbOfExist_Obj_16 "Existence probability of object_16";
CM_ SG_ 521 ProbOfExist_Obj_17 "Existence probability of object_17";
CM_ SG_ 521 RCS_Obj_16 "RCS of object_16";
CM_ SG_ 521 RCS_Obj_17 "RCS of object_17";
CM_ SG_ 521 RefPoint_Obj_16 "Reference point of object_16";
CM_ SG_ 521 RefPoint_Obj_17 "Reference point of object_17";
CM_ SG_ 521 VabsX_Obj_16 "Longitudinal absolution velocity over ground of object_16";
CM_ SG_ 521 VabsX_Obj_17 "Longitudinal absolution velocity over ground of object_17";
CM_ SG_ 521 VabsXStd_Obj_16 "Longitudinal absolution velocity standard deviation of object_16";
CM_ SG_ 521 VabsXStd_Obj_17 "Longitudinal absolution velocity standard deviation of object_17";
CM_ SG_ 521 VabsY_Obj_16 "Lateral absolution velocity over ground of object_16";
CM_ SG_ 521 VabsY_Obj_17 "Lateral absolution velocity over ground of object_17";
CM_ SG_ 521 VabsYStd_Obj_16 "Lateral absolution velocity standard deviation of object_16";
CM_ SG_ 521 VabsYStd_Obj_17 "Lateral absolution velocity standard deviation of object_17";
CM_ SG_ 521 Valid_Obj_16 "Valid flag of object_16";
CM_ SG_ 521 Valid_Obj_17 "Valid flag of object_17";
CM_ SG_ 521 Width_Obj_16 "Width of object_16";
CM_ SG_ 521 Width_Obj_17 "Width of object_17";
CM_ SG_ 521 YawRateAbs_Obj_16 "Yaw rate of object_16";
CM_ SG_ 521 YawRateAbs_Obj_17 "Yaw rate of object_17";
CM_ SG_ 521 YawRateAbsStd_Obj_16 "Yaw rate standard deviation of object_16";
CM_ SG_ 521 YawRateAbsStd_Obj_17 "Yaw rate standard deviation of object_17";
CM_ SG_ 522 AabsX_Obj_18 "Longitudinal absolution acceleration over ground of object_18";
CM_ SG_ 522 AabsX_Obj_19 "Longitudinal absolution acceleration over ground of object_19";
CM_ SG_ 522 AabsXStd_Obj_18 "Longitudinal absolution acceleration standard deviation of object_18";
CM_ SG_ 522 AabsXStd_Obj_19 "Longitudinal absolution acceleration standard deviation of object_19";
CM_ SG_ 522 AabsY_Obj_18 "Lateral absolution acceleration over ground of object_18";
CM_ SG_ 522 AabsY_Obj_19 "Lateral absolution acceleration over ground of object_19";
CM_ SG_ 522 AabsYStd_Obj_18 "Lateral absolution acceleration standard deviation of object_18";
CM_ SG_ 522 AabsYStd_Obj_19 "Lateral absolution acceleration standard deviation of object_19";
CM_ SG_ 522 ClassConf_Obj_18 "Classification confidence of object_18";
CM_ SG_ 522 ClassConf_Obj_19 "Classification confidence of object_19";
CM_ SG_ 522 Classification_Obj_18 "Classification of object_18";
CM_ SG_ 522 Classification_Obj_19 "Classification of object_19";
CM_ SG_ 522 DistX_Obj_18 "Longitudinal distance of object_18";
CM_ SG_ 522 DistX_Obj_19 "Longitudinal distance of object_19";
CM_ SG_ 522 DistXStd_Obj_18 "Longitudinal distance standard deviation of object_18";
CM_ SG_ 522 DistXStd_Obj_19 "Longitudinal distance standard deviation of object_19";
CM_ SG_ 522 DistY_Obj_18 "Lateral distance of object_18";
CM_ SG_ 522 DistY_Obj_19 "Lateral distance of object_19";
CM_ SG_ 522 DistYStd_Obj_18 "Lateral distance standard deviation of object_18";
CM_ SG_ 522 DistYStd_Obj_19 "Lateral distance standard deviation of object_19";
CM_ SG_ 522 DynConf_Obj_18 "Dynamic property confidence of object_18";
CM_ SG_ 522 DynConf_Obj_19 "Dynamic property confidence of object_19";
CM_ SG_ 522 DynProp_Obj_18 "Dynamic property of object_18";
CM_ SG_ 522 DynProp_Obj_19 "Dynamic property of object_19";
CM_ SG_ 522 ID_Obj_18 "ID of object_18";
CM_ SG_ 522 ID_Obj_19 "ID of object_19";
CM_ SG_ 522 Length_Obj_18 "Length of object_18";
CM_ SG_ 522 Length_Obj_19 "Length of object_19";
CM_ SG_ 522 LifeCycle_Obj_18 "Life cycle of object_18";
CM_ SG_ 522 LifeCycle_Obj_19 "Life cycle of object_19";
CM_ SG_ 522 MaintenanceState_Obj_18 "Maintenance state of object_18";
CM_ SG_ 522 MaintenanceState_Obj_19 "Maintenance state of object_19";
CM_ SG_ 522 MicroDopplerFlag_18 "Micro-Doppler flag of object_18";
CM_ SG_ 522 MicroDopplerFlag_19 "Micro-Doppler flag of object_19";
CM_ SG_ 522 MirrorProb_Obj_18 "Mirror probability of object_18";
CM_ SG_ 522 MirrorProb_Obj_19 "Mirror probability of object_19";
CM_ SG_ 522 ObstacleProb_Obj_18 "Obstacle probability of object_18";
CM_ SG_ 522 ObstacleProb_Obj_19 "Obstacle probability of object_19";
CM_ SG_ 522 Orientation_Obj_18 "Orientation of object_18";
CM_ SG_ 522 Orientation_Obj_19 "Orientation of object_19";
CM_ SG_ 522 OrientationStd_Obj_18 "Orientation standard deviation of object_18";
CM_ SG_ 522 OrientationStd_Obj_19 "Orientation standard deviation of object_19";
CM_ SG_ 522 ProbOfExist_Obj_18 "Existence probability of object_18";
CM_ SG_ 522 ProbOfExist_Obj_19 "Existence probability of object_19";
CM_ SG_ 522 RCS_Obj_18 "RCS of object_18";
CM_ SG_ 522 RCS_Obj_19 "RCS of object_19";
CM_ SG_ 522 RefPoint_Obj_18 "Reference point of object_18";
CM_ SG_ 522 RefPoint_Obj_19 "Reference point of object_19";
CM_ SG_ 522 VabsX_Obj_18 "Longitudinal absolution velocity over ground of object_18";
CM_ SG_ 522 VabsX_Obj_19 "Longitudinal absolution velocity over ground of object_19";
CM_ SG_ 522 VabsXStd_Obj_18 "Longitudinal absolution velocity standard deviation of object_18";
CM_ SG_ 522 VabsXStd_Obj_19 "Longitudinal absolution velocity standard deviation of object_19";
CM_ SG_ 522 VabsY_Obj_18 "Lateral absolution velocity over ground of object_18";
CM_ SG_ 522 VabsY_Obj_19 "Lateral absolution velocity over ground of object_19";
CM_ SG_ 522 VabsYStd_Obj_18 "Lateral absolution velocity standard deviation of object_18";
CM_ SG_ 522 VabsYStd_Obj_19 "Lateral absolution velocity standard deviation of object_19";
CM_ SG_ 522 Valid_Obj_18 "Valid flag of object_18";
CM_ SG_ 522 Valid_Obj_19 "Valid flag of object_19";
CM_ SG_ 522 Width_Obj_18 "Width of object_18";
CM_ SG_ 522 Width_Obj_19 "Width of object_19";
CM_ SG_ 522 YawRateAbs_Obj_18 "Yaw rate of object_18";
CM_ SG_ 522 YawRateAbs_Obj_19 "Yaw rate of object_19";
CM_ SG_ 522 YawRateAbsStd_Obj_18 "Yaw rate standard deviation of object_18";
CM_ SG_ 522 YawRateAbsStd_Obj_19 "Yaw rate standard deviation of object_19";
CM_ SG_ 523 AabsX_Obj_20 "Longitudinal absolution acceleration over ground of object_20";
CM_ SG_ 523 AabsX_Obj_21 "Longitudinal absolution acceleration over ground of object_21";
CM_ SG_ 523 AabsXStd_Obj_20 "Longitudinal absolution acceleration standard deviation of object_20";
CM_ SG_ 523 AabsXStd_Obj_21 "Longitudinal absolution acceleration standard deviation of object_21";
CM_ SG_ 523 AabsY_Obj_20 "Lateral absolution acceleration over ground of object_20";
CM_ SG_ 523 AabsY_Obj_21 "Lateral absolution acceleration over ground of object_21";
CM_ SG_ 523 AabsYStd_Obj_20 "Lateral absolution acceleration standard deviation of object_20";
CM_ SG_ 523 AabsYStd_Obj_21 "Lateral absolution acceleration standard deviation of object_21";
CM_ SG_ 523 ClassConf_Obj_20 "Classification confidence of object_20";
CM_ SG_ 523 ClassConf_Obj_21 "Classification confidence of object_21";
CM_ SG_ 523 Classification_Obj_20 "Classification of object_20";
CM_ SG_ 523 Classification_Obj_21 "Classification of object_21";
CM_ SG_ 523 DistX_Obj_20 "Longitudinal distance of object_20";
CM_ SG_ 523 DistX_Obj_21 "Longitudinal distance of object_21";
CM_ SG_ 523 DistXStd_Obj_20 "Longitudinal distance standard deviation of object_20";
CM_ SG_ 523 DistXStd_Obj_21 "Longitudinal distance standard deviation of object_21";
CM_ SG_ 523 DistY_Obj_20 "Lateral distance of object_20";
CM_ SG_ 523 DistY_Obj_21 "Lateral distance of object_21";
CM_ SG_ 523 DistYStd_Obj_20 "Lateral distance standard deviation of object_20";
CM_ SG_ 523 DistYStd_Obj_21 "Lateral distance standard deviation of object_21";
CM_ SG_ 523 DynConf_Obj_20 "Dynamic property confidence of object_20";
CM_ SG_ 523 DynConf_Obj_21 "Dynamic property confidence of object_21";
CM_ SG_ 523 DynProp_Obj_20 "Dynamic property of object_20";
CM_ SG_ 523 DynProp_Obj_21 "Dynamic property of object_21";
CM_ SG_ 523 ID_Obj_20 "ID of object_20";
CM_ SG_ 523 ID_Obj_21 "ID of object_21";
CM_ SG_ 523 Length_Obj_20 "Length of object_20";
CM_ SG_ 523 Length_Obj_21 "Length of object_21";
CM_ SG_ 523 LifeCycle_Obj_20 "Life cycle of object_20";
CM_ SG_ 523 LifeCycle_Obj_21 "Life cycle of object_21";
CM_ SG_ 523 MaintenanceState_Obj_20 "Maintenance state of object_20";
CM_ SG_ 523 MaintenanceState_Obj_21 "Maintenance state of object_21";
CM_ SG_ 523 MicroDopplerFlag_20 "Micro-Doppler flag of object_20";
CM_ SG_ 523 MicroDopplerFlag_21 "Micro-Doppler flag of object_21";
CM_ SG_ 523 MirrorProb_Obj_20 "Mirror probability of object_20";
CM_ SG_ 523 MirrorProb_Obj_21 "Mirror probability of object_21";
CM_ SG_ 523 ObstacleProb_Obj_20 "Obstacle probability of object_20";
CM_ SG_ 523 ObstacleProb_Obj_21 "Obstacle probability of object_21";
CM_ SG_ 523 Orientation_Obj_20 "Orientation of object_20";
CM_ SG_ 523 Orientation_Obj_21 "Orientation of object_21";
CM_ SG_ 523 OrientationStd_Obj_20 "Orientation standard deviation of object_20";
CM_ SG_ 523 OrientationStd_Obj_21 "Orientation standard deviation of object_21";
CM_ SG_ 523 ProbOfExist_Obj_20 "Existence probability of object_20";
CM_ SG_ 523 ProbOfExist_Obj_21 "Existence probability of object_21";
CM_ SG_ 523 RCS_Obj_20 "RCS of object_20";
CM_ SG_ 523 RCS_Obj_21 "RCS of object_21";
CM_ SG_ 523 RefPoint_Obj_20 "Reference point of object_20";
CM_ SG_ 523 RefPoint_Obj_21 "Reference point of object_21";
CM_ SG_ 523 VabsX_Obj_20 "Longitudinal absolution velocity over ground of object_20";
CM_ SG_ 523 VabsX_Obj_21 "Longitudinal absolution velocity over ground of object_21";
CM_ SG_ 523 VabsXStd_Obj_20 "Longitudinal absolution velocity standard deviation of object_20";
CM_ SG_ 523 VabsXStd_Obj_21 "Longitudinal absolution velocity standard deviation of object_21";
CM_ SG_ 523 VabsY_Obj_20 "Lateral absolution velocity over ground of object_20";
CM_ SG_ 523 VabsY_Obj_21 "Lateral absolution velocity over ground of object_21";
CM_ SG_ 523 VabsYStd_Obj_20 "Lateral absolution velocity standard deviation of object_20";
CM_ SG_ 523 VabsYStd_Obj_21 "Lateral absolution velocity standard deviation of object_21";
CM_ SG_ 523 Valid_Obj_20 "Valid flag of object_20";
CM_ SG_ 523 Valid_Obj_21 "Valid flag of object_21";
CM_ SG_ 523 Width_Obj_20 "Width of object_20";
CM_ SG_ 523 Width_Obj_21 "Width of object_21";
CM_ SG_ 523 YawRateAbs_Obj_20 "Yaw rate of object_20";
CM_ SG_ 523 YawRateAbs_Obj_21 "Yaw rate of object_21";
CM_ SG_ 523 YawRateAbsStd_Obj_20 "Yaw rate standard deviation of object_20";
CM_ SG_ 523 YawRateAbsStd_Obj_21 "Yaw rate standard deviation of object_21";
CM_ SG_ 524 AabsX_Obj_22 "Longitudinal absolution acceleration over ground of object_22";
CM_ SG_ 524 AabsX_Obj_23 "Longitudinal absolution acceleration over ground of object_23";
CM_ SG_ 524 AabsXStd_Obj_22 "Longitudinal absolution acceleration standard deviation of object_22";
CM_ SG_ 524 AabsXStd_Obj_23 "Longitudinal absolution acceleration standard deviation of object_23";
CM_ SG_ 524 AabsY_Obj_22 "Lateral absolution acceleration over ground of object_22";
CM_ SG_ 524 AabsY_Obj_23 "Lateral absolution acceleration over ground of object_23";
CM_ SG_ 524 AabsYStd_Obj_22 "Lateral absolution acceleration standard deviation of object_22";
CM_ SG_ 524 AabsYStd_Obj_23 "Lateral absolution acceleration standard deviation of object_23";
CM_ SG_ 524 ClassConf_Obj_22 "Classification confidence of object_22";
CM_ SG_ 524 ClassConf_Obj_23 "Classification confidence of object_23";
CM_ SG_ 524 Classification_Obj_22 "Classification of object_22";
CM_ SG_ 524 Classification_Obj_23 "Classification of object_23";
CM_ SG_ 524 DistX_Obj_22 "Longitudinal distance of object_22";
CM_ SG_ 524 DistX_Obj_23 "Longitudinal distance of object_23";
CM_ SG_ 524 DistXStd_Obj_22 "Longitudinal distance standard deviation of object_22";
CM_ SG_ 524 DistXStd_Obj_23 "Longitudinal distance standard deviation of object_23";
CM_ SG_ 524 DistY_Obj_22 "Lateral distance of object_22";
CM_ SG_ 524 DistY_Obj_23 "Lateral distance of object_23";
CM_ SG_ 524 DistYStd_Obj_22 "Lateral distance standard deviation of object_22";
CM_ SG_ 524 DistYStd_Obj_23 "Lateral distance standard deviation of object_23";
CM_ SG_ 524 DynConf_Obj_22 "Dynamic property confidence of object_22";
CM_ SG_ 524 DynConf_Obj_23 "Dynamic property confidence of object_23";
CM_ SG_ 524 DynProp_Obj_22 "Dynamic property of object_22";
CM_ SG_ 524 DynProp_Obj_23 "Dynamic property of object_23";
CM_ SG_ 524 ID_Obj_22 "ID of object_22";
CM_ SG_ 524 ID_Obj_23 "ID of object_23";
CM_ SG_ 524 Length_Obj_22 "Length of object_22";
CM_ SG_ 524 Length_Obj_23 "Length of object_23";
CM_ SG_ 524 LifeCycle_Obj_22 "Life cycle of object_22";
CM_ SG_ 524 LifeCycle_Obj_23 "Life cycle of object_23";
CM_ SG_ 524 MaintenanceState_Obj_22 "Maintenance state of object_22";
CM_ SG_ 524 MaintenanceState_Obj_23 "Maintenance state of object_23";
CM_ SG_ 524 MicroDopplerFlag_22 "Micro-Doppler flag of object_22";
CM_ SG_ 524 MicroDopplerFlag_23 "Micro-Doppler flag of object_23";
CM_ SG_ 524 MirrorProb_Obj_22 "Mirror probability of object_22";
CM_ SG_ 524 MirrorProb_Obj_23 "Mirror probability of object_23";
CM_ SG_ 524 ObstacleProb_Obj_22 "Obstacle probability of object_22";
CM_ SG_ 524 ObstacleProb_Obj_23 "Obstacle probability of object_23";
CM_ SG_ 524 Orientation_Obj_22 "Orientation of object_22";
CM_ SG_ 524 Orientation_Obj_23 "Orientation of object_23";
CM_ SG_ 524 OrientationStd_Obj_22 "Orientation standard deviation of object_22";
CM_ SG_ 524 OrientationStd_Obj_23 "Orientation standard deviation of object_23";
CM_ SG_ 524 ProbOfExist_Obj_22 "Existence probability of object_22";
CM_ SG_ 524 ProbOfExist_Obj_23 "Existence probability of object_23";
CM_ SG_ 524 RCS_Obj_22 "RCS of object_22";
CM_ SG_ 524 RCS_Obj_23 "RCS of object_23";
CM_ SG_ 524 RefPoint_Obj_22 "Reference point of object_22";
CM_ SG_ 524 RefPoint_Obj_23 "Reference point of object_23";
CM_ SG_ 524 VabsX_Obj_22 "Longitudinal absolution velocity over ground of object_22";
CM_ SG_ 524 VabsX_Obj_23 "Longitudinal absolution velocity over ground of object_23";
CM_ SG_ 524 VabsXStd_Obj_22 "Longitudinal absolution velocity standard deviation of object_22";
CM_ SG_ 524 VabsXStd_Obj_23 "Longitudinal absolution velocity standard deviation of object_23";
CM_ SG_ 524 VabsY_Obj_22 "Lateral absolution velocity over ground of object_22";
CM_ SG_ 524 VabsY_Obj_23 "Lateral absolution velocity over ground of object_23";
CM_ SG_ 524 VabsYStd_Obj_22 "Lateral absolution velocity standard deviation of object_22";
CM_ SG_ 524 VabsYStd_Obj_23 "Lateral absolution velocity standard deviation of object_23";
CM_ SG_ 524 Valid_Obj_22 "Valid flag of object_22";
CM_ SG_ 524 Valid_Obj_23 "Valid flag of object_23";
CM_ SG_ 524 Width_Obj_22 "Width of object_22";
CM_ SG_ 524 Width_Obj_23 "Width of object_23";
CM_ SG_ 524 YawRateAbs_Obj_22 "Yaw rate of object_22";
CM_ SG_ 524 YawRateAbs_Obj_23 "Yaw rate of object_23";
CM_ SG_ 524 YawRateAbsStd_Obj_22 "Yaw rate standard deviation of object_22";
CM_ SG_ 524 YawRateAbsStd_Obj_23 "Yaw rate standard deviation of object_23";
CM_ SG_ 525 AabsX_Obj_24 "Longitudinal absolution acceleration over ground of object_24";
CM_ SG_ 525 AabsX_Obj_25 "Longitudinal absolution acceleration over ground of object_25";
CM_ SG_ 525 AabsXStd_Obj_24 "Longitudinal absolution acceleration standard deviation of object_24";
CM_ SG_ 525 AabsXStd_Obj_25 "Longitudinal absolution acceleration standard deviation of object_25";
CM_ SG_ 525 AabsY_Obj_24 "Lateral absolution acceleration over ground of object_24";
CM_ SG_ 525 AabsY_Obj_25 "Lateral absolution acceleration over ground of object_25";
CM_ SG_ 525 AabsYStd_Obj_24 "Lateral absolution acceleration standard deviation of object_24";
CM_ SG_ 525 AabsYStd_Obj_25 "Lateral absolution acceleration standard deviation of object_25";
CM_ SG_ 525 ClassConf_Obj_24 "Classification confidence of object_24";
CM_ SG_ 525 ClassConf_Obj_25 "Classification confidence of object_25";
CM_ SG_ 525 Classification_Obj_24 "Classification of object_24";
CM_ SG_ 525 Classification_Obj_25 "Classification of object_25";
CM_ SG_ 525 DistX_Obj_24 "Longitudinal distance of object_24";
CM_ SG_ 525 DistX_Obj_25 "Longitudinal distance of object_25";
CM_ SG_ 525 DistXStd_Obj_24 "Longitudinal distance standard deviation of object_24";
CM_ SG_ 525 DistXStd_Obj_25 "Longitudinal distance standard deviation of object_25";
CM_ SG_ 525 DistY_Obj_24 "Lateral distance of object_24";
CM_ SG_ 525 DistY_Obj_25 "Lateral distance of object_25";
CM_ SG_ 525 DistYStd_Obj_24 "Lateral distance standard deviation of object_24";
CM_ SG_ 525 DistYStd_Obj_25 "Lateral distance standard deviation of object_25";
CM_ SG_ 525 DynConf_Obj_24 "Dynamic property confidence of object_24";
CM_ SG_ 525 DynConf_Obj_25 "Dynamic property confidence of object_25";
CM_ SG_ 525 DynProp_Obj_24 "Dynamic property of object_24";
CM_ SG_ 525 DynProp_Obj_25 "Dynamic property of object_25";
CM_ SG_ 525 ID_Obj_24 "ID of object_24";
CM_ SG_ 525 ID_Obj_25 "ID of object_25";
CM_ SG_ 525 Length_Obj_24 "Length of object_24";
CM_ SG_ 525 Length_Obj_25 "Length of object_25";
CM_ SG_ 525 LifeCycle_Obj_24 "Life cycle of object_24";
CM_ SG_ 525 LifeCycle_Obj_25 "Life cycle of object_25";
CM_ SG_ 525 MaintenanceState_Obj_24 "Maintenance state of object_24";
CM_ SG_ 525 MaintenanceState_Obj_25 "Maintenance state of object_25";
CM_ SG_ 525 MicroDopplerFlag_24 "Micro-Doppler flag of object_24";
CM_ SG_ 525 MicroDopplerFlag_25 "Micro-Doppler flag of object_25";
CM_ SG_ 525 MirrorProb_Obj_24 "Mirror probability of object_24";
CM_ SG_ 525 MirrorProb_Obj_25 "Mirror probability of object_25";
CM_ SG_ 525 ObstacleProb_Obj_24 "Obstacle probability of object_24";
CM_ SG_ 525 ObstacleProb_Obj_25 "Obstacle probability of object_25";
CM_ SG_ 525 Orientation_Obj_24 "Orientation of object_24";
CM_ SG_ 525 Orientation_Obj_25 "Orientation of object_25";
CM_ SG_ 525 OrientationStd_Obj_24 "Orientation standard deviation of object_24";
CM_ SG_ 525 OrientationStd_Obj_25 "Orientation standard deviation of object_25";
CM_ SG_ 525 ProbOfExist_Obj_24 "Existence probability of object_24";
CM_ SG_ 525 ProbOfExist_Obj_25 "Existence probability of object_25";
CM_ SG_ 525 RCS_Obj_24 "RCS of object_24";
CM_ SG_ 525 RCS_Obj_25 "RCS of object_25";
CM_ SG_ 525 RefPoint_Obj_24 "Reference point of object_24";
CM_ SG_ 525 RefPoint_Obj_25 "Reference point of object_25";
CM_ SG_ 525 VabsX_Obj_24 "Longitudinal absolution velocity over ground of object_24";
CM_ SG_ 525 VabsX_Obj_25 "Longitudinal absolution velocity over ground of object_25";
CM_ SG_ 525 VabsXStd_Obj_24 "Longitudinal absolution velocity standard deviation of object_24";
CM_ SG_ 525 VabsXStd_Obj_25 "Longitudinal absolution velocity standard deviation of object_25";
CM_ SG_ 525 VabsY_Obj_24 "Lateral absolution velocity over ground of object_24";
CM_ SG_ 525 VabsY_Obj_25 "Lateral absolution velocity over ground of object_25";
CM_ SG_ 525 VabsYStd_Obj_24 "Lateral absolution velocity standard deviation of object_24";
CM_ SG_ 525 VabsYStd_Obj_25 "Lateral absolution velocity standard deviation of object_25";
CM_ SG_ 525 Valid_Obj_24 "Valid flag of object_24";
CM_ SG_ 525 Valid_Obj_25 "Valid flag of object_25";
CM_ SG_ 525 Width_Obj_24 "Width of object_24";
CM_ SG_ 525 Width_Obj_25 "Width of object_25";
CM_ SG_ 525 YawRateAbs_Obj_24 "Yaw rate of object_24";
CM_ SG_ 525 YawRateAbs_Obj_25 "Yaw rate of object_25";
CM_ SG_ 525 YawRateAbsStd_Obj_24 "Yaw rate standard deviation of object_24";
CM_ SG_ 525 YawRateAbsStd_Obj_25 "Yaw rate standard deviation of object_25";
CM_ SG_ 526 AabsX_Obj_26 "Longitudinal absolution acceleration over ground of object_26";
CM_ SG_ 526 AabsX_Obj_27 "Longitudinal absolution acceleration over ground of object_27";
CM_ SG_ 526 AabsXStd_Obj_26 "Longitudinal absolution acceleration standard deviation of object_26";
CM_ SG_ 526 AabsXStd_Obj_27 "Longitudinal absolution acceleration standard deviation of object_27";
CM_ SG_ 526 AabsY_Obj_26 "Lateral absolution acceleration over ground of object_26";
CM_ SG_ 526 AabsY_Obj_27 "Lateral absolution acceleration over ground of object_27";
CM_ SG_ 526 AabsYStd_Obj_26 "Lateral absolution acceleration standard deviation of object_26";
CM_ SG_ 526 AabsYStd_Obj_27 "Lateral absolution acceleration standard deviation of object_27";
CM_ SG_ 526 ClassConf_Obj_26 "Classification confidence of object_26";
CM_ SG_ 526 ClassConf_Obj_27 "Classification confidence of object_27";
CM_ SG_ 526 Classification_Obj_26 "Classification of object_26";
CM_ SG_ 526 Classification_Obj_27 "Classification of object_27";
CM_ SG_ 526 DistX_Obj_26 "Longitudinal distance of object_26";
CM_ SG_ 526 DistX_Obj_27 "Longitudinal distance of object_27";
CM_ SG_ 526 DistXStd_Obj_26 "Longitudinal distance standard deviation of object_26";
CM_ SG_ 526 DistXStd_Obj_27 "Longitudinal distance standard deviation of object_27";
CM_ SG_ 526 DistY_Obj_26 "Lateral distance of object_26";
CM_ SG_ 526 DistY_Obj_27 "Lateral distance of object_27";
CM_ SG_ 526 DistYStd_Obj_26 "Lateral distance standard deviation of object_26";
CM_ SG_ 526 DistYStd_Obj_27 "Lateral distance standard deviation of object_27";
CM_ SG_ 526 DynConf_Obj_26 "Dynamic property confidence of object_26";
CM_ SG_ 526 DynConf_Obj_27 "Dynamic property confidence of object_27";
CM_ SG_ 526 DynProp_Obj_26 "Dynamic property of object_26";
CM_ SG_ 526 DynProp_Obj_27 "Dynamic property of object_27";
CM_ SG_ 526 ID_Obj_26 "ID of object_26";
CM_ SG_ 526 ID_Obj_27 "ID of object_27";
CM_ SG_ 526 Length_Obj_26 "Length of object_26";
CM_ SG_ 526 Length_Obj_27 "Length of object_27";
CM_ SG_ 526 LifeCycle_Obj_26 "Life cycle of object_26";
CM_ SG_ 526 LifeCycle_Obj_27 "Life cycle of object_27";
CM_ SG_ 526 MaintenanceState_Obj_26 "Maintenance state of object_26";
CM_ SG_ 526 MaintenanceState_Obj_27 "Maintenance state of object_27";
CM_ SG_ 526 MicroDopplerFlag_26 "Micro-Doppler flag of object_26";
CM_ SG_ 526 MicroDopplerFlag_27 "Micro-Doppler flag of object_27";
CM_ SG_ 526 MirrorProb_Obj_26 "Mirror probability of object_26";
CM_ SG_ 526 MirrorProb_Obj_27 "Mirror probability of object_27";
CM_ SG_ 526 ObstacleProb_Obj_26 "Obstacle probability of object_26";
CM_ SG_ 526 ObstacleProb_Obj_27 "Obstacle probability of object_27";
CM_ SG_ 526 Orientation_Obj_26 "Orientation of object_26";
CM_ SG_ 526 Orientation_Obj_27 "Orientation of object_27";
CM_ SG_ 526 OrientationStd_Obj_26 "Orientation standard deviation of object_26";
CM_ SG_ 526 OrientationStd_Obj_27 "Orientation standard deviation of object_27";
CM_ SG_ 526 ProbOfExist_Obj_26 "Existence probability of object_26";
CM_ SG_ 526 ProbOfExist_Obj_27 "Existence probability of object_27";
CM_ SG_ 526 RCS_Obj_26 "RCS of object_26";
CM_ SG_ 526 RCS_Obj_27 "RCS of object_27";
CM_ SG_ 526 RefPoint_Obj_26 "Reference point of object_26";
CM_ SG_ 526 RefPoint_Obj_27 "Reference point of object_27";
CM_ SG_ 526 VabsX_Obj_26 "Longitudinal absolution velocity over ground of object_26";
CM_ SG_ 526 VabsX_Obj_27 "Longitudinal absolution velocity over ground of object_27";
CM_ SG_ 526 VabsXStd_Obj_26 "Longitudinal absolution velocity standard deviation of object_26";
CM_ SG_ 526 VabsXStd_Obj_27 "Longitudinal absolution velocity standard deviation of object_27";
CM_ SG_ 526 VabsY_Obj_26 "Lateral absolution velocity over ground of object_26";
CM_ SG_ 526 VabsY_Obj_27 "Lateral absolution velocity over ground of object_27";
CM_ SG_ 526 VabsYStd_Obj_26 "Lateral absolution velocity standard deviation of object_26";
CM_ SG_ 526 VabsYStd_Obj_27 "Lateral absolution velocity standard deviation of object_27";
CM_ SG_ 526 Valid_Obj_26 "Valid flag of object_26";
CM_ SG_ 526 Valid_Obj_27 "Valid flag of object_27";
CM_ SG_ 526 Width_Obj_26 "Width of object_26";
CM_ SG_ 526 Width_Obj_27 "Width of object_27";
CM_ SG_ 526 YawRateAbs_Obj_26 "Yaw rate of object_26";
CM_ SG_ 526 YawRateAbs_Obj_27 "Yaw rate of object_27";
CM_ SG_ 526 YawRateAbsStd_Obj_26 "Yaw rate standard deviation of object_26";
CM_ SG_ 526 YawRateAbsStd_Obj_27 "Yaw rate standard deviation of object_27";
CM_ SG_ 527 AabsX_Obj_28 "Longitudinal absolution acceleration over ground of object_28";
CM_ SG_ 527 AabsX_Obj_29 "Longitudinal absolution acceleration over ground of object_29";
CM_ SG_ 527 AabsXStd_Obj_28 "Longitudinal absolution acceleration standard deviation of object_28";
CM_ SG_ 527 AabsXStd_Obj_29 "Longitudinal absolution acceleration standard deviation of object_29";
CM_ SG_ 527 AabsY_Obj_28 "Lateral absolution acceleration over ground of object_28";
CM_ SG_ 527 AabsY_Obj_29 "Lateral absolution acceleration over ground of object_29";
CM_ SG_ 527 AabsYStd_Obj_28 "Lateral absolution acceleration standard deviation of object_28";
CM_ SG_ 527 AabsYStd_Obj_29 "Lateral absolution acceleration standard deviation of object_29";
CM_ SG_ 527 ClassConf_Obj_28 "Classification confidence of object_28";
CM_ SG_ 527 ClassConf_Obj_29 "Classification confidence of object_29";
CM_ SG_ 527 Classification_Obj_28 "Classification of object_28";
CM_ SG_ 527 Classification_Obj_29 "Classification of object_29";
CM_ SG_ 527 DistX_Obj_28 "Longitudinal distance of object_28";
CM_ SG_ 527 DistX_Obj_29 "Longitudinal distance of object_29";
CM_ SG_ 527 DistXStd_Obj_28 "Longitudinal distance standard deviation of object_28";
CM_ SG_ 527 DistXStd_Obj_29 "Longitudinal distance standard deviation of object_29";
CM_ SG_ 527 DistY_Obj_28 "Lateral distance of object_28";
CM_ SG_ 527 DistY_Obj_29 "Lateral distance of object_29";
CM_ SG_ 527 DistYStd_Obj_28 "Lateral distance standard deviation of object_28";
CM_ SG_ 527 DistYStd_Obj_29 "Lateral distance standard deviation of object_29";
CM_ SG_ 527 DynConf_Obj_28 "Dynamic property confidence of object_28";
CM_ SG_ 527 DynConf_Obj_29 "Dynamic property confidence of object_29";
CM_ SG_ 527 DynProp_Obj_28 "Dynamic property of object_28";
CM_ SG_ 527 DynProp_Obj_29 "Dynamic property of object_29";
CM_ SG_ 527 ID_Obj_28 "ID of object_28";
CM_ SG_ 527 ID_Obj_29 "ID of object_29";
CM_ SG_ 527 Length_Obj_28 "Length of object_28";
CM_ SG_ 527 Length_Obj_29 "Length of object_29";
CM_ SG_ 527 LifeCycle_Obj_28 "Life cycle of object_28";
CM_ SG_ 527 LifeCycle_Obj_29 "Life cycle of object_29";
CM_ SG_ 527 MaintenanceState_Obj_28 "Maintenance state of object_28";
CM_ SG_ 527 MaintenanceState_Obj_29 "Maintenance state of object_29";
CM_ SG_ 527 MicroDopplerFlag_28 "Micro-Doppler flag of object_28";
CM_ SG_ 527 MicroDopplerFlag_29 "Micro-Doppler flag of object_29";
CM_ SG_ 527 MirrorProb_Obj_28 "Mirror probability of object_28";
CM_ SG_ 527 MirrorProb_Obj_29 "Mirror probability of object_29";
CM_ SG_ 527 ObstacleProb_Obj_28 "Obstacle probability of object_28";
CM_ SG_ 527 ObstacleProb_Obj_29 "Obstacle probability of object_29";
CM_ SG_ 527 Orientation_Obj_28 "Orientation of object_28";
CM_ SG_ 527 Orientation_Obj_29 "Orientation of object_29";
CM_ SG_ 527 OrientationStd_Obj_28 "Orientation standard deviation of object_28";
CM_ SG_ 527 OrientationStd_Obj_29 "Orientation standard deviation of object_29";
CM_ SG_ 527 ProbOfExist_Obj_28 "Existence probability of object_28";
CM_ SG_ 527 ProbOfExist_Obj_29 "Existence probability of object_29";
CM_ SG_ 527 RCS_Obj_28 "RCS of object_28";
CM_ SG_ 527 RCS_Obj_29 "RCS of object_29";
CM_ SG_ 527 RefPoint_Obj_28 "Reference point of object_28";
CM_ SG_ 527 RefPoint_Obj_29 "Reference point of object_29";
CM_ SG_ 527 VabsX_Obj_28 "Longitudinal absolution velocity over ground of object_28";
CM_ SG_ 527 VabsX_Obj_29 "Longitudinal absolution velocity over ground of object_29";
CM_ SG_ 527 VabsXStd_Obj_28 "Longitudinal absolution velocity standard deviation of object_28";
CM_ SG_ 527 VabsXStd_Obj_29 "Longitudinal absolution velocity standard deviation of object_29";
CM_ SG_ 527 VabsY_Obj_28 "Lateral absolution velocity over ground of object_28";
CM_ SG_ 527 VabsY_Obj_29 "Lateral absolution velocity over ground of object_29";
CM_ SG_ 527 VabsYStd_Obj_28 "Lateral absolution velocity standard deviation of object_28";
CM_ SG_ 527 VabsYStd_Obj_29 "Lateral absolution velocity standard deviation of object_29";
CM_ SG_ 527 Valid_Obj_28 "Valid flag of object_28";
CM_ SG_ 527 Valid_Obj_29 "Valid flag of object_29";
CM_ SG_ 527 Width_Obj_28 "Width of object_28";
CM_ SG_ 527 Width_Obj_29 "Width of object_29";
CM_ SG_ 527 YawRateAbs_Obj_28 "Yaw rate of object_28";
CM_ SG_ 527 YawRateAbs_Obj_29 "Yaw rate of object_29";
CM_ SG_ 527 YawRateAbsStd_Obj_28 "Yaw rate standard deviation of object_28";
CM_ SG_ 527 YawRateAbsStd_Obj_29 "Yaw rate standard deviation of object_29";
CM_ SG_ 528 AabsX_Obj_30 "Longitudinal absolution acceleration over ground of object_30";
CM_ SG_ 528 AabsX_Obj_31 "Longitudinal absolution acceleration over ground of object_31";
CM_ SG_ 528 AabsXStd_Obj_30 "Longitudinal absolution acceleration standard deviation of object_30";
CM_ SG_ 528 AabsXStd_Obj_31 "Longitudinal absolution acceleration standard deviation of object_31";
CM_ SG_ 528 AabsY_Obj_30 "Lateral absolution acceleration over ground of object_30";
CM_ SG_ 528 AabsY_Obj_31 "Lateral absolution acceleration over ground of object_31";
CM_ SG_ 528 AabsYStd_Obj_30 "Lateral absolution acceleration standard deviation of object_30";
CM_ SG_ 528 AabsYStd_Obj_31 "Lateral absolution acceleration standard deviation of object_31";
CM_ SG_ 528 ClassConf_Obj_30 "Classification confidence of object_30";
CM_ SG_ 528 ClassConf_Obj_31 "Classification confidence of object_31";
CM_ SG_ 528 Classification_Obj_30 "Classification of object_30";
CM_ SG_ 528 Classification_Obj_31 "Classification of object_31";
CM_ SG_ 528 DistX_Obj_30 "Longitudinal distance of object_30";
CM_ SG_ 528 DistX_Obj_31 "Longitudinal distance of object_31";
CM_ SG_ 528 DistXStd_Obj_30 "Longitudinal distance standard deviation of object_30";
CM_ SG_ 528 DistXStd_Obj_31 "Longitudinal distance standard deviation of object_31";
CM_ SG_ 528 DistY_Obj_30 "Lateral distance of object_30";
CM_ SG_ 528 DistY_Obj_31 "Lateral distance of object_31";
CM_ SG_ 528 DistYStd_Obj_30 "Lateral distance standard deviation of object_30";
CM_ SG_ 528 DistYStd_Obj_31 "Lateral distance standard deviation of object_31";
CM_ SG_ 528 DynConf_Obj_30 "Dynamic property confidence of object_30";
CM_ SG_ 528 DynConf_Obj_31 "Dynamic property confidence of object_31";
CM_ SG_ 528 DynProp_Obj_30 "Dynamic property of object_30";
CM_ SG_ 528 DynProp_Obj_31 "Dynamic property of object_31";
CM_ SG_ 528 ID_Obj_30 "ID of object_30";
CM_ SG_ 528 ID_Obj_31 "ID of object_31";
CM_ SG_ 528 Length_Obj_30 "Length of object_30";
CM_ SG_ 528 Length_Obj_31 "Length of object_31";
CM_ SG_ 528 LifeCycle_Obj_30 "Life cycle of object_30";
CM_ SG_ 528 LifeCycle_Obj_31 "Life cycle of object_31";
CM_ SG_ 528 MaintenanceState_Obj_30 "Maintenance state of object_30";
CM_ SG_ 528 MaintenanceState_Obj_31 "Maintenance state of object_31";
CM_ SG_ 528 MicroDopplerFlag_30 "Micro-Doppler flag of object_30";
CM_ SG_ 528 MicroDopplerFlag_31 "Micro-Doppler flag of object_31";
CM_ SG_ 528 MirrorProb_Obj_30 "Mirror probability of object_30";
CM_ SG_ 528 MirrorProb_Obj_31 "Mirror probability of object_31";
CM_ SG_ 528 ObstacleProb_Obj_30 "Obstacle probability of object_30";
CM_ SG_ 528 ObstacleProb_Obj_31 "Obstacle probability of object_31";
CM_ SG_ 528 Orientation_Obj_30 "Orientation of object_30";
CM_ SG_ 528 Orientation_Obj_31 "Orientation of object_31";
CM_ SG_ 528 OrientationStd_Obj_30 "Orientation standard deviation of object_30";
CM_ SG_ 528 OrientationStd_Obj_31 "Orientation standard deviation of object_31";
CM_ SG_ 528 ProbOfExist_Obj_30 "Existence probability of object_30";
CM_ SG_ 528 ProbOfExist_Obj_31 "Existence probability of object_31";
CM_ SG_ 528 RCS_Obj_30 "RCS of object_30";
CM_ SG_ 528 RCS_Obj_31 "RCS of object_31";
CM_ SG_ 528 RefPoint_Obj_30 "Reference point of object_30";
CM_ SG_ 528 RefPoint_Obj_31 "Reference point of object_31";
CM_ SG_ 528 VabsX_Obj_30 "Longitudinal absolution velocity over ground of object_30";
CM_ SG_ 528 VabsX_Obj_31 "Longitudinal absolution velocity over ground of object_31";
CM_ SG_ 528 VabsXStd_Obj_30 "Longitudinal absolution velocity standard deviation of object_30";
CM_ SG_ 528 VabsXStd_Obj_31 "Longitudinal absolution velocity standard deviation of object_31";
CM_ SG_ 528 VabsY_Obj_30 "Lateral absolution velocity over ground of object_30";
CM_ SG_ 528 VabsY_Obj_31 "Lateral absolution velocity over ground of object_31";
CM_ SG_ 528 VabsYStd_Obj_30 "Lateral absolution velocity standard deviation of object_30";
CM_ SG_ 528 VabsYStd_Obj_31 "Lateral absolution velocity standard deviation of object_31";
CM_ SG_ 528 Valid_Obj_30 "Valid flag of object_30";
CM_ SG_ 528 Valid_Obj_31 "Valid flag of object_31";
CM_ SG_ 528 Width_Obj_30 "Width of object_30";
CM_ SG_ 528 Width_Obj_31 "Width of object_31";
CM_ SG_ 528 YawRateAbs_Obj_30 "Yaw rate of object_30";
CM_ SG_ 528 YawRateAbs_Obj_31 "Yaw rate of object_31";
CM_ SG_ 528 YawRateAbsStd_Obj_30 "Yaw rate standard deviation of object_30";
CM_ SG_ 528 YawRateAbsStd_Obj_31 "Yaw rate standard deviation of object_31";
CM_ SG_ 574 GW_EgoBrakePedal "BrakePedal";
CM_ SG_ 574 GW_EgoCurvature "Ego curvature filtered by Radar Algorithm";
CM_ SG_ 574 GW_EgoDoorStateLF "DoorStateLF";
CM_ SG_ 574 GW_EgoDoorStateLR "DoorStateLR";
CM_ SG_ 574 GW_EgoDoorStateRF "DoorStateRF";
CM_ SG_ 574 GW_EgoDoorStateRR "DoorStateRR";
CM_ SG_ 574 GW_EgoDoorStateTrunk "DoorStateTrunk";
CM_ SG_ 574 GW_EgoGasPedal "GasPedal";
CM_ SG_ 574 GW_EgoGear "Ego gear filtered by Radar Algorithm";
CM_ SG_ 574 GW_EgoLatAcceleration "Ego longitudinal acceleration filtered by Radar Algorithm";
CM_ SG_ 574 GW_EgoLongAcceleration "Ego lateral acceleration filtered by Radar Algorithm";
CM_ SG_ 574 GW_EgoSteeringDirection "SteeringDirection";
CM_ SG_ 574 GW_EgoSteeringLamp "SteeringLamp";
CM_ SG_ 574 GW_EgoVelocity "EgoVelocity";
CM_ SG_ 574 GW_EgoYawRate "Ego yaw rate filtered by Radar Algorithm";
CM_ SG_ 575 ClothoidParam_1_Left "Parameter 1 of 3rd-order cloithoid for road model";
CM_ SG_ 575 ClothoidParam_1_Right "Parameter 1 of 3rd-order cloithoid for road model";
CM_ SG_ 575 ClothoidParam_2_Left "Parameter 2 of 3rd-order cloithoid for road model";
CM_ SG_ 575 ClothoidParam_2_Right "Parameter 2 of 3rd-order cloithoid for road model";
CM_ SG_ 575 ClothoidParam_3_Left "Parameter 3 of 3rd-order cloithoid for road model";
CM_ SG_ 575 ClothoidParam_3_Right "Parameter 3 of 3rd-order cloithoid for road model";
CM_ SG_ 575 Confidence_Left "Condidence left curve";
CM_ SG_ 575 Confidence_Right "Condidence right curve";
CM_ SG_ 575 LatOffset_Left "Lateral offset of left curve";
CM_ SG_ 575 LatOffset_Right "Lateral offset of right curve";
CM_ SG_ 575 NofLane_Left "NofLane_Left";
CM_ SG_ 575 NofLane_Right "Number of lanes on the right to the ego lane";
CM_ SG_ 575 NofLaneProb_Left "Probability of number of lanes on the left to the ego lane";
CM_ SG_ 575 NofLaneProb_Right "Probability of number of lanes on the right to the ego lane";
CM_ SG_ 575 RoadType "Road type";
CM_ SG_ 575 RoadTypeConf "Road type confidence";
CM_ SG_ 575 Xend_Left "Longitudinal end of left curve";
CM_ SG_ 575 Xend_Right "Longitudinal end of right curve";
CM_ SG_ 575 Xstart_Left "Longitudinal start of left curve";
CM_ SG_ 575 Xstart_Right "Longitudinal start of right curve";
BA_DEF_ BO_  "GenMsgCycleTime" INT 0 0;
BA_DEF_ BO_  "GenMsgSendType" ENUM  "Cyclic","NotUsed","Event","NotUsed","NotUsed","NotUsed","NotUsed","IfActive","NoMsgSendType","NotUsed";
BA_DEF_ BO_  "VFrameFormat" ENUM  "StandardCAN","ExtendedCAN","reserved","reserved","reserved","reserved","reserved","reserved","reserved","reserved","reserved","reserved","reserved","reserved","StandardCAN_FD","ExtendedCAN_FD";
BA_DEF_ BO_  "GenSigSendType" ENUM  "Cyclic","OnWrite","OnWriteWithRepetition","OnChange","OnChangeWithRepetition";
BA_DEF_ SG_  "GenSigStartValue" INT 0 0;
BA_DEF_ BO_  "CANFD_BRS" ENUM  "0","1";
BA_DEF_DEF_  "GenMsgCycleTime" 0;
BA_DEF_DEF_  "GenMsgSendType" "Cyclic";
BA_DEF_DEF_  "VFrameFormat" "ExtendedCAN_FD";
BA_DEF_DEF_  "GenSigSendType" "Cyclic";
BA_DEF_DEF_  "GenSigStartValue" 0;
BA_DEF_DEF_  "CANFD_BRS" "1";
BA_ "GenMsgSendType" BO_ 521 2;
BA_ "VFrameFormat" BO_ 521 14;
BA_ "GenMsgSendType" BO_ 522 2;
BA_ "VFrameFormat" BO_ 522 14;
BA_ "GenMsgSendType" BO_ 523 2;
BA_ "VFrameFormat" BO_ 523 14;
BA_ "GenMsgSendType" BO_ 524 2;
BA_ "VFrameFormat" BO_ 524 14;
BA_ "GenMsgSendType" BO_ 525 2;
BA_ "VFrameFormat" BO_ 525 14;
BA_ "GenMsgSendType" BO_ 526 2;
BA_ "VFrameFormat" BO_ 526 14;
BA_ "GenMsgSendType" BO_ 527 2;
BA_ "VFrameFormat" BO_ 527 14;
BA_ "GenMsgSendType" BO_ 528 2;
BA_ "VFrameFormat" BO_ 528 14;
BA_ "VFrameFormat" BO_ 544 14;
BA_ "VFrameFormat" BO_ 545 14;
BA_ "VFrameFormat" BO_ 546 14;
BA_ "VFrameFormat" BO_ 547 14;
BA_ "VFrameFormat" BO_ 548 14;
BA_ "VFrameFormat" BO_ 549 14;
BA_ "VFrameFormat" BO_ 550 14;
BA_ "VFrameFormat" BO_ 551 14;
BA_ "VFrameFormat" BO_ 552 14;
BA_ "VFrameFormat" BO_ 553 14;
BA_ "VFrameFormat" BO_ 554 14;
BA_ "VFrameFormat" BO_ 555 14;
BA_ "VFrameFormat" BO_ 556 14;
BA_ "VFrameFormat" BO_ 557 14;
BA_ "VFrameFormat" BO_ 558 14;
BA_ "VFrameFormat" BO_ 559 14;
BA_ "VFrameFormat" BO_ 560 14;
BA_ "GenMsgSendType" BO_ 573 2;
BA_ "VFrameFormat" BO_ 573 14;
BA_ "GenMsgSendType" BO_ 574 2;
BA_ "VFrameFormat" BO_ 574 14;
BA_ "GenMsgSendType" BO_ 575 2;
BA_ "VFrameFormat" BO_ 575 14;
BA_ "GenMsgSendType" BO_ 1952 2;
BA_ "VFrameFormat" BO_ 1952 14;
BA_ "GenMsgSendType" BO_ 1953 2;
BA_ "VFrameFormat" BO_ 1953 14;
BA_ "GenMsgSendType" BO_ 2000 2;
BA_ "VFrameFormat" BO_ 2000 14;
BA_ "GenMsgSendType" BO_ 2001 2;
BA_ "VFrameFormat" BO_ 2001 14;
BA_ "GenSigStartValue" SG_ 574 GW_EgoYawRate 2048;
VAL_ 521 Classification_Obj_16 0 "POINT" 1 "CAR" 2 "TRUCK" 3 "PEDESTRIAN" 4 "MOTORCYCLE" 5 "BICYCLE" 6 "WIDE" 7 "UNCLASSIFIED" ;
VAL_ 521 Classification_Obj_17 0 "POINT" 1 "CAR" 2 "TRUCK" 3 "PEDESTRIAN" 4 "MOTORCYCLE" 5 "BICYCLE" 6 "WIDE" 7 "UNCLASSIFIED" ;
VAL_ 521 DynProp_Obj_16 0 "MOVING" 1 "STATIONARY" 2 "ONCOMING" 3 "CROSSING_LEFT2RIGHT" 4 "CROSSING_RIGHT2LEFT" 5 "UNKNOWN" 6 "STOPPED" 7 "RESERVED" ;
VAL_ 521 DynProp_Obj_17 0 "STATIONAR" 1 "MOVIN" 2 "ONCOMING" 3 "STOPPE" 4 "CROSSING_LEFT2RIGH" 5 "CROSSING_RIGHT2LEF" 6 "RESERVE" 7 "RESERVED" ;
VAL_ 521 MaintenanceState_Obj_16 0 "INVALID" 1 "NEW" 2 "MEASURED" 3 "PREDICTED" ;
VAL_ 521 MaintenanceState_Obj_17 0 "INVALID" 1 "NEW" 2 "MEASURED" 3 "PREDICTED" ;
VAL_ 521 MicroDopplerFlag_16 0 "FALSE" 1 "TRUE" ;
VAL_ 521 MicroDopplerFlag_17 0 "FALSE" 1 "TRUE" ;
VAL_ 521 RefPoint_Obj_16 0 "REAR" 1 "LEFT" 2 "FRONT" 3 "RIGHT" ;
VAL_ 521 RefPoint_Obj_17 0 "REAR" 1 "LEFT" 2 "FRONT" 3 "RIGHT" ;
VAL_ 522 Classification_Obj_18 0 "POINT" 1 "CAR" 2 "TRUCK" 3 "PEDESTRIAN" 4 "MOTORCYCLE" 5 "BICYCLE" 6 "WIDE" 7 "UNCLASSIFIED" ;
VAL_ 522 Classification_Obj_19 0 "POINT" 1 "CAR" 2 "TRUCK" 3 "PEDESTRIAN" 4 "MOTORCYCLE" 5 "BICYCLE" 6 "WIDE" 7 "UNCLASSIFIED" ;
VAL_ 522 DynProp_Obj_18 0 "MOVING" 1 "STATIONARY" 2 "ONCOMING" 3 "CROSSING_LEFT2RIGHT" 4 "CROSSING_RIGHT2LEFT" 5 "UNKNOWN" 6 "STOPPED" 7 "RESERVED" ;
VAL_ 522 DynProp_Obj_19 0 "STATIONAR" 1 "MOVIN" 2 "ONCOMING" 3 "STOPPE" 4 "CROSSING_LEFT2RIGH" 5 "CROSSING_RIGHT2LEF" 6 "RESERVE" 7 "RESERVED" ;
VAL_ 522 MaintenanceState_Obj_18 0 "INVALID" 1 "NEW" 2 "MEASURED" 3 "PREDICTED" ;
VAL_ 522 MaintenanceState_Obj_19 0 "INVALID" 1 "NEW" 2 "MEASURED" 3 "PREDICTED" ;
VAL_ 522 MicroDopplerFlag_18 0 "FALSE" 1 "TRUE" ;
VAL_ 522 MicroDopplerFlag_19 0 "FALSE" 1 "TRUE" ;
VAL_ 522 RefPoint_Obj_18 0 "REAR" 1 "LEFT" 2 "FRONT" 3 "RIGHT" ;
VAL_ 522 RefPoint_Obj_19 0 "REAR" 1 "LEFT" 2 "FRONT" 3 "RIGHT" ;
VAL_ 523 Classification_Obj_20 0 "POINT" 1 "CAR" 2 "TRUCK" 3 "PEDESTRIAN" 4 "MOTORCYCLE" 5 "BICYCLE" 6 "WIDE" 7 "UNCLASSIFIED" ;
VAL_ 523 Classification_Obj_21 0 "POINT" 1 "CAR" 2 "TRUCK" 3 "PEDESTRIAN" 4 "MOTORCYCLE" 5 "BICYCLE" 6 "WIDE" 7 "UNCLASSIFIED" ;
VAL_ 523 DynProp_Obj_20 0 "MOVING" 1 "STATIONARY" 2 "ONCOMING" 3 "CROSSING_LEFT2RIGHT" 4 "CROSSING_RIGHT2LEFT" 5 "UNKNOWN" 6 "STOPPED" 7 "RESERVED" ;
VAL_ 523 DynProp_Obj_21 0 "STATIONAR" 1 "MOVIN" 2 "ONCOMING" 3 "STOPPE" 4 "CROSSING_LEFT2RIGH" 5 "CROSSING_RIGHT2LEF" 6 "RESERVE" 7 "RESERVED" ;
VAL_ 523 MaintenanceState_Obj_20 0 "INVALID" 1 "NEW" 2 "MEASURED" 3 "PREDICTED" ;
VAL_ 523 MaintenanceState_Obj_21 0 "INVALID" 1 "NEW" 2 "MEASURED" 3 "PREDICTED" ;
VAL_ 523 MicroDopplerFlag_20 0 "FALSE" 1 "TRUE" ;
VAL_ 523 MicroDopplerFlag_21 0 "FALSE" 1 "TRUE" ;
VAL_ 523 RefPoint_Obj_20 0 "REAR" 1 "LEFT" 2 "FRONT" 3 "RIGHT" ;
VAL_ 523 RefPoint_Obj_21 0 "REAR" 1 "LEFT" 2 "FRONT" 3 "RIGHT" ;
VAL_ 524 Classification_Obj_22 0 "POINT" 1 "CAR" 2 "TRUCK" 3 "PEDESTRIAN" 4 "MOTORCYCLE" 5 "BICYCLE" 6 "WIDE" 7 "UNCLASSIFIED" ;
VAL_ 524 Classification_Obj_23 0 "POINT" 1 "CAR" 2 "TRUCK" 3 "PEDESTRIAN" 4 "MOTORCYCLE" 5 "BICYCLE" 6 "WIDE" 7 "UNCLASSIFIED" ;
VAL_ 524 DynProp_Obj_22 0 "MOVING" 1 "STATIONARY" 2 "ONCOMING" 3 "CROSSING_LEFT2RIGHT" 4 "CROSSING_RIGHT2LEFT" 5 "UNKNOWN" 6 "STOPPED" 7 "RESERVED" ;
VAL_ 524 DynProp_Obj_23 0 "STATIONAR" 1 "MOVIN" 2 "ONCOMING" 3 "STOPPE" 4 "CROSSING_LEFT2RIGH" 5 "CROSSING_RIGHT2LEF" 6 "RESERVE" 7 "RESERVED" ;
VAL_ 524 MaintenanceState_Obj_22 0 "INVALID" 1 "NEW" 2 "MEASURED" 3 "PREDICTED" ;
VAL_ 524 MaintenanceState_Obj_23 0 "INVALID" 1 "NEW" 2 "MEASURED" 3 "PREDICTED" ;
VAL_ 524 MicroDopplerFlag_22 0 "FALSE" 1 "TRUE" ;
VAL_ 524 MicroDopplerFlag_23 0 "FALSE" 1 "TRUE" ;
VAL_ 524 RefPoint_Obj_22 0 "REAR" 1 "LEFT" 2 "FRONT" 3 "RIGHT" ;
VAL_ 524 RefPoint_Obj_23 0 "REAR" 1 "LEFT" 2 "FRONT" 3 "RIGHT" ;
VAL_ 525 Classification_Obj_24 0 "POINT" 1 "CAR" 2 "TRUCK" 3 "PEDESTRIAN" 4 "MOTORCYCLE" 5 "BICYCLE" 6 "WIDE" 7 "UNCLASSIFIED" ;
VAL_ 525 Classification_Obj_25 0 "POINT" 1 "CAR" 2 "TRUCK" 3 "PEDESTRIAN" 4 "MOTORCYCLE" 5 "BICYCLE" 6 "WIDE" 7 "UNCLASSIFIED" ;
VAL_ 525 DynProp_Obj_24 0 "MOVING" 1 "STATIONARY" 2 "ONCOMING" 3 "CROSSING_LEFT2RIGHT" 4 "CROSSING_RIGHT2LEFT" 5 "UNKNOWN" 6 "STOPPED" 7 "RESERVED" ;
VAL_ 525 DynProp_Obj_25 0 "STATIONAR" 1 "MOVIN" 2 "ONCOMING" 3 "STOPPE" 4 "CROSSING_LEFT2RIGH" 5 "CROSSING_RIGHT2LEF" 6 "RESERVE" 7 "RESERVED" ;
VAL_ 525 MaintenanceState_Obj_24 0 "INVALID" 1 "NEW" 2 "MEASURED" 3 "PREDICTED" ;
VAL_ 525 MaintenanceState_Obj_25 0 "INVALID" 1 "NEW" 2 "MEASURED" 3 "PREDICTED" ;
VAL_ 525 MicroDopplerFlag_24 0 "FALSE" 1 "TRUE" ;
VAL_ 525 MicroDopplerFlag_25 0 "FALSE" 1 "TRUE" ;
VAL_ 525 RefPoint_Obj_24 0 "REAR" 1 "LEFT" 2 "FRONT" 3 "RIGHT" ;
VAL_ 525 RefPoint_Obj_25 0 "REAR" 1 "LEFT" 2 "FRONT" 3 "RIGHT" ;
VAL_ 526 Classification_Obj_26 0 "POINT" 1 "CAR" 2 "TRUCK" 3 "PEDESTRIAN" 4 "MOTORCYCLE" 5 "BICYCLE" 6 "WIDE" 7 "UNCLASSIFIED" ;
VAL_ 526 Classification_Obj_27 0 "POINT" 1 "CAR" 2 "TRUCK" 3 "PEDESTRIAN" 4 "MOTORCYCLE" 5 "BICYCLE" 6 "WIDE" 7 "UNCLASSIFIED" ;
VAL_ 526 DynProp_Obj_26 0 "MOVING" 1 "STATIONARY" 2 "ONCOMING" 3 "CROSSING_LEFT2RIGHT" 4 "CROSSING_RIGHT2LEFT" 5 "UNKNOWN" 6 "STOPPED" 7 "RESERVED" ;
VAL_ 526 DynProp_Obj_27 0 "STATIONAR" 1 "MOVIN" 2 "ONCOMING" 3 "STOPPE" 4 "CROSSING_LEFT2RIGH" 5 "CROSSING_RIGHT2LEF" 6 "RESERVE" 7 "RESERVED" ;
VAL_ 526 MaintenanceState_Obj_26 0 "INVALID" 1 "NEW" 2 "MEASURED" 3 "PREDICTED" ;
VAL_ 526 MaintenanceState_Obj_27 0 "INVALID" 1 "NEW" 2 "MEASURED" 3 "PREDICTED" ;
VAL_ 526 MicroDopplerFlag_26 0 "FALSE" 1 "TRUE" ;
VAL_ 526 MicroDopplerFlag_27 0 "FALSE" 1 "TRUE" ;
VAL_ 526 RefPoint_Obj_26 0 "REAR" 1 "LEFT" 2 "FRONT" 3 "RIGHT" ;
VAL_ 526 RefPoint_Obj_27 0 "REAR" 1 "LEFT" 2 "FRONT" 3 "RIGHT" ;
VAL_ 527 Classification_Obj_28 0 "POINT" 1 "CAR" 2 "TRUCK" 3 "PEDESTRIAN" 4 "MOTORCYCLE" 5 "BICYCLE" 6 "WIDE" 7 "UNCLASSIFIED" ;
VAL_ 527 Classification_Obj_29 0 "POINT" 1 "CAR" 2 "TRUCK" 3 "PEDESTRIAN" 4 "MOTORCYCLE" 5 "BICYCLE" 6 "WIDE" 7 "UNCLASSIFIED" ;
VAL_ 527 DynProp_Obj_28 0 "MOVING" 1 "STATIONARY" 2 "ONCOMING" 3 "CROSSING_LEFT2RIGHT" 4 "CROSSING_RIGHT2LEFT" 5 "UNKNOWN" 6 "STOPPED" 7 "RESERVED" ;
VAL_ 527 DynProp_Obj_29 0 "STATIONAR" 1 "MOVIN" 2 "ONCOMING" 3 "STOPPE" 4 "CROSSING_LEFT2RIGH" 5 "CROSSING_RIGHT2LEF" 6 "RESERVE" 7 "RESERVED" ;
VAL_ 527 MaintenanceState_Obj_28 0 "INVALID" 1 "NEW" 2 "MEASURED" 3 "PREDICTED" ;
VAL_ 527 MaintenanceState_Obj_29 0 "INVALID" 1 "NEW" 2 "MEASURED" 3 "PREDICTED" ;
VAL_ 527 MicroDopplerFlag_28 0 "FALSE" 1 "TRUE" ;
VAL_ 527 MicroDopplerFlag_29 0 "FALSE" 1 "TRUE" ;
VAL_ 527 RefPoint_Obj_28 0 "REAR" 1 "LEFT" 2 "FRONT" 3 "RIGHT" ;
VAL_ 527 RefPoint_Obj_29 0 "REAR" 1 "LEFT" 2 "FRONT" 3 "RIGHT" ;
VAL_ 528 Classification_Obj_30 0 "POINT" 1 "CAR" 2 "TRUCK" 3 "PEDESTRIAN" 4 "MOTORCYCLE" 5 "BICYCLE" 6 "WIDE" 7 "UNCLASSIFIED" ;
VAL_ 528 Classification_Obj_31 0 "POINT" 1 "CAR" 2 "TRUCK" 3 "PEDESTRIAN" 4 "MOTORCYCLE" 5 "BICYCLE" 6 "WIDE" 7 "UNCLASSIFIED" ;
VAL_ 528 DynProp_Obj_30 0 "MOVING" 1 "STATIONARY" 2 "ONCOMING" 3 "CROSSING_LEFT2RIGHT" 4 "CROSSING_RIGHT2LEFT" 5 "UNKNOWN" 6 "STOPPED" 7 "RESERVED" ;
VAL_ 528 DynProp_Obj_31 0 "STATIONAR" 1 "MOVIN" 2 "ONCOMING" 3 "STOPPE" 4 "CROSSING_LEFT2RIGH" 5 "CROSSING_RIGHT2LEF" 6 "RESERVE" 7 "RESERVED" ;
VAL_ 528 MaintenanceState_Obj_30 0 "INVALID" 1 "NEW" 2 "MEASURED" 3 "PREDICTED" ;
VAL_ 528 MaintenanceState_Obj_31 0 "INVALID" 1 "NEW" 2 "MEASURED" 3 "PREDICTED" ;
VAL_ 528 MicroDopplerFlag_30 0 "FALSE" 1 "TRUE" ;
VAL_ 528 MicroDopplerFlag_31 0 "FALSE" 1 "TRUE" ;
VAL_ 528 RefPoint_Obj_30 0 "REAR" 1 "LEFT" 2 "FRONT" 3 "RIGHT" ;
VAL_ 528 RefPoint_Obj_31 0 "REAR" 1 "LEFT" 2 "FRONT" 3 "RIGHT" ;
VAL_ 573 DPMode_Cmd 1 "Parking Mode" 0 "Driving Mode" ;
VAL_ 575 RoadType 0 " UNKNOW" 1 " CIT" 2 " COUNTR" 3 " HIGHWA" ;
